VERSION "HNPBNNNYNNNNNNNNNNNNNNNNNNNNNNNNYNYYYYYYYY>4>%%%/4>'%**4YYY///"

NS_ :

BS_:

BU_: TPM TCM SCCM RF_HUB PTS ORC IC HaLF ETM ESM ESC EPS ECM Diagnost DTCM DASM CBC AFLS ADCM

BO_ 368 TRNS_STAT: 8 ECM
 SG_ PaddlesModeSts : 0|2@1+ (1,0) [0|0] ""  ESM,DASM,IC,CBC
 SG_ PRND_STAT : 2|3@1+ (1,0) [0|0] ""  HaLF,ORC,ESM,ECM,DASM,ESC,EPS,AFLS,TPM,PTS,IC,CBC,RF_HUB
 SG_ APCM_Rq : 5|2@1+ (1,0) [0|0] ""  IC
 SG_ EngStEnblRqTCM : 7|1@1+ (1,0) [0|0] ""  ECM
 SG_ SHFT_PROG : 8|8@1+ (1,0) [0|0] ""  ECM,DASM,ESC,IC,CBC
 SG_ PRNDL_DISP : 16|8@1+ (1,0) [0|0] ""  DTCM,ESM,ECM,ESC,IC,CBC
 SG_ R_SHFT_LOCK : 24|1@1+ (1,0) [0|0] ""  ESM
 SG_ TX_D_POSSIBLE : 25|1@1+ (1,0) [0|0] ""  IC
 SG_ TX_M_POSSIBLE : 28|1@1+ (1,0) [0|0] ""  IC
 SG_ SHFT_LOCK : 29|1@1+ (1,0) [0|0] ""  ESM
 SG_ SHFT_RESET : 30|1@1+ (1,0) [0|0] "" Vector__XXX
 SG_ SHFT_HS_TCM_VALID : 31|1@1+ (1,0) [0|0] "" Vector__XXX
 SG_ SHFT_HS1_TCM : 32|8@1+ (1,0) [0|0] "" Vector__XXX
 SG_ SHFT_HS2_TCM : 40|8@1+ (1,0) [0|0] "" Vector__XXX
 SG_ TxDisengaged : 48|1@1+ (1,0) [0|0] ""  ECM
 SG_ PRNDL_Blink : 49|3@1+ (1,0) [0|0] ""  ESM,ECM,IC
 SG_ MC_TRNS_STAT : 52|4@1+ (1,0) [0|15] ""  ORC,ESM,ECM,DASM
 SG_ CRC_TRNS_STAT : 56|8@1+ (1,0) [0|0] ""  ORC,ESM,ECM,DASM

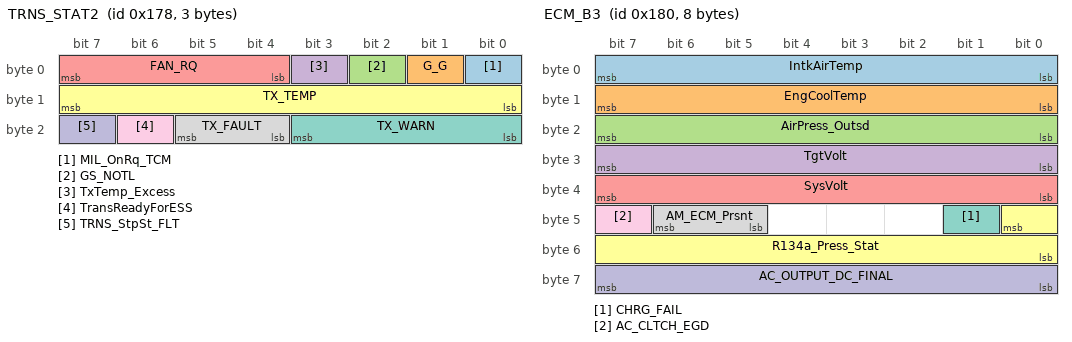
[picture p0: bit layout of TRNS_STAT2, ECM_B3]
BO_ 376 TRNS_STAT2: 3 ECM
 SG_ MIL_OnRq_TCM : 0|1@1+ (1,0) [0|0] ""  ECM,DASM,IC
 SG_ G_G : 1|1@1+ (1,0) [0|0] ""  ECM
 SG_ GS_NOTL : 2|1@1+ (1,0) [0|0] ""  ORC,ECM,DASM
 SG_ TxTemp_Excess : 3|1@1+ (1,0) [0|0] ""  ETM,ECM,IC
 SG_ FAN_RQ : 4|4@1+ (7.2,0) [0|100] "%"  ECM
 SG_ TX_TEMP : 8|8@1+ (1,-50) [-50|204] "°C"  ETM,DTCM,ECM,IC,CBC
 SG_ TX_WARN : 16|4@1+ (1,0) [0|0] ""  IC
 SG_ TX_FAULT : 20|2@1+ (1,0) [0|0] ""  ESM,RF_HUB
 SG_ TransReadyForESS : 22|1@1+ (1,0) [0|0] ""  ECM
 SG_ TRNS_StpSt_FLT : 23|1@1+ (1,0) [0|0] ""  ECM

BO_ 384 ECM_B3: 8 ECM
 SG_ IntkAirTemp : 0|8@1+ (1,-40) [-40|214] "°C"  ETM,ECM,CBC
 SG_ EngCoolTemp : 8|8@1+ (1,-40) [-40|214] "°C"  DTCM,TCM,ECM,ESC,PTS,IC,CBC
 SG_ AirPress_Outsd : 16|8@1+ (1,0) [0|254] "kPaA"  ETM,TCM,ECM,DASM,ESC,TPM,IC,RF_HUB
 SG_ TgtVolt : 24|8@1+ (0.0618,0) [0|15.6972] "Volts" Vector__XXX
 SG_ SysVolt : 32|8@1+ (0.0618,0) [0|15.6972] "Volts"  CBC
 SG_ R134a_Press_Stat : 40|9@0+ (0.1,0) [0|40] "bar"  CBC
 SG_ CHRG_FAIL : 41|1@1+ (1,0) [0|0] ""  ETM,ORC,IC
 SG_ AM_ECM_Prsnt : 45|2@1+ (1,0) [0|0] ""  CBC
 SG_ AC_CLTCH_EGD : 47|1@1+ (1,0) [0|0] ""  TCM,DASM,CBC
 SG_ AC_OUTPUT_DC_FINAL : 56|8@1+ (1,0) [0|100] "%"  CBC

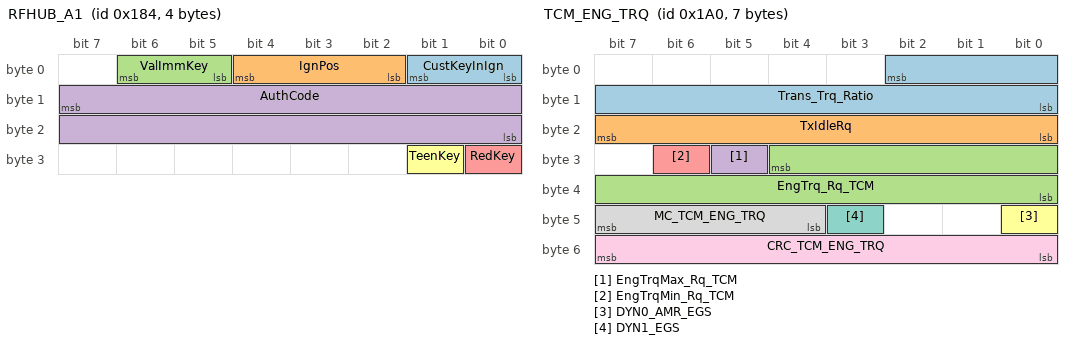
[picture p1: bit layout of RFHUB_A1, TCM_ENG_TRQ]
BO_ 388 RFHUB_A1: 4 RF_HUB
 SG_ CustKeyInIgn : 0|2@1+ (1,0) [0|0] ""  CBC
 SG_ IgnPos : 2|3@1+ (1,0) [0|0] ""  CBC
 SG_ ValImmKey : 5|2@1+ (1,0) [0|0] ""  CBC
 SG_ AuthCode : 15|16@0+ (1,0) [0|0] ""  CBC
 SG_ RedKey : 24|1@1+ (1,0) [0|0] ""  CBC
 SG_ TeenKey : 25|1@1+ (1,0) [0|0] ""  CBC

BO_ 416 TCM_ENG_TRQ: 7 ECM
 SG_ Trans_Trq_Ratio : 2|11@0+ (0.01,0) [0|20.46] ""  ECM,DASM,ESC
 SG_ TxIdleRq : 16|8@1+ (4,500) [500|1516] "rpm"  ECM,DASM,ESC
 SG_ EngTrq_Rq_TCM : 28|13@0+ (0.25,-500) [-500|1547.5] "Nm"  ECM,DASM,ESC
 SG_ EngTrqMax_Rq_TCM : 29|1@1+ (1,0) [0|0] ""  ECM,DASM,ESC
 SG_ EngTrqMin_Rq_TCM : 30|1@1+ (1,0) [0|0] ""  ECM,DASM,ESC
 SG_ DYN0_AMR_EGS : 40|1@1+ (1,0) [0|0] ""  ECM,DASM,ESC
 SG_ DYN1_EGS : 43|1@1+ (1,0) [0|0] ""  ECM,DASM,ESC
 SG_ MC_TCM_ENG_TRQ : 44|4@1+ (1,0) [0|15] ""  ECM,DASM,ESC
 SG_ CRC_TCM_ENG_TRQ : 48|8@1+ (1,0) [0|0] ""  ECM,DASM,ESC

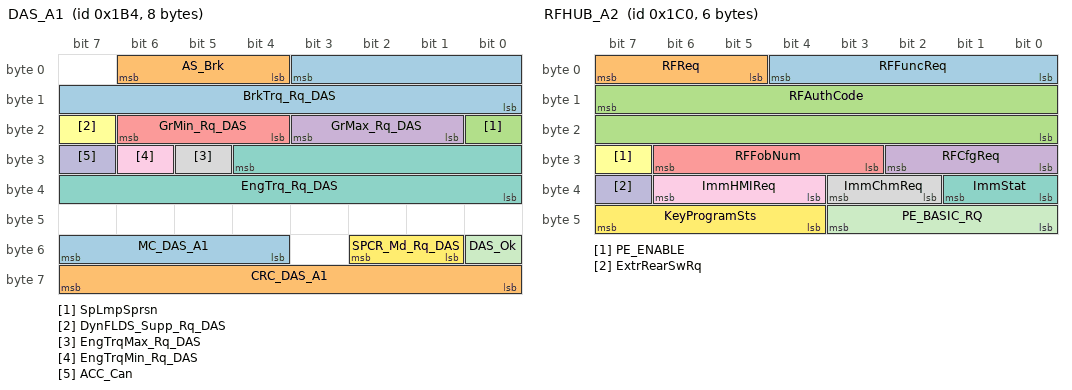
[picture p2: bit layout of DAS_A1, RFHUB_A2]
BO_ 436 DAS_A1: 8 Vector__XXX
 SG_ BrkTrq_Rq_DAS : 3|12@0+ (3,0) [0|12282] "Nm"  ESC
 SG_ AS_Brk : 4|3@1+ (1,0) [0|0] ""  ORC,ESC
 SG_ SpLmpSprsn : 16|1@1+ (1,0) [0|0] ""  ESC
 SG_ GrMax_Rq_DAS : 17|3@1+ (1,0) [0|0] ""  ORC,ESC
 SG_ GrMin_Rq_DAS : 20|3@1+ (1,0) [0|0] ""  ORC,ESC
 SG_ DynFLDS_Supp_Rq_DAS : 23|1@1+ (1,0) [0|0] ""  ORC,ESC
 SG_ EngTrq_Rq_DAS : 28|13@0+ (0.25,-500) [-500|1547.5] "Nm"  ORC,ESC
 SG_ EngTrqMax_Rq_DAS : 29|1@1+ (1,0) [0|0] ""  ORC,ESC
 SG_ EngTrqMin_Rq_DAS : 30|1@1+ (1,0) [0|0] ""  ORC,ESC
 SG_ ACC_Can : 31|1@1+ (1,0) [0|0] ""  ORC,ESC,IC
 SG_ DAS_Ok : 48|1@1+ (1,0) [0|0] ""  ORC,ESC
 SG_ SPCR_Md_Rq_DAS : 49|2@1+ (1,0) [0|0] ""  ORC,ESC
 SG_ MC_DAS_A1 : 52|4@1+ (1,0) [0|15] ""  ORC,ECM,ESC
 SG_ CRC_DAS_A1 : 56|8@1+ (1,0) [0|0] ""  ORC,ESC

BO_ 448 RFHUB_A2: 6 RF_HUB
 SG_ RFFuncReq : 0|5@1+ (1,0) [0|0] ""  CBC
 SG_ RFReq : 5|3@1+ (1,0) [0|0] ""  CBC
 SG_ RFAuthCode : 15|16@0+ (1,0) [0|0] ""  CBC
 SG_ RFCfgReq : 24|3@1+ (1,0) [0|0] ""  CBC
 SG_ RFFobNum : 27|4@1+ (1,0) [0|0] ""  CBC
 SG_ PE_ENABLE : 31|1@1+ (1,0) [0|0] ""  IC,CBC
 SG_ ImmStat : 32|2@1+ (1,0) [0|0] ""  ECM,CBC
 SG_ ImmChmReq : 34|2@1+ (1,0) [0|0] ""  IC,CBC
 SG_ ImmHMIReq : 36|3@1+ (1,0) [0|0] ""  CBC
 SG_ ExtrRearSwRq : 39|1@1+ (1,0) [0|0] ""  CBC
 SG_ PE_BASIC_RQ : 40|4@1+ (1,0) [0|0] ""  CBC
 SG_ KeyProgramSts : 44|4@1+ (1,0) [0|0] ""  IC,CBC

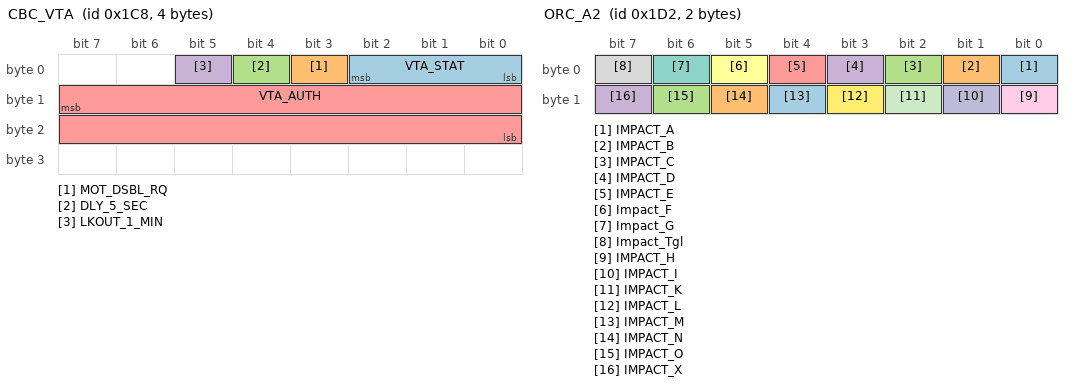
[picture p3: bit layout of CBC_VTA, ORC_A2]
BO_ 456 CBC_VTA: 4 CBC
 SG_ VTA_STAT : 0|3@1+ (1,0) [0|0] ""  ETM,RF_HUB
 SG_ MOT_DSBL_RQ : 3|1@1+ (1,0) [0|0] ""  ETM
 SG_ DLY_5_SEC : 4|1@1+ (1,0) [0|0] ""  ETM
 SG_ LKOUT_1_MIN : 5|1@1+ (1,0) [0|0] ""  ETM
 SG_ VTA_AUTH : 15|16@0+ (1,0) [0|0] ""  ETM,RF_HUB

BO_ 464 ORC_A1: 8 ORC
 SG_ EPP_FAULT : 0|1@1+ (1,0) [0|0] ""  ETM,IC,CBC
 SG_ ORC_A1_Tog : 1|1@1+ (1,0) [0|0] ""  DASM,CBC
 SG_ SRS_IndLmp_Rq : 2|2@1+ (1,0) [0|0] ""  ETM,IC,CBC
 SG_ DSBL_PSG_LMP : 4|1@1+ (1,0) [0|0] ""  ETM,IC,CBC
 SG_ PsngrBagSts : 5|2@1+ (1,0) [0|0] ""  ETM,CBC
 SG_ ORC_A1_Par : 7|1@1+ (1,0) [0|0] ""  DASM,CBC
 SG_ OC_P_ORC : 8|3@1+ (1,0) [0|0] ""  ETM,IC,CBC
 SG_ OC_P_Flt_ORC : 11|1@1+ (1,0) [0|0] ""  ETM,IC,CBC
 SG_ DrvSbltUnFltr : 13|3@1+ (1,0) [0|0] ""  ECM,CBC
 SG_ DRV_SEATBELT : 16|2@1+ (1,0) [0|0] ""  ETM,TCM,ECM,DASM,ESC,PTS,IC,CBC
 SG_ PSG_SEATBELT : 18|2@1+ (1,0) [0|0] ""  ETM,TCM,ECM,DASM,ESC,IC,CBC
 SG_ SBRDriverSeatConfigSts : 20|1@1+ (1,0) [0|0] ""  CBC
 SG_ SBRFtPsngrSeatConfigSts : 21|1@1+ (1,0) [0|0] ""  CBC
 SG_ OC_P_Fast_ORC : 24|2@1+ (1,0) [0|0] ""  ETM,DASM,IC,CBC
 SG_ PSG_ODS_STAT : 26|2@1+ (1,0) [0|0] ""  ETM,IC,CBC
 SG_ COD_Stat : 40|3@1+ (1,0) [0|0] ""  ETM,IC,CBC
 SG_ SRS_DtlMsg01_Disp_Rq : 48|1@1+ (1,0) [0|0] ""  ETM,IC,CBC
 SG_ SRS_DtlMsg02_Disp_Rq : 49|1@1+ (1,0) [0|0] ""  ETM,IC,CBC
 SG_ SRS_DtlMsg03_Disp_Rq : 50|1@1+ (1,0) [0|0] ""  ETM,IC,CBC
 SG_ SRS_DtlMsg04_Disp_Rq : 51|1@1+ (1,0) [0|0] ""  ETM,IC,CBC
 SG_ SRS_DtlMsg05_Disp_Rq : 52|1@1+ (1,0) [0|0] ""  ETM,IC,CBC
 SG_ SRS_DtlMsg06_Disp_Rq : 53|1@1+ (1,0) [0|0] ""  ETM,IC,CBC
 SG_ SRS_DtlMsg07_Disp_Rq : 54|1@1+ (1,0) [0|0] ""  ETM,IC,CBC
 SG_ SRS_DtlMsg08_Disp_Rq : 55|1@1+ (1,0) [0|0] ""  ETM,IC,CBC
 SG_ SRS_DtlMsg09_Disp_Rq : 56|1@1+ (1,0) [0|0] ""  ETM,IC,CBC
 SG_ SRS_DtlMsg10_Disp_Rq : 57|1@1+ (1,0) [0|0] ""  ETM,IC,CBC
 SG_ SRS_DtlMsg11_Disp_Rq : 58|1@1+ (1,0) [0|0] ""  ETM,IC,CBC
 SG_ SRS_DtlMsg12_Disp_Rq : 59|1@1+ (1,0) [0|0] ""  ETM,IC,CBC
 SG_ SRS_DtlMsg13_Disp_Rq : 60|1@1+ (1,0) [0|0] ""  ETM,IC,CBC
 SG_ SRS_DtlMsg14_Disp_Rq : 61|1@1+ (1,0) [0|0] ""  ETM,IC,CBC
 SG_ SRS_DtlMsg15_Disp_Rq : 62|1@1+ (1,0) [0|0] ""  ETM,IC,CBC
 SG_ SRS_DtlMsg16_Disp_Rq : 63|1@1+ (1,0) [0|0] ""  ETM,IC,CBC

BO_ 466 ORC_A2: 2 ORC
 SG_ IMPACT_A : 0|1@1+ (1,0) [0|0] ""  ETM,CBC
 SG_ IMPACT_B : 1|1@1+ (1,0) [0|0] ""  ETM,CBC
 SG_ IMPACT_C : 2|1@1+ (1,0) [0|0] ""  ETM,CBC
 SG_ IMPACT_D : 3|1@1+ (1,0) [0|0] ""  ETM,CBC
 SG_ IMPACT_E : 4|1@1+ (1,0) [0|0] ""  ETM,CBC
 SG_ Impact_F : 5|1@1+ (1,0) [0|0] ""  ETM,CBC
 SG_ Impact_G : 6|1@1+ (1,0) [0|0] ""  ETM,CBC
 SG_ Impact_Tgl : 7|1@1+ (1,0) [0|0] ""  ETM,ECM,CBC
 SG_ IMPACT_H : 8|1@1+ (1,0) [0|0] ""  ETM,CBC
 SG_ IMPACT_I : 9|1@1+ (1,0) [0|0] ""  ETM,CBC
 SG_ IMPACT_K : 10|1@1+ (1,0) [0|0] ""  ETM,CBC
 SG_ IMPACT_L : 11|1@1+ (1,0) [0|0] ""  ETM,CBC
 SG_ IMPACT_M : 12|1@1+ (1,0) [0|0] ""  ETM,CBC
 SG_ IMPACT_N : 13|1@1+ (1,0) [0|0] ""  ETM,CBC
 SG_ IMPACT_O : 14|1@1+ (1,0) [0|0] ""  ETM,CBC
 SG_ IMPACT_X : 15|1@1+ (1,0) [0|0] ""  ETM,ECM,IC,CBC

BO_ 468 DAS_A2: 8 Vector__XXX
 SG_ NormCruiseMode : 0|1@1+ (1,0) [0|0] ""  ORC,ESC,IC
 SG_ FCW_Sensitivity : 1|1@1+ (1,0) [0|0] ""  ORC,ESC,IC,CBC
 SG_ As_Disp_Rq : 2|2@1+ (1,0) [0|0] ""  ORC,IC
 SG_ ObjIntrst_Dtct : 6|1@1+ (1,0) [0|0] ""  ORC,IC
 SG_ DTR_Dspl_TmGap : 8|2@1+ (1,0) [0|0] ""  ORC,IC
 SG_ DTR_Ovr_D : 10|1@1+ (1,0) [0|0] ""  ORC,IC
 SG_ DTR_Disp_On_Rq : 11|1@1+ (1,0) [0|0] ""  ORC,IC
 SG_ DTR_CC_Enbl : 12|1@1+ (1,0) [0|0] ""  ORC,ESC,IC
 SG_ DTR_Engd : 13|1@1+ (1,0) [0|0] ""  ORC,ESC,IC,CBC
 SG_ Dist_D_Dsr : 16|8@1+ (1,0) [0|253] "m"  ORC,IC
 SG_ ObjIntrst_Dist : 24|8@1+ (1,0) [0|253] "m"  ORC,IC
 SG_ Sys_Dsbl : 32|3@1+ (1,0) [0|0] ""  ORC,ESC,IC
 SG_ FCW_Stat : 35|1@1+ (1,0) [0|0] ""  ORC,ESC,IC,CBC
 SG_ DTR_Spd_Dsr : 40|8@1+ (1,0) [0|250] "km/h(mph)"  ORC,ECM,IC
 SG_ DTR_FltDisp_Rq : 48|4@1+ (1,0) [0|0] ""  ORC,ESC,IC
 SG_ MC_DAS_A2 : 52|4@1+ (1,0) [0|15] ""  ORC,IC
 SG_ CRC_DAS_A2 : 56|8@1+ (1,0) [0|0] ""  ORC,IC

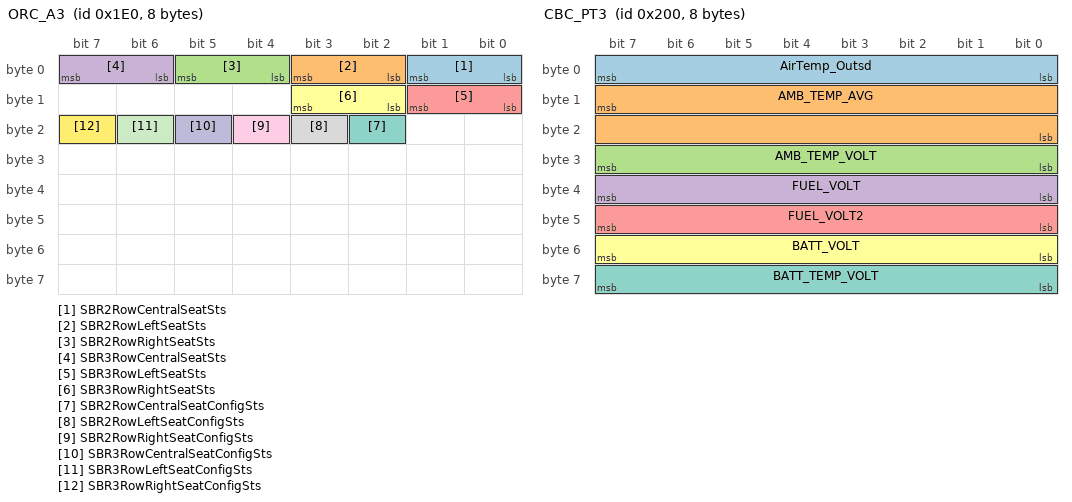
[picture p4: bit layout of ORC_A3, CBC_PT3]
BO_ 480 ORC_A3: 8 ORC
 SG_ SBR2RowCentralSeatSts : 0|2@1+ (1,0) [0|0] "" Vector__XXX
 SG_ SBR2RowLeftSeatSts : 2|2@1+ (1,0) [0|0] "" Vector__XXX
 SG_ SBR2RowRightSeatSts : 4|2@1+ (1,0) [0|0] "" Vector__XXX
 SG_ SBR3RowCentralSeatSts : 6|2@1+ (1,0) [0|0] "" Vector__XXX
 SG_ SBR3RowLeftSeatSts : 8|2@1+ (1,0) [0|0] "" Vector__XXX
 SG_ SBR3RowRightSeatSts : 10|2@1+ (1,0) [0|0] "" Vector__XXX
 SG_ SBR2RowCentralSeatConfigSts : 18|1@1+ (1,0) [0|0] "" Vector__XXX
 SG_ SBR2RowLeftSeatConfigSts : 19|1@1+ (1,0) [0|0] "" Vector__XXX
 SG_ SBR2RowRightSeatConfigSts : 20|1@1+ (1,0) [0|0] "" Vector__XXX
 SG_ SBR3RowCentralSeatConfigSts : 21|1@1+ (1,0) [0|0] "" Vector__XXX
 SG_ SBR3RowLeftSeatConfigSts : 22|1@1+ (1,0) [0|0] "" Vector__XXX
 SG_ SBR3RowRightSeatConfigSts : 23|1@1+ (1,0) [0|0] "" Vector__XXX

BO_ 500 DAS_A3: 8 DASM
 SG_ EngTrqRq_DAS : 4|13@0+ (0.25,-500) [-500|1547.5] "Nm"  ESC
 SG_ ACC_Still_Cmd : 5|1@1+ (1,0) [0|0] ""  ORC,ESC
 SG_ ACC_Drive_Cmd : 6|1@1+ (1,0) [0|0] ""  ORC,ESC
 SG_ EngTrqMaxRq_DAS : 7|1@1+ (1,0) [0|0] ""  ORC,ESC
 SG_ DAS_ACCEL_Rq : 19|12@0+ (0.004885,-16) [-16|4] "m/s²"  ORC,ESC
 SG_ ACC_Enbl : 20|1@1+ (1,0) [0|0] ""  ORC,ESC,IC
 SG_ ACC_Engd : 21|1@1+ (1,0) [0|0] ""  ORC,ESC,IC
 SG_ ACCFineCtrlDsbl : 22|1@1+ (1,0) [0|0] ""  ESC
 SG_ DsblFuelShutOff_ACC : 23|1@1+ (1,0) [0|0] ""  ESC
 SG_ GrMax_RqDAS : 32|4@1+ (1,0) [0|0] ""  ORC,ESC
 SG_ DAS_Rq_ID : 36|3@1+ (1,0) [0|0] ""  ORC,ESC
 SG_ AS_ChimeRq_RF : 40|1@1+ (1,0) [0|0] ""  CBC
 SG_ AS_ChimeRq_LF : 41|1@1+ (1,0) [0|0] ""  CBC
 SG_ AS_ChimeTyp : 42|4@1+ (1,0) [0|0] ""  ORC,IC,CBC
 SG_ DAS_Sts : 46|2@1+ (1,0) [0|0] ""  ESC
 SG_ Brk_Jrk_Rq : 48|1@1+ (1,0) [0|0] ""  ESC
 SG_ Brk_PreFill_Rq : 49|1@1+ (1,0) [0|0] ""  ORC,ESC
 SG_ As_DispRq : 50|2@1+ (1,0) [0|0] ""  ORC,ESC,IC
 SG_ MC_DAS_A3 : 52|4@1+ (1,0) [0|15] ""  ECM,ESC
 SG_ CRC_DAS_A3 : 56|8@1+ (1,0) [0|0] ""  ESC

BO_ 501 DAS_A4: 8 DASM
 SG_ HMI_Screens : 0|8@1+ (1,0) [0|254] "Text"  ORC,IC
 SG_ SetSpeed_KPH : 8|8@1+ (1,0) [0|250] "km/h"  ECM,IC
 SG_ SetSpeed_MPH : 16|8@1+ (1,0) [0|250] "mph"  ORC,IC
 SG_ FCW_Off : 24|2@1+ (1,0) [0|0] ""  CBC
 SG_ FCW_Error : 26|2@1+ (1,0) [0|0] ""  ORC,IC
 SG_ FCW_SetFar : 28|1@1+ (1,0) [0|0] ""  ORC,IC,CBC
 SG_ FCW_BrkOn : 29|1@1+ (1,0) [0|0] ""  ORC,IC,CBC
 SG_ CIPV_Fused : 30|1@1+ (1,0) [0|0] ""  ORC
 SG_ ACC_HMI_SCRN_REQ : 31|1@1+ (1,0) [0|0] ""  IC
 SG_ ISO_Display : 32|4@1+ (1,0) [0|0] ""  IC
 SG_ ACCOnOff : 36|3@1+ (1,0) [0|0] ""  ORC,IC
 SG_ Sm_ICON_Dspl : 40|6@1+ (1,0) [0|0] ""  IC
 SG_ RadarBlocked : 46|1@1+ (1,0) [0|0] ""  ORC,IC
 SG_ FCWBrakingOff : 47|1@1+ (1,0) [0|0] ""  ORC,IC
 SG_ ACConlyNA_DASMSts : 48|1@1+ (1,0) [0|0] ""  IC
 SG_ NCConlyNA_DASMSts : 49|1@1+ (1,0) [0|0] ""  IC
 SG_ ACCFaulted : 50|1@1+ (1,0) [0|0] ""  ORC,IC
 SG_ FCWonlyNA_DASMSts : 51|1@1+ (1,0) [0|0] "" Vector__XXX
 SG_ ACCNA_DASMSts : 52|1@1+ (1,0) [0|0] ""  ORC,IC
 SG_ NCCNA_DASMSts : 53|1@1+ (1,0) [0|0] ""  ORC,IC
 SG_ CameraBlocked : 54|1@1+ (1,0) [0|0] ""  ORC,IC
 SG_ CameraFailure : 55|1@1+ (1,0) [0|0] ""  ORC,IC
 SG_ ObjIntrstDist : 56|8@1+ (1,0) [0|253] "m"  ORC

BO_ 512 CBC_PT3: 8 CBC
 SG_ AirTemp_Outsd : 0|8@1+ (0.5,-40) [-40|85] "°C"  EPS,ORC,DTCM,ECM,DASM,TPM,PTS,IC
 SG_ AMB_TEMP_AVG : 15|16@0+ (0.01,-40) [-40|85] "°C"  EPS,ORC,TCM,ECM,DASM,ESC,TPM,PTS,IC,RF_HUB
 SG_ AMB_TEMP_VOLT : 24|8@1+ (0.019607843,0) [0|4.98] "Volts"  ORC,ECM
 SG_ FUEL_VOLT : 32|8@1+ (0.019607843,0) [0|4.98] "Volts"  ECM,IC
 SG_ FUEL_VOLT2 : 40|8@1+ (0.019607843,0) [0|4.98] "Volts"  ECM,IC
 SG_ BATT_VOLT : 48|8@1+ (0.1,0) [5|18] "Volts"  HaLF,ORC,DTCM,ESM,TCM,DASM,ESC,SCCM,EPS,AFLS,TPM,PTS,IC,RF_HUB
 SG_ BATT_TEMP_VOLT : 56|8@1+ (0.019607843,0) [0|4.98] "Volts"  ECM

BO_ 514 WHEEL_SPEED_2: 8 ESC
 SG_ WheelRPM_FL : 7|16@0+ (0.001953125,0) [0|127.9961] "Rev/s"  EPS
 SG_ WheelRPM_FR : 23|16@0+ (0.001953125,0) [0|127.9961] "Rev/s"  EPS

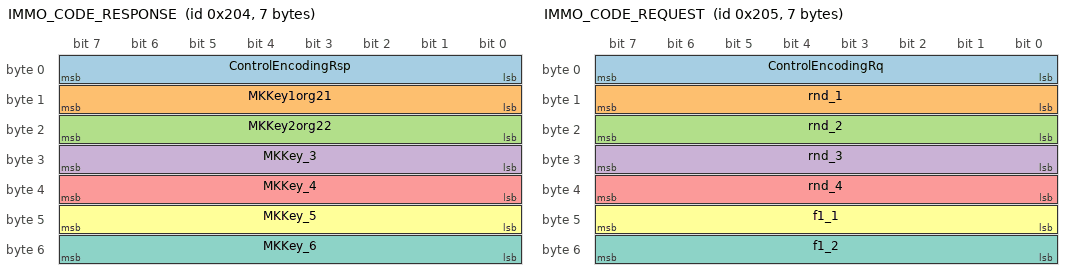
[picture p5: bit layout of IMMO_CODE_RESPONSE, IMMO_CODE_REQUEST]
BO_ 516 IMMO_CODE_RESPONSE: 7 CBC
 SG_ ControlEncodingRsp : 0|8@1+ (1,0) [0|0] ""  ECM
 SG_ MKKey1org21 : 8|8@1+ (1,0) [0|255] ""  ECM
 SG_ MKKey2org22 : 16|8@1+ (1,0) [0|255] ""  ECM
 SG_ MKKey_3 : 24|8@1+ (1,0) [0|255] ""  ECM
 SG_ MKKey_4 : 32|8@1+ (1,0) [0|255] ""  ECM
 SG_ MKKey_5 : 40|8@1+ (1,0) [0|255] ""  ECM
 SG_ MKKey_6 : 48|8@1+ (1,0) [0|255] ""  ECM

BO_ 517 IMMO_CODE_REQUEST: 7 ECM
 SG_ ControlEncodingRq : 0|8@1+ (1,0) [0|0] ""  CBC
 SG_ rnd_1 : 8|8@1+ (1,0) [0|255] ""  CBC
 SG_ rnd_2 : 16|8@1+ (1,0) [0|255] ""  CBC
 SG_ rnd_3 : 24|8@1+ (1,0) [0|255] ""  CBC
 SG_ rnd_4 : 32|8@1+ (1,0) [0|255] ""  CBC
 SG_ f1_1 : 40|8@1+ (1,0) [0|255] ""  CBC
 SG_ f1_2 : 48|8@1+ (1,0) [0|255] ""  CBC

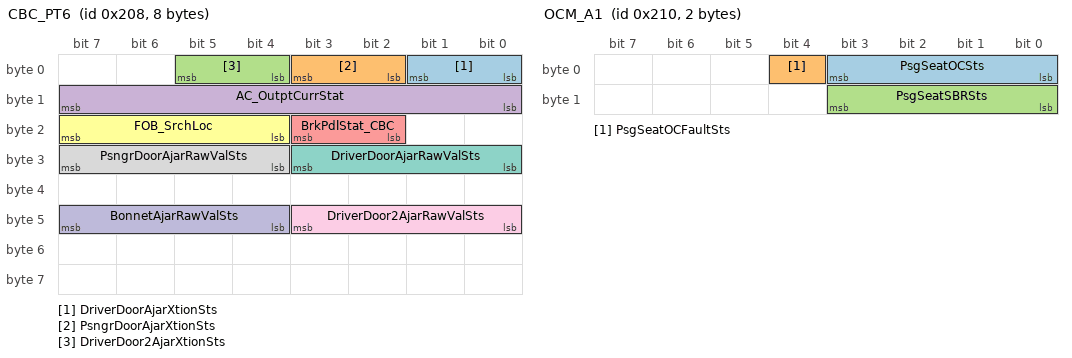
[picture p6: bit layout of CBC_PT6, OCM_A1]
BO_ 520 CBC_PT6: 8 CBC
 SG_ DriverDoorAjarXtionSts : 0|2@1+ (1,0) [0|0] ""  TCM,ECM,ESC,PTS
 SG_ PsngrDoorAjarXtionSts : 2|2@1+ (1,0) [0|0] ""  TCM,ECM,ESC,PTS
 SG_ DriverDoor2AjarXtionSts : 4|2@1+ (1,0) [0|0] ""  TCM,ECM,ESC
 SG_ AC_OutptCurrStat : 8|8@1+ (0.008,0) [0|2] "Amp"  ECM
 SG_ BrkPdlStat_CBC : 18|2@1+ (1,0) [0|0] ""  RF_HUB
 SG_ FOB_SrchLoc : 20|4@1+ (1,0) [0|0] ""  RF_HUB
 SG_ DriverDoorAjarRawValSts : 24|4@1+ (1,0) [0|0] ""  ORC,TCM,ECM,DASM,ESC,PTS
 SG_ PsngrDoorAjarRawValSts : 28|4@1+ (1,0) [0|0] ""  ORC,TCM,ECM,ESC,PTS
 SG_ DriverDoor2AjarRawValSts : 40|4@1+ (1,0) [0|0] ""  TCM,ECM,ESC
 SG_ BonnetAjarRawValSts : 44|4@1+ (1,0) [0|0] ""  ORC,TCM,ECM,DASM,ESC,PTS

BO_ 528 OCM_A1: 2 Vector__XXX
 SG_ PsgSeatOCSts : 0|4@1+ (1,0) [0|0] ""  ORC
 SG_ PsgSeatOCFaultSts : 4|1@1+ (1,0) [0|0] ""  ORC
 SG_ PsgSeatSBRSts : 8|4@1+ (1,0) [0|0] ""  ORC

CM_ SG_ 368 PaddlesModeSts "Status of paddle functionality";
CM_ SG_ 368 PRND_STAT "PRND Status";
CM_ SG_ 368 APCM_Rq "Auto position correction mode request";
CM_ SG_ 368 EngStEnblRqTCM "Engine start enable request from the transmission";
CM_ SG_ 368 SHFT_PROG "Driving program display code";
CM_ SG_ 368 PRNDL_DISP "PRNDL display request";
CM_ SG_ 368 R_SHFT_LOCK "Shiftlock for reverse; locked = [1]";
CM_ SG_ 368 TX_D_POSSIBLE "Engage gear D possible";
CM_ SG_ 368 TX_M_POSSIBLE "Move to A/S possible";
CM_ SG_ 368 SHFT_LOCK "Shiftlock state locked; false = [1]";
CM_ SG_ 368 SHFT_RESET "Reset Shifter; true = [1]";
CM_ SG_ 368 SHFT_HS_TCM_VALID "Handshake testparameter valid (TCU to SBWM); true = [1]";
CM_ SG_ 368 SHFT_HS1_TCM "Handshake testparameter 1(TCM to SBWM)";
CM_ SG_ 368 SHFT_HS2_TCM "Handshake testparameter 2(TCM to SBWM)";
CM_ SG_ 368 TxDisengaged "Transmission disengaged";
CM_ SG_ 368 PRNDL_Blink "Request gear shift display indicator blink";
CM_ SG_ 368 MC_TRNS_STAT "Message counter";
CM_ SG_ 368 CRC_TRNS_STAT "CRC-checksum byte 1 to 7 according to SAE J1850";
CM_ SG_ 376 MIL_OnRq_TCM "MIL on request from the transmission";
CM_ SG_ 376 G_G "Transfer case range; hi range = [0], low range = [1].";
CM_ SG_ 376 GS_NOTL "TRANS in limp home mode";
CM_ SG_ 376 TxTemp_Excess "Excessive transmission temperature";
CM_ SG_ 376 FAN_RQ "Cooling fan request";
CM_ SG_ 376 TX_TEMP "Transmission fluid temperature";
CM_ SG_ 376 TX_WARN "Transmission warning";
CM_ SG_ 376 TX_FAULT "Transmission fault";
CM_ SG_ 376 TransReadyForESS "Trans ready for auto stop (0= not ready)";
CM_ SG_ 376 TRNS_StpSt_FLT "Trans stop start fault (1=fault)";
CM_ SG_ 384 IntkAirTemp "Engine Intake Air Temperature";
CM_ SG_ 384 EngCoolTemp "Engine coolant temperature";
CM_ SG_ 384 AirPress_Outsd "Ambient air pressure (barometric pressure)";
CM_ SG_ 384 TgtVolt "Engine target voltage";
CM_ SG_ 384 SysVolt "Engine system voltage";
CM_ SG_ 384 R134a_Press_Stat "Refrigerant pressure (R134a or R1234YF)";
CM_ SG_ 384 CHRG_FAIL "Charging system Failure (battery indicator request)";
CM_ SG_ 384 AM_ECM_Prsnt "Aftermarket ECM present";
CM_ SG_ 384 AC_CLTCH_EGD "AC clutch engauged";
CM_ SG_ 384 AC_OUTPUT_DC_FINAL "Variable A/C Compressor Duty Cycle";
CM_ SG_ 388 CustKeyInIgn "Driver's request, key-in-ignition";
CM_ SG_ 388 IgnPos "Drivers request, ignition position";
CM_ SG_ 388 ValImmKey "Drivers request, immobilizer results";
CM_ SG_ 388 AuthCode "Authorization code used for immobilizer";
CM_ SG_ 388 RedKey "Red key present; Present = [1]";
CM_ SG_ 388 TeenKey "Teen key present; Present = [1]";
CM_ SG_ 416 Trans_Trq_Ratio "Transmission torque ratio";
CM_ SG_ 416 TxIdleRq "Transmission idle speed request";
CM_ SG_ 416 EngTrq_Rq_TCM "Engine torque request";
CM_ SG_ 416 EngTrqMax_Rq_TCM "Engine torque request maximum";
CM_ SG_ 416 EngTrqMin_Rq_TCM "Engine torque request minimum";
CM_ SG_ 416 DYN0_AMR_EGS "Engine torque control mode/drive torque regulation";
CM_ SG_ 416 DYN1_EGS "Engine torque control mode";
CM_ SG_ 416 MC_TCM_ENG_TRQ "Message counter";
CM_ SG_ 416 CRC_TCM_ENG_TRQ "CRC-checksum byte 1 to 6 according to SAE J1850";
CM_ SG_ 436 BrkTrq_Rq_DAS "Brake torque request";
CM_ SG_ 436 AS_Brk "Braking assistance system";
CM_ SG_ 436 SpLmpSprsn "Stop lamp suppression; True = [1]";
CM_ SG_ 436 GrMax_Rq_DAS "Requested gear, upper limit";
CM_ SG_ 436 GrMin_Rq_DAS "Requested gear, lower limit";
CM_ SG_ 436 DynFLDS_Supp_Rq_DAS "Suppression full load down shift; True = [1]";
CM_ SG_ 436 EngTrq_Rq_DAS "Engine torque request";
CM_ SG_ 436 EngTrqMax_Rq_DAS "Engine torque request maximum; True = [1]";
CM_ SG_ 436 EngTrqMin_Rq_DAS "Engine torque request minimum; True = [1]";
CM_ SG_ 436 ACC_Can "ACC is cancelled by driver (X-by-Wire); True = [1]";
CM_ SG_ 436 DAS_Ok "Status Information DASM is ok; True = [1]";
CM_ SG_ 436 SPCR_Md_Rq_DAS "Stop coordinator mode request";
CM_ SG_ 436 MC_DAS_A1 "Message counter";
CM_ SG_ 436 CRC_DAS_A1 "CRC-checksum byte 1 to 7 according to SAE J1850";
CM_ SG_ 448 RFFuncReq "Basic request (RKE, PE, Remstart)";
CM_ SG_ 448 RFReq "Who's asking for the request";
CM_ SG_ 448 RFAuthCode "Authorization for requests";
CM_ SG_ 448 RFCfgReq "Change customer programmable items by RKE";
CM_ SG_ 448 RFFobNum "FOB number making the request";
CM_ SG_ 448 PE_ENABLE "Passive entry feature enabled; [1] = True";
CM_ SG_ 448 ImmStat "Immobilizer status for engine controller";
CM_ SG_ 448 ImmChmReq "Chime request for security system master";
CM_ SG_ 448 ImmHMIReq "Immobilizer status light request";
CM_ SG_ 448 ExtrRearSwRq "External rear switch request";
CM_ SG_ 448 PE_BASIC_RQ "Passive Entry Lock/Unlock/Unlatch Request";
CM_ SG_ 448 KeyProgramSts "Key programming status";
CM_ SG_ 456 VTA_STAT "VTA status";
CM_ SG_ 456 MOT_DSBL_RQ "Motion detection disable request";
CM_ SG_ 456 DLY_5_SEC "5 seconds alarm delay";
CM_ SG_ 456 LKOUT_1_MIN "Lock out 1 minute";
CM_ SG_ 456 VTA_AUTH "2 byte VTA authorization";
CM_ SG_ 464 EPP_FAULT "Pedestrian protection ORC fault; True = [1]";
CM_ SG_ 464 ORC_A1_Tog "ORC_A1 toggle bit";
CM_ SG_ 464 SRS_IndLmp_Rq "SRS indication lamp request";
CM_ SG_ 464 DSBL_PSG_LMP "Disable passenger airbag lamp; on=[1]";
CM_ SG_ 464 PsngrBagSts "Passenger Airbag Status";
CM_ SG_ 464 ORC_A1_Par "ORC_A1 even parity bit";
CM_ SG_ 464 OC_P_ORC "Occupant classification passenger";
CM_ SG_ 464 OC_P_Flt_ORC "Passenger occupant classification fault; True = [1]";
CM_ SG_ 464 DrvSbltUnFltr "Drivers seat belt fault status - unfiltered";
CM_ SG_ 464 DRV_SEATBELT "Drivers seat belt status";
CM_ SG_ 464 PSG_SEATBELT "Passengers seat belt status";
CM_ SG_ 464 SBRDriverSeatConfigSts "Driver seatbelt switch configuration; seat checked = [1]";
CM_ SG_ 464 SBRFtPsngrSeatConfigSts "Front passenger seatbelt switch configuration; seat checked = [1]";
CM_ SG_ 464 OC_P_Fast_ORC "Occupant detection passenger fast [MGCG only]";
CM_ SG_ 464 PSG_ODS_STAT "Passenger Occupant Detection Sensor Status";
CM_ SG_ 464 COD_Stat "Child seat detection state";
CM_ SG_ 464 SRS_DtlMsg01_Disp_Rq "SRS detail message 'Go to Workshop' display request; True = [1]";
CM_ SG_ 464 SRS_DtlMsg02_Disp_Rq "SRS detail message 'Driver Malfunction' display request; True = [1]";
CM_ SG_ 464 SRS_DtlMsg03_Disp_Rq "SRS detail message 'Passenger Malfunction' display request; True = [1]";
CM_ SG_ 464 SRS_DtlMsg04_Disp_Rq "SRS detail message 'Rear Left Malfunction' display request; True = [1]";
CM_ SG_ 464 SRS_DtlMsg05_Disp_Rq "SRS detail message 'Rear Center Malfunction' display request; True = [1]";
CM_ SG_ 464 SRS_DtlMsg06_Disp_Rq "SRS detail message 'Rear Right Malfunction' display request; True = [1]";
CM_ SG_ 464 SRS_DtlMsg07_Disp_Rq "SRS detail message '3rd Row Left Malfunction' display request; True = [1]";
CM_ SG_ 464 SRS_DtlMsg08_Disp_Rq "SRS detail message '3rd Row Center Malfunction' display request; True = [1]";
CM_ SG_ 464 SRS_DtlMsg09_Disp_Rq "SRS detail message '3rd Row Right Malfunction' display request; True = [1]";
CM_ SG_ 464 SRS_DtlMsg10_Disp_Rq "SRS detail message 'Curtain Airbag Left Malfunction' display request; True = [1]";
CM_ SG_ 464 SRS_DtlMsg11_Disp_Rq "SRS detail message 'Curtain Airbag Right Malfunction' display request; True = [1]";
CM_ SG_ 464 SRS_DtlMsg12_Disp_Rq "SRS detail message 'Childseat Position Wrong' display request; True = [1]";
CM_ SG_ 464 SRS_DtlMsg13_Disp_Rq "SRS detail message #13 display request; True = [1]";
CM_ SG_ 464 SRS_DtlMsg14_Disp_Rq "SRS detail message #14 display request; True = [1]";
CM_ SG_ 464 SRS_DtlMsg15_Disp_Rq "SRS detail message #15 display request; True = [1]";
CM_ SG_ 464 SRS_DtlMsg16_Disp_Rq "SRS detail message #16 display request; True = [1]";
CM_ SG_ 466 IMPACT_A "Front pretensioner event; actuate = [1]; do_not_actuate = [0]";
CM_ SG_ 466 IMPACT_B "EARS Rear Event; actuate = [1]; do_not_actuate = [0]";
CM_ SG_ 466 IMPACT_C "Front Event; actuate = [1]; do_not_actuate = [0]";
CM_ SG_ 466 IMPACT_D "Side Event; actuate = [1]; do_not_actuate = [0]";
CM_ SG_ 466 IMPACT_E "Rear Event; actuate = [1]; do_not_actuate = [0]";
CM_ SG_ 466 Impact_F "EARS Front Event; actuate = [1]; do_not_actuate = [0]";
CM_ SG_ 466 Impact_G "Not used; actuate = [1]; do_not_actuate = [0]";
CM_ SG_ 466 Impact_Tgl "Toggle bit for all impact events; actuate = [1]; do_not_actuate = [0]";
CM_ SG_ 466 IMPACT_H "Non-EARS Rollover Event; actuate = [1]; do_not_actuate = [0]";
CM_ SG_ 466 IMPACT_I "EARS Rollover Event; actuate = [1]; do_not_actuate = [0]";
CM_ SG_ 466 IMPACT_K "Driver side event; actuate = [1]; do_not_actuate = [0]";
CM_ SG_ 466 IMPACT_L "EARS Side Event; actuate = [1]; do_not_actuate = [0]";
CM_ SG_ 466 IMPACT_M "Passenger side event; actuate = [1]; do_not_actuate = [0]";
CM_ SG_ 466 IMPACT_N "Not used; actuate = [1]; do_not_actuate = [0]";
CM_ SG_ 466 IMPACT_O "Pedestrian crash event; actuate = [1]; do_not_actuate = [0]";
CM_ SG_ 466 IMPACT_X "Any impact event; actuate = [1]; do_not_actuate = [0]";
CM_ SG_ 468 NormCruiseMode "Normal Cruise Mode; True = [1]";
CM_ SG_ 468 FCW_Sensitivity "Forward collision warning sensitivity setting; 0=Low, 1=High";
CM_ SG_ 468 As_Disp_Rq "AS display request";
CM_ SG_ 468 ObjIntrst_Dtct "Object of interest detected; True = [1]";
CM_ SG_ 468 DTR_Dspl_TmGap "Displayed time gap";
CM_ SG_ 468 DTR_Ovr_D "DTR overridden by driver; True = [1]";
CM_ SG_ 468 DTR_Disp_On_Rq "DTR display on request; True = [1]";
CM_ SG_ 468 DTR_CC_Enbl "DTR cruise control enabled; True = [1]";
CM_ SG_ 468 DTR_Engd "DTR engaged; True = [1]";
CM_ SG_ 468 Dist_D_Dsr "Desired distance";
CM_ SG_ 468 ObjIntrst_Dist "Object of interest distance";
CM_ SG_ 468 Sys_Dsbl "System disable";
CM_ SG_ 468 FCW_Stat "FCW Status (0 = ON / 1 = OFF)";
CM_ SG_ 468 DTR_Spd_Dsr "Desired DTR speed";
CM_ SG_ 468 DTR_FltDisp_Rq "DTR fault display request";
CM_ SG_ 468 MC_DAS_A2 "Message counter";
CM_ SG_ 468 CRC_DAS_A2 "CRC-checksum byte 1 to 7 according to SAE J1850";
CM_ SG_ 480 SBR2RowCentralSeatSts "Second row central seatbelt switch status";
CM_ SG_ 480 SBR2RowLeftSeatSts "Second row left seatbelt switch status";
CM_ SG_ 480 SBR2RowRightSeatSts "Second row right seatbelt switch status";
CM_ SG_ 480 SBR3RowCentralSeatSts "Third row central seatbelt switch status";
CM_ SG_ 480 SBR3RowLeftSeatSts "Third row left seatbelt switch status";
CM_ SG_ 480 SBR3RowRightSeatSts "Third row right seatbelt switch status";
CM_ SG_ 480 SBR2RowCentralSeatConfigSts "Second row central seatbelt switch configuration; Seat checked = [1]";
CM_ SG_ 480 SBR2RowLeftSeatConfigSts "Second row left seatbelt switch configuration; Seat checked = [1]";
CM_ SG_ 480 SBR2RowRightSeatConfigSts "Second row right seatbelt switch configuration; Seat checked = [1]";
CM_ SG_ 480 SBR3RowCentralSeatConfigSts "Third row central seatbelt switch configuration; Seat checked = [1]";
CM_ SG_ 480 SBR3RowLeftSeatConfigSts "Third row left seatbelt switch configuration; Seat checked = [1]";
CM_ SG_ 480 SBR3RowRightSeatConfigSts "Third row right seatbelt switch configuration; Seat checked = [1]";
CM_ SG_ 500 EngTrqRq_DAS "Requested engine torque";
CM_ SG_ 500 ACC_Still_Cmd "ACC stop commanded; True = [1]";
CM_ SG_ 500 ACC_Drive_Cmd "ACC drive off commanded; True = [1]";
CM_ SG_ 500 EngTrqMaxRq_DAS "Engine torque request maximum; True = [1]";
CM_ SG_ 500 DAS_ACCEL_Rq "DASM acceleration request";
CM_ SG_ 500 ACC_Enbl "ACC cruise control enabled; True = [1]";
CM_ SG_ 500 ACC_Engd "ACC engaged; True = [1]";
CM_ SG_ 500 ACCFineCtrlDsbl "Disable fine control for ACC system; True = [1]";
CM_ SG_ 500 DsblFuelShutOff_ACC "Disable fuel shutoff; True = [1]";
CM_ SG_ 500 GrMax_RqDAS "Requested gear, upper limit";
CM_ SG_ 500 DAS_Rq_ID "DAS request ID";
CM_ SG_ 500 AS_ChimeRq_RF "AS right front chime on request; True = [1]";
CM_ SG_ 500 AS_ChimeRq_LF "AS left front chime on request; True = [1]";
CM_ SG_ 500 AS_ChimeTyp "AS chime type";
CM_ SG_ 500 DAS_Sts "DASM fault status";
CM_ SG_ 500 Brk_Jrk_Rq "Brake jerk request; True = [1]";
CM_ SG_ 500 Brk_PreFill_Rq "Brakes pre-fill request; True = [1]";
CM_ SG_ 500 As_DispRq "Assistance system display request (priority)";
CM_ SG_ 500 MC_DAS_A3 "Message counter";
CM_ SG_ 500 CRC_DAS_A3 "CRC-checksum byte 1 to 7 according to SAE J1850";
CM_ SG_ 501 HMI_Screens "HMI screens";
CM_ SG_ 501 SetSpeed_KPH "Desired set speed in kilometers per hour";
CM_ SG_ 501 SetSpeed_MPH "Desired set speed in miles per hour";
CM_ SG_ 501 FCW_Off "Forward collision warning off status";
CM_ SG_ 501 FCW_Error "Forward collision warning error";
CM_ SG_ 501 FCW_SetFar "Forward collision warning setting is far; true = [1]";
CM_ SG_ 501 FCW_BrkOn "FCW braking is on; true = [1]";
CM_ SG_ 501 CIPV_Fused "Closest in-path vehicle is fused; True = [1]";
CM_ SG_ 501 ACC_HMI_SCRN_REQ "ACC HMI Screen request. Display HMI screen when [1]";
CM_ SG_ 501 ISO_Display "Displays ISO symbols";
CM_ SG_ 501 ACCOnOff "ACC on off status";
CM_ SG_ 501 Sm_ICON_Dspl "Small graphic display";
CM_ SG_ 501 RadarBlocked "ACC FCW not available: clean radar snsr; True = [1]";
CM_ SG_ 501 FCWBrakingOff "FCW autobraking disabled; True = [1]";
CM_ SG_ 501 ACConlyNA_DASMSts "ACC only not available: vehicle system error; True = [1]";
CM_ SG_ 501 NCConlyNA_DASMSts "NCC only not available: vehicle system error; True = [1]";
CM_ SG_ 501 ACCFaulted "ACC faulted; True = [1]";
CM_ SG_ 501 FCWonlyNA_DASMSts "FCW only not available: vehicle system error; True = [1]";
CM_ SG_ 501 ACCNA_DASMSts "ACC/FCW not avail: vehicle system error; True = [1]";
CM_ SG_ 501 NCCNA_DASMSts "NCC/FCW not avail: vehicle system error; True = [1]";
CM_ SG_ 501 CameraBlocked "ACC FCW limited functionality: camera blocked; True = [1]";
CM_ SG_ 501 CameraFailure "ACC/FCW limited functionality: camera failure; True = [1]";
CM_ SG_ 501 ObjIntrstDist "Object of interest distance";
CM_ SG_ 512 AirTemp_Outsd "Outside air temperature";
CM_ SG_ 512 AMB_TEMP_AVG "Averaged ambient temperature";
CM_ SG_ 512 AMB_TEMP_VOLT "Ambient Temp Sensor A/D Voltage";
CM_ SG_ 512 FUEL_VOLT "Fuel level A/D Voltage (Single tank OR Primary on Saddle/Dual Tank)";
CM_ SG_ 512 FUEL_VOLT2 "Sub Side Fuel level sensor A/D Voltage (saddle/Dual tank)";
CM_ SG_ 512 BATT_VOLT "System voltage";
CM_ SG_ 512 BATT_TEMP_VOLT "Batt. Temp Sensor A/D Voltage";
CM_ SG_ 514 WheelRPM_FL "Wheel RPM front left";
CM_ SG_ 514 WheelRPM_FR "Wheel RPM front right";
CM_ SG_ 516 ControlEncodingRsp "Control encoding - response";
CM_ SG_ 516 MKKey1org21 "Mini kript key 1 or G2_1";
CM_ SG_ 516 MKKey2org22 "Mini kript key 2 or G2_2";
CM_ SG_ 516 MKKey_3 "Mini kript key 3";
CM_ SG_ 516 MKKey_4 "Mini kript key 4";
CM_ SG_ 516 MKKey_5 "Mini kript key 5";
CM_ SG_ 516 MKKey_6 "Mini kript key 6";
CM_ SG_ 517 ControlEncodingRq "Control encoding - request";
CM_ SG_ 517 rnd_1 "Random number 1";
CM_ SG_ 517 rnd_2 "Random number 2";
CM_ SG_ 517 rnd_3 "Random number 3";
CM_ SG_ 517 rnd_4 "Random number 4";
CM_ SG_ 517 f1_1 "F code 1_1";
CM_ SG_ 517 f1_2 "F code 1_2";
CM_ SG_ 520 DriverDoorAjarXtionSts "Drivers door ajar transition status";
CM_ SG_ 520 PsngrDoorAjarXtionSts "Front passenger door ajar transition status";
CM_ SG_ 520 DriverDoor2AjarXtionSts "Drivers door switch - 2 ajar transition status";
CM_ SG_ 520 AC_OutptCurrStat "AC output current status";
CM_ SG_ 520 BrkPdlStat_CBC "Brake pedal state reported by CBC";
CM_ SG_ 520 FOB_SrchLoc "FOB search request by specified location.";
CM_ SG_ 520 DriverDoorAjarRawValSts "Drivers door ajar status";
CM_ SG_ 520 PsngrDoorAjarRawValSts "Passengers door ajar status";
CM_ SG_ 520 DriverDoor2AjarRawValSts "Drivers door switch - 2 ajar status";
CM_ SG_ 520 BonnetAjarRawValSts "Hood ajar status";
CM_ SG_ 528 PsgSeatOCSts "Occupant classification passenger";
CM_ SG_ 528 PsgSeatOCFaultSts "Passenger occupant classification fault; True = [1]";
CM_ SG_ 528 PsgSeatSBRSts "Passenger seatbelt reminder status";
BA_DEF_ SG_  "GenSigTimeout_ADCM" INT 0 65535;
BA_DEF_ SG_  "GenSigTimeout_AFLS" INT 0 65535;
BA_DEF_ SG_  "GenSigTimeout_CBC" INT 0 65535;
BA_DEF_ SG_  "GenSigTimeout_DTCM" INT 0 65535;
BA_DEF_ SG_  "GenSigTimeout_ECM" INT 0 65535;
BA_DEF_ SG_  "GenSigTimeout_EPS" INT 0 65535;
BA_DEF_ SG_  "GenSigTimeout_ESC" INT 0 65535;
BA_DEF_ SG_  "GenSigTimeout_ESM" INT 0 65535;
BA_DEF_ SG_  "GenSigTimeout_ETM" INT 0 65535;
BA_DEF_ SG_  "GenSigTimeout_HaLF" INT 0 65535;
BA_DEF_ SG_  "GenSigTimeout_IC" INT 0 65535;
BA_DEF_ SG_  "GenSigTimeout_ORC" INT 0 65535;
BA_DEF_ SG_  "GenSigTimeout_PTS" INT 0 65535;
BA_DEF_ SG_  "GenSigTimeout_RF_HUB" INT 0 65535;
BA_DEF_ SG_  "GenSigTimeout_SCCM" INT 0 65535;
BA_DEF_ SG_  "GenSigTimeout_TPM" INT 0 65535;
BA_DEF_ BO_  "GenMsgStartValue" STRING ;
BA_DEF_ SG_  "GenSigSNA" STRING ;
BA_DEF_ SG_  "FlexKomIsMotorola" ENUM  "nein","ja";
BA_DEF_ SG_  "FlexKomSigLaenge" INT 0 64;
BA_DEF_ SG_  "FlexKomSigStartPos" INT 0 63;
BA_DEF_ SG_  "FlexKomComment" STRING ;
BA_DEF_ SG_  "FlexKomSigName" STRING ;
BA_DEF_ SG_  "FlexKomSID" INT 0 2147483647;
BA_DEF_ SG_  "GenSigStartValue" HEX 0 4294967295;
BA_DEF_ SG_  "FlexKomSigStartValue" STRING ;
BA_DEF_ SG_  "GenSigCycleTimeActive" INT 0 65535;
BA_DEF_ SG_  "GenSigCycleTime" INT 0 65535;
BA_DEF_ SG_  "GenSigSendType" ENUM  "cyclicX","spontanX","cyclicIfActiveX","spontanWithDelay","cyclicAndSpontanX","cyclicAndSpontanWithDelay","spontanWithRepitition","cyclicIfActiveAndSpontanWD","cyclicIfActiveFast","cyclicWithRepeatOnDemand","none";
BA_DEF_ BO_  "GenMsgNrOfRepetitions" INT 0 65535;
BA_DEF_ BO_  "GenMsgDelayTime" INT 0 65535;
BA_DEF_ BO_  "GenMsgStartDelayTime" INT 0 65535;
BA_DEF_ BO_  "GenMsgCycleTimeActive" INT 0 65535;
BA_DEF_ BO_  "GenMsgCycleTime" INT 0 65535;
BA_DEF_ BO_  "GenMsgSendType" ENUM  "cyclicX","spontanX","cyclicIfActiveX","spontanWithDelay","cyclicAndSpontanX","cyclicAndSpontanWithDelay","spontanWithRepitition","cyclicIfActiveAndSpontanWD","cyclicIfActiveFast","cyclicWithRepeatOnDemand","none";
BA_DEF_ BO_  "DiagResponse" ENUM  "nein","ja";
BA_DEF_ BO_  "DiagRequest" ENUM  "nein","ja";
BA_DEF_ BO_  "DiagState" ENUM  "nein","ja";
BA_DEF_ BO_  "App-Botschaft" ENUM  "nein","ja";
BA_DEF_ BO_  "NWM-Botschaft" ENUM  "nein","ja";
BA_DEF_DEF_  "GenSigTimeout_ADCM" 0;
BA_DEF_DEF_  "GenSigTimeout_AFLS" 0;
BA_DEF_DEF_  "GenSigTimeout_CBC" 0;
BA_DEF_DEF_  "GenSigTimeout_DTCM" 0;
BA_DEF_DEF_  "GenSigTimeout_ECM" 0;
BA_DEF_DEF_  "GenSigTimeout_EPS" 0;
BA_DEF_DEF_  "GenSigTimeout_ESC" 0;
BA_DEF_DEF_  "GenSigTimeout_ESM" 0;
BA_DEF_DEF_  "GenSigTimeout_ETM" 0;
BA_DEF_DEF_  "GenSigTimeout_HaLF" 0;
BA_DEF_DEF_  "GenSigTimeout_IC" 0;
BA_DEF_DEF_  "GenSigTimeout_ORC" 0;
BA_DEF_DEF_  "GenSigTimeout_PTS" 0;
BA_DEF_DEF_  "GenSigTimeout_RF_HUB" 0;
BA_DEF_DEF_  "GenSigTimeout_SCCM" 0;
BA_DEF_DEF_  "GenSigTimeout_TPM" 0;
BA_DEF_DEF_  "GenMsgStartValue" "";
BA_DEF_DEF_  "GenSigSNA" "";
BA_DEF_DEF_  "FlexKomIsMotorola" "nein";
BA_DEF_DEF_  "FlexKomSigLaenge" 0;
BA_DEF_DEF_  "FlexKomSigStartPos" 0;
BA_DEF_DEF_  "FlexKomComment" "";
BA_DEF_DEF_  "FlexKomSigName" "";
BA_DEF_DEF_  "FlexKomSID" 0;
BA_DEF_DEF_  "GenSigStartValue" 0;
BA_DEF_DEF_  "FlexKomSigStartValue" "";
BA_DEF_DEF_  "GenSigCycleTimeActive" 0;
BA_DEF_DEF_  "GenSigCycleTime" 0;
BA_DEF_DEF_  "GenSigSendType" "cyclicX";
BA_DEF_DEF_  "GenMsgNrOfRepetitions" 0;
BA_DEF_DEF_  "GenMsgDelayTime" 0;
BA_DEF_DEF_  "GenMsgStartDelayTime" 0;
BA_DEF_DEF_  "GenMsgCycleTimeActive" 0;
BA_DEF_DEF_  "GenMsgCycleTime" 0;
BA_DEF_DEF_  "GenMsgSendType" "cyclicX";
BA_DEF_DEF_  "DiagResponse" "nein";
BA_DEF_DEF_  "DiagRequest" "nein";
BA_DEF_DEF_  "DiagState" "nein";
BA_DEF_DEF_  "App-Botschaft" "nein";
BA_DEF_DEF_  "NWM-Botschaft" "nein";
BA_ "GenMsgCycleTime" BO_ 368 20;
BA_ "GenMsgDelayTime" BO_ 368 20;
BA_ "GenMsgNrOfRepetitions" BO_ 368 2;
BA_ "GenMsgStartValue" BO_ 368 "1CFFFF00000000FFh";
BA_ "GenMsgCycleTime" BO_ 376 100;
BA_ "GenMsgDelayTime" BO_ 376 20;
BA_ "GenMsgNrOfRepetitions" BO_ 376 2;
BA_ "GenMsgStartValue" BO_ 376 "F0FF80h";
BA_ "GenMsgCycleTime" BO_ 384 100;
BA_ "GenMsgDelayTime" BO_ 384 20;
BA_ "GenMsgNrOfRepetitions" BO_ 384 2;
BA_ "GenMsgStartValue" BO_ 384 "00FFFF000001FFFFh";
BA_ "GenMsgSendType" BO_ 388 5;
BA_ "GenMsgCycleTime" BO_ 388 100;
BA_ "GenMsgDelayTime" BO_ 388 20;
BA_ "GenMsgNrOfRepetitions" BO_ 388 2;
BA_ "GenMsgStartValue" BO_ 388 "1C000000h";
BA_ "GenMsgCycleTime" BO_ 416 20;
BA_ "GenMsgDelayTime" BO_ 416 20;
BA_ "GenMsgNrOfRepetitions" BO_ 416 2;
BA_ "GenMsgStartValue" BO_ 416 "07FF001FFF00FFh";
BA_ "GenMsgCycleTime" BO_ 436 20;
BA_ "GenMsgDelayTime" BO_ 436 20;
BA_ "GenMsgNrOfRepetitions" BO_ 436 2;
BA_ "GenMsgStartValue" BO_ 436 "0FFF0000000000FFh";
BA_ "GenMsgSendType" BO_ 448 5;
BA_ "GenMsgCycleTime" BO_ 448 200;
BA_ "GenMsgDelayTime" BO_ 448 20;
BA_ "GenMsgNrOfRepetitions" BO_ 448 2;
BA_ "GenMsgStartValue" BO_ 448 "000000000000h";
BA_ "GenMsgSendType" BO_ 456 5;
BA_ "GenMsgCycleTime" BO_ 456 500;
BA_ "GenMsgDelayTime" BO_ 456 20;
BA_ "GenMsgNrOfRepetitions" BO_ 456 2;
BA_ "GenMsgStartValue" BO_ 456 "00000000h";
BA_ "GenMsgStartDelayTime" BO_ 456 30;
BA_ "GenMsgSendType" BO_ 464 5;
BA_ "GenMsgCycleTime" BO_ 464 1000;
BA_ "GenMsgDelayTime" BO_ 464 20;
BA_ "GenMsgNrOfRepetitions" BO_ 464 2;
BA_ "GenMsgStartValue" BO_ 464 "48E70F0F00070000h";
BA_ "GenMsgSendType" BO_ 466 2;
BA_ "GenMsgCycleTimeActive" BO_ 466 20;
BA_ "GenMsgDelayTime" BO_ 466 20;
BA_ "GenMsgNrOfRepetitions" BO_ 466 2;
BA_ "GenMsgStartValue" BO_ 466 "0000h";
BA_ "GenMsgCycleTime" BO_ 468 60;
BA_ "GenMsgDelayTime" BO_ 468 20;
BA_ "GenMsgNrOfRepetitions" BO_ 468 2;
BA_ "GenMsgStartValue" BO_ 468 "0002FFFF00FF00FFh";
BA_ "GenMsgSendType" BO_ 480 5;
BA_ "GenMsgCycleTime" BO_ 480 1000;
BA_ "GenMsgDelayTime" BO_ 480 20;
BA_ "GenMsgNrOfRepetitions" BO_ 480 2;
BA_ "GenMsgStartValue" BO_ 480 "FF0F000000000000h";
BA_ "GenMsgCycleTime" BO_ 500 20;
BA_ "GenMsgDelayTime" BO_ 500 20;
BA_ "GenMsgNrOfRepetitions" BO_ 500 2;
BA_ "GenMsgStartValue" BO_ 500 "1FFF0CCB000000FFh";
BA_ "GenMsgCycleTime" BO_ 501 60;
BA_ "GenMsgDelayTime" BO_ 501 20;
BA_ "GenMsgNrOfRepetitions" BO_ 501 2;
BA_ "GenMsgStartValue" BO_ 501 "00FFFF00000000FFh";
BA_ "GenMsgCycleTime" BO_ 512 100;
BA_ "GenMsgDelayTime" BO_ 512 20;
BA_ "GenMsgNrOfRepetitions" BO_ 512 2;
BA_ "GenMsgStartValue" BO_ 512 "FFFFFFFFFFFFFFFFh";
BA_ "GenMsgCycleTime" BO_ 514 10;
BA_ "GenMsgDelayTime" BO_ 514 20;
BA_ "GenMsgNrOfRepetitions" BO_ 514 2;
BA_ "GenMsgStartValue" BO_ 514 "FFFFFFFF00000000h";
BA_ "GenMsgSendType" BO_ 516 1;
BA_ "GenMsgDelayTime" BO_ 516 20;
BA_ "GenMsgNrOfRepetitions" BO_ 516 2;
BA_ "GenMsgStartValue" BO_ 516 "00000000000000h";
BA_ "GenMsgSendType" BO_ 517 1;
BA_ "GenMsgDelayTime" BO_ 517 20;
BA_ "GenMsgNrOfRepetitions" BO_ 517 2;
BA_ "GenMsgStartValue" BO_ 517 "00000000000000h";
BA_ "GenMsgCycleTime" BO_ 520 20;
BA_ "GenMsgDelayTime" BO_ 520 20;
BA_ "GenMsgNrOfRepetitions" BO_ 520 2;
BA_ "GenMsgStartValue" BO_ 520 "3FFF0C0000000000h";
BA_ "GenMsgStartDelayTime" BO_ 520 10;
BA_ "GenMsgSendType" BO_ 528 5;
BA_ "GenMsgCycleTime" BO_ 528 1000;
BA_ "GenMsgDelayTime" BO_ 528 20;
BA_ "GenMsgNrOfRepetitions" BO_ 528 2;
BA_ "GenMsgStartValue" BO_ 528 "0F0Fh";
BA_ "GenSigCycleTime" SG_ 368 PaddlesModeSts 20;
BA_ "FlexKomSigStartValue" SG_ 368 PaddlesModeSts "1CFFFF00000000FFh";
BA_ "GenSigTimeout_CBC" SG_ 368 PaddlesModeSts 210;
BA_ "GenSigTimeout_IC" SG_ 368 PaddlesModeSts 210;
BA_ "GenSigTimeout_ESM" SG_ 368 PaddlesModeSts 210;
BA_ "FlexKomSID" SG_ 368 PaddlesModeSts 1366;
BA_ "FlexKomSigStartPos" SG_ 368 PaddlesModeSts 7;
BA_ "FlexKomSigLaenge" SG_ 368 PaddlesModeSts 64;
BA_ "FlexKomSigName" SG_ 368 PaddlesModeSts "TRNS_STAT_PKT";
BA_ "FlexKomComment" SG_ 368 PaddlesModeSts "TRNS_STAT message packet";
BA_ "FlexKomIsMotorola" SG_ 368 PaddlesModeSts 1;
BA_ "GenSigSNA" SG_ 368 PaddlesModeSts "3h";
BA_ "GenSigCycleTime" SG_ 368 PRND_STAT 20;
BA_ "FlexKomSigStartValue" SG_ 368 PRND_STAT "1CFFFF00000000FFh";
BA_ "GenSigStartValue" SG_ 368 PRND_STAT 7;
BA_ "GenSigTimeout_RF_HUB" SG_ 368 PRND_STAT 210;
BA_ "GenSigTimeout_CBC" SG_ 368 PRND_STAT 510;
BA_ "GenSigTimeout_IC" SG_ 368 PRND_STAT 210;
BA_ "GenSigTimeout_PTS" SG_ 368 PRND_STAT 210;
BA_ "GenSigTimeout_TPM" SG_ 368 PRND_STAT 210;
BA_ "GenSigTimeout_ESM" SG_ 368 PRND_STAT 210;
BA_ "GenSigTimeout_ORC" SG_ 368 PRND_STAT 70;
BA_ "FlexKomSID" SG_ 368 PRND_STAT 1366;
BA_ "FlexKomSigStartPos" SG_ 368 PRND_STAT 7;
BA_ "FlexKomSigLaenge" SG_ 368 PRND_STAT 64;
BA_ "FlexKomSigName" SG_ 368 PRND_STAT "TRNS_STAT_PKT";
BA_ "FlexKomComment" SG_ 368 PRND_STAT "TRNS_STAT message packet";
BA_ "FlexKomIsMotorola" SG_ 368 PRND_STAT 1;
BA_ "GenSigSNA" SG_ 368 PRND_STAT "7h";
BA_ "GenSigCycleTime" SG_ 368 APCM_Rq 20;
BA_ "FlexKomSigStartValue" SG_ 368 APCM_Rq "1CFFFF00000000FFh";
BA_ "GenSigTimeout_IC" SG_ 368 APCM_Rq 210;
BA_ "FlexKomSID" SG_ 368 APCM_Rq 1366;
BA_ "FlexKomSigStartPos" SG_ 368 APCM_Rq 7;
BA_ "FlexKomSigLaenge" SG_ 368 APCM_Rq 64;
BA_ "FlexKomSigName" SG_ 368 APCM_Rq "TRNS_STAT_PKT";
BA_ "FlexKomComment" SG_ 368 APCM_Rq "TRNS_STAT message packet";
BA_ "FlexKomIsMotorola" SG_ 368 APCM_Rq 1;
BA_ "GenSigSNA" SG_ 368 APCM_Rq "3h";
BA_ "GenSigCycleTime" SG_ 368 EngStEnblRqTCM 20;
BA_ "FlexKomSigStartValue" SG_ 368 EngStEnblRqTCM "1CFFFF00000000FFh";
BA_ "FlexKomSID" SG_ 368 EngStEnblRqTCM 1366;
BA_ "FlexKomSigStartPos" SG_ 368 EngStEnblRqTCM 7;
BA_ "FlexKomSigLaenge" SG_ 368 EngStEnblRqTCM 64;
BA_ "FlexKomSigName" SG_ 368 EngStEnblRqTCM "TRNS_STAT_PKT";
BA_ "FlexKomComment" SG_ 368 EngStEnblRqTCM "TRNS_STAT message packet";
BA_ "FlexKomIsMotorola" SG_ 368 EngStEnblRqTCM 1;
BA_ "GenSigSNA" SG_ 368 EngStEnblRqTCM "0h";
BA_ "GenSigCycleTime" SG_ 368 SHFT_PROG 20;
BA_ "FlexKomSigStartValue" SG_ 368 SHFT_PROG "1CFFFF00000000FFh";
BA_ "GenSigStartValue" SG_ 368 SHFT_PROG 255;
BA_ "GenSigTimeout_CBC" SG_ 368 SHFT_PROG 210;
BA_ "GenSigTimeout_IC" SG_ 368 SHFT_PROG 210;
BA_ "FlexKomSID" SG_ 368 SHFT_PROG 1366;
BA_ "FlexKomSigStartPos" SG_ 368 SHFT_PROG 7;
BA_ "FlexKomSigLaenge" SG_ 368 SHFT_PROG 64;
BA_ "FlexKomSigName" SG_ 368 SHFT_PROG "TRNS_STAT_PKT";
BA_ "FlexKomComment" SG_ 368 SHFT_PROG "TRNS_STAT message packet";
BA_ "FlexKomIsMotorola" SG_ 368 SHFT_PROG 1;
BA_ "GenSigSNA" SG_ 368 SHFT_PROG "FFh";
BA_ "GenSigCycleTime" SG_ 368 PRNDL_DISP 20;
BA_ "FlexKomSigStartValue" SG_ 368 PRNDL_DISP "1CFFFF00000000FFh";
BA_ "GenSigStartValue" SG_ 368 PRNDL_DISP 255;
BA_ "GenSigTimeout_CBC" SG_ 368 PRNDL_DISP 210;
BA_ "GenSigTimeout_IC" SG_ 368 PRNDL_DISP 210;
BA_ "GenSigTimeout_ESM" SG_ 368 PRNDL_DISP 210;
BA_ "GenSigTimeout_DTCM" SG_ 368 PRNDL_DISP 210;
BA_ "FlexKomSID" SG_ 368 PRNDL_DISP 1366;
BA_ "FlexKomSigStartPos" SG_ 368 PRNDL_DISP 7;
BA_ "FlexKomSigLaenge" SG_ 368 PRNDL_DISP 64;
BA_ "FlexKomSigName" SG_ 368 PRNDL_DISP "TRNS_STAT_PKT";
BA_ "FlexKomComment" SG_ 368 PRNDL_DISP "TRNS_STAT message packet";
BA_ "FlexKomIsMotorola" SG_ 368 PRNDL_DISP 1;
BA_ "GenSigSNA" SG_ 368 PRNDL_DISP "FFh";
BA_ "GenSigCycleTime" SG_ 368 R_SHFT_LOCK 20;
BA_ "FlexKomSigStartValue" SG_ 368 R_SHFT_LOCK "1CFFFF00000000FFh";
BA_ "FlexKomSID" SG_ 368 R_SHFT_LOCK 1366;
BA_ "FlexKomSigStartPos" SG_ 368 R_SHFT_LOCK 7;
BA_ "FlexKomSigLaenge" SG_ 368 R_SHFT_LOCK 64;
BA_ "FlexKomSigName" SG_ 368 R_SHFT_LOCK "TRNS_STAT_PKT";
BA_ "FlexKomComment" SG_ 368 R_SHFT_LOCK "TRNS_STAT message packet";
BA_ "FlexKomIsMotorola" SG_ 368 R_SHFT_LOCK 1;
BA_ "GenSigSNA" SG_ 368 R_SHFT_LOCK "0h";
BA_ "GenSigCycleTime" SG_ 368 TX_D_POSSIBLE 20;
BA_ "FlexKomSigStartValue" SG_ 368 TX_D_POSSIBLE "1CFFFF00000000FFh";
BA_ "FlexKomSID" SG_ 368 TX_D_POSSIBLE 1366;
BA_ "FlexKomSigStartPos" SG_ 368 TX_D_POSSIBLE 7;
BA_ "FlexKomSigLaenge" SG_ 368 TX_D_POSSIBLE 64;
BA_ "FlexKomSigName" SG_ 368 TX_D_POSSIBLE "TRNS_STAT_PKT";
BA_ "FlexKomComment" SG_ 368 TX_D_POSSIBLE "TRNS_STAT message packet";
BA_ "FlexKomIsMotorola" SG_ 368 TX_D_POSSIBLE 1;
BA_ "GenSigSNA" SG_ 368 TX_D_POSSIBLE "0h";
BA_ "GenSigCycleTime" SG_ 368 TX_M_POSSIBLE 20;
BA_ "FlexKomSigStartValue" SG_ 368 TX_M_POSSIBLE "1CFFFF00000000FFh";
BA_ "FlexKomSID" SG_ 368 TX_M_POSSIBLE 1366;
BA_ "FlexKomSigStartPos" SG_ 368 TX_M_POSSIBLE 7;
BA_ "FlexKomSigLaenge" SG_ 368 TX_M_POSSIBLE 64;
BA_ "FlexKomSigName" SG_ 368 TX_M_POSSIBLE "TRNS_STAT_PKT";
BA_ "FlexKomComment" SG_ 368 TX_M_POSSIBLE "TRNS_STAT message packet";
BA_ "FlexKomIsMotorola" SG_ 368 TX_M_POSSIBLE 1;
BA_ "GenSigSNA" SG_ 368 TX_M_POSSIBLE "0h";
BA_ "GenSigCycleTime" SG_ 368 SHFT_LOCK 20;
BA_ "FlexKomSigStartValue" SG_ 368 SHFT_LOCK "1CFFFF00000000FFh";
BA_ "GenSigTimeout_ESM" SG_ 368 SHFT_LOCK 210;
BA_ "FlexKomSID" SG_ 368 SHFT_LOCK 1366;
BA_ "FlexKomSigStartPos" SG_ 368 SHFT_LOCK 7;
BA_ "FlexKomSigLaenge" SG_ 368 SHFT_LOCK 64;
BA_ "FlexKomSigName" SG_ 368 SHFT_LOCK "TRNS_STAT_PKT";
BA_ "FlexKomComment" SG_ 368 SHFT_LOCK "TRNS_STAT message packet";
BA_ "FlexKomIsMotorola" SG_ 368 SHFT_LOCK 1;
BA_ "GenSigSNA" SG_ 368 SHFT_LOCK "0h";
BA_ "GenSigCycleTime" SG_ 368 SHFT_RESET 20;
BA_ "FlexKomSigStartValue" SG_ 368 SHFT_RESET "1CFFFF00000000FFh";
BA_ "FlexKomSID" SG_ 368 SHFT_RESET 1366;
BA_ "FlexKomSigStartPos" SG_ 368 SHFT_RESET 7;
BA_ "FlexKomSigLaenge" SG_ 368 SHFT_RESET 64;
BA_ "FlexKomSigName" SG_ 368 SHFT_RESET "TRNS_STAT_PKT";
BA_ "FlexKomComment" SG_ 368 SHFT_RESET "TRNS_STAT message packet";
BA_ "FlexKomIsMotorola" SG_ 368 SHFT_RESET 1;
BA_ "GenSigSNA" SG_ 368 SHFT_RESET "0h";
BA_ "GenSigCycleTime" SG_ 368 SHFT_HS_TCM_VALID 20;
BA_ "FlexKomSigStartValue" SG_ 368 SHFT_HS_TCM_VALID "1CFFFF00000000FFh";
BA_ "FlexKomSID" SG_ 368 SHFT_HS_TCM_VALID 1366;
BA_ "FlexKomSigStartPos" SG_ 368 SHFT_HS_TCM_VALID 7;
BA_ "FlexKomSigLaenge" SG_ 368 SHFT_HS_TCM_VALID 64;
BA_ "FlexKomSigName" SG_ 368 SHFT_HS_TCM_VALID "TRNS_STAT_PKT";
BA_ "FlexKomComment" SG_ 368 SHFT_HS_TCM_VALID "TRNS_STAT message packet";
BA_ "FlexKomIsMotorola" SG_ 368 SHFT_HS_TCM_VALID 1;
BA_ "GenSigSNA" SG_ 368 SHFT_HS_TCM_VALID "0h";
BA_ "GenSigCycleTime" SG_ 368 SHFT_HS1_TCM 20;
BA_ "FlexKomSigStartValue" SG_ 368 SHFT_HS1_TCM "1CFFFF00000000FFh";
BA_ "FlexKomSID" SG_ 368 SHFT_HS1_TCM 1366;
BA_ "FlexKomSigStartPos" SG_ 368 SHFT_HS1_TCM 7;
BA_ "FlexKomSigLaenge" SG_ 368 SHFT_HS1_TCM 64;
BA_ "FlexKomSigName" SG_ 368 SHFT_HS1_TCM "TRNS_STAT_PKT";
BA_ "FlexKomComment" SG_ 368 SHFT_HS1_TCM "TRNS_STAT message packet";
BA_ "FlexKomIsMotorola" SG_ 368 SHFT_HS1_TCM 1;
BA_ "GenSigSNA" SG_ 368 SHFT_HS1_TCM "0h";
BA_ "GenSigCycleTime" SG_ 368 SHFT_HS2_TCM 20;
BA_ "FlexKomSigStartValue" SG_ 368 SHFT_HS2_TCM "1CFFFF00000000FFh";
BA_ "FlexKomSID" SG_ 368 SHFT_HS2_TCM 1366;
BA_ "FlexKomSigStartPos" SG_ 368 SHFT_HS2_TCM 7;
BA_ "FlexKomSigLaenge" SG_ 368 SHFT_HS2_TCM 64;
BA_ "FlexKomSigName" SG_ 368 SHFT_HS2_TCM "TRNS_STAT_PKT";
BA_ "FlexKomComment" SG_ 368 SHFT_HS2_TCM "TRNS_STAT message packet";
BA_ "FlexKomIsMotorola" SG_ 368 SHFT_HS2_TCM 1;
BA_ "GenSigSNA" SG_ 368 SHFT_HS2_TCM "0h";
BA_ "GenSigCycleTime" SG_ 368 TxDisengaged 20;
BA_ "FlexKomSigStartValue" SG_ 368 TxDisengaged "1CFFFF00000000FFh";
BA_ "FlexKomSID" SG_ 368 TxDisengaged 1366;
BA_ "FlexKomSigStartPos" SG_ 368 TxDisengaged 7;
BA_ "FlexKomSigLaenge" SG_ 368 TxDisengaged 64;
BA_ "FlexKomSigName" SG_ 368 TxDisengaged "TRNS_STAT_PKT";
BA_ "FlexKomComment" SG_ 368 TxDisengaged "TRNS_STAT message packet";
BA_ "FlexKomIsMotorola" SG_ 368 TxDisengaged 1;
BA_ "GenSigSNA" SG_ 368 TxDisengaged "0h";
BA_ "GenSigCycleTime" SG_ 368 PRNDL_Blink 20;
BA_ "FlexKomSigStartValue" SG_ 368 PRNDL_Blink "1CFFFF00000000FFh";
BA_ "GenSigTimeout_IC" SG_ 368 PRNDL_Blink 210;
BA_ "GenSigTimeout_ESM" SG_ 368 PRNDL_Blink 210;
BA_ "FlexKomSID" SG_ 368 PRNDL_Blink 1366;
BA_ "FlexKomSigStartPos" SG_ 368 PRNDL_Blink 7;
BA_ "FlexKomSigLaenge" SG_ 368 PRNDL_Blink 64;
BA_ "FlexKomSigName" SG_ 368 PRNDL_Blink "TRNS_STAT_PKT";
BA_ "FlexKomComment" SG_ 368 PRNDL_Blink "TRNS_STAT message packet";
BA_ "FlexKomIsMotorola" SG_ 368 PRNDL_Blink 1;
BA_ "GenSigSNA" SG_ 368 PRNDL_Blink "0h";
BA_ "GenSigCycleTime" SG_ 368 MC_TRNS_STAT 20;
BA_ "FlexKomSigStartValue" SG_ 368 MC_TRNS_STAT "1CFFFF00000000FFh";
BA_ "GenSigTimeout_ESM" SG_ 368 MC_TRNS_STAT 210;
BA_ "GenSigTimeout_ORC" SG_ 368 MC_TRNS_STAT 70;
BA_ "FlexKomSID" SG_ 368 MC_TRNS_STAT 1366;
BA_ "FlexKomSigStartPos" SG_ 368 MC_TRNS_STAT 7;
BA_ "FlexKomSigLaenge" SG_ 368 MC_TRNS_STAT 64;
BA_ "FlexKomSigName" SG_ 368 MC_TRNS_STAT "TRNS_STAT_PKT";
BA_ "FlexKomComment" SG_ 368 MC_TRNS_STAT "TRNS_STAT message packet";
BA_ "FlexKomIsMotorola" SG_ 368 MC_TRNS_STAT 1;
BA_ "GenSigSNA" SG_ 368 MC_TRNS_STAT "0h";
BA_ "GenSigCycleTime" SG_ 368 CRC_TRNS_STAT 20;
BA_ "FlexKomSigStartValue" SG_ 368 CRC_TRNS_STAT "1CFFFF00000000FFh";
BA_ "GenSigStartValue" SG_ 368 CRC_TRNS_STAT 255;
BA_ "GenSigTimeout_ESM" SG_ 368 CRC_TRNS_STAT 210;
BA_ "GenSigTimeout_ORC" SG_ 368 CRC_TRNS_STAT 70;
BA_ "FlexKomSID" SG_ 368 CRC_TRNS_STAT 1366;
BA_ "FlexKomSigStartPos" SG_ 368 CRC_TRNS_STAT 7;
BA_ "FlexKomSigLaenge" SG_ 368 CRC_TRNS_STAT 64;
BA_ "FlexKomSigName" SG_ 368 CRC_TRNS_STAT "TRNS_STAT_PKT";
BA_ "FlexKomComment" SG_ 368 CRC_TRNS_STAT "TRNS_STAT message packet";
BA_ "FlexKomIsMotorola" SG_ 368 CRC_TRNS_STAT 1;
BA_ "GenSigSNA" SG_ 368 CRC_TRNS_STAT "FFh";
BA_ "GenSigCycleTime" SG_ 376 MIL_OnRq_TCM 100;
BA_ "FlexKomSigStartValue" SG_ 376 MIL_OnRq_TCM "00h";
BA_ "GenSigTimeout_IC" SG_ 376 MIL_OnRq_TCM 1050;
BA_ "FlexKomSID" SG_ 376 MIL_OnRq_TCM 1141;
BA_ "FlexKomSigLaenge" SG_ 376 MIL_OnRq_TCM 1;
BA_ "FlexKomSigName" SG_ 376 MIL_OnRq_TCM "MIL_OnRq_TCM";
BA_ "FlexKomComment" SG_ 376 MIL_OnRq_TCM "MIL on request from the transmission";
BA_ "FlexKomIsMotorola" SG_ 376 MIL_OnRq_TCM 1;
BA_ "GenSigSNA" SG_ 376 MIL_OnRq_TCM "0h";
BA_ "GenSigCycleTime" SG_ 376 G_G 100;
BA_ "FlexKomSigStartValue" SG_ 376 G_G "00h";
BA_ "FlexKomSID" SG_ 376 G_G 1142;
BA_ "FlexKomSigStartPos" SG_ 376 G_G 1;
BA_ "FlexKomSigLaenge" SG_ 376 G_G 1;
BA_ "FlexKomSigName" SG_ 376 G_G "G_G";
BA_ "FlexKomComment" SG_ 376 G_G "Transfer case range; hi range = [0], low range = [";
BA_ "FlexKomIsMotorola" SG_ 376 G_G 1;
BA_ "GenSigSNA" SG_ 376 G_G "0h";
BA_ "GenSigCycleTime" SG_ 376 GS_NOTL 100;
BA_ "FlexKomSigStartValue" SG_ 376 GS_NOTL "00h";
BA_ "GenSigTimeout_ORC" SG_ 376 GS_NOTL 350;
BA_ "FlexKomSID" SG_ 376 GS_NOTL 1143;
BA_ "FlexKomSigStartPos" SG_ 376 GS_NOTL 2;
BA_ "FlexKomSigLaenge" SG_ 376 GS_NOTL 1;
BA_ "FlexKomSigName" SG_ 376 GS_NOTL "GS_NOTL";
BA_ "FlexKomComment" SG_ 376 GS_NOTL "TRANS in limp home mode";
BA_ "FlexKomIsMotorola" SG_ 376 GS_NOTL 1;
BA_ "GenSigSNA" SG_ 376 GS_NOTL "0h";
BA_ "GenSigCycleTime" SG_ 376 TxTemp_Excess 100;
BA_ "FlexKomSigStartValue" SG_ 376 TxTemp_Excess "00h";
BA_ "GenSigTimeout_IC" SG_ 376 TxTemp_Excess 1050;
BA_ "GenSigTimeout_ETM" SG_ 376 TxTemp_Excess 1050;
BA_ "FlexKomSID" SG_ 376 TxTemp_Excess 1144;
BA_ "FlexKomSigStartPos" SG_ 376 TxTemp_Excess 3;
BA_ "FlexKomSigLaenge" SG_ 376 TxTemp_Excess 1;
BA_ "FlexKomSigName" SG_ 376 TxTemp_Excess "TxTemp_Excess";
BA_ "FlexKomComment" SG_ 376 TxTemp_Excess "Excessive transmission temperature";
BA_ "FlexKomIsMotorola" SG_ 376 TxTemp_Excess 1;
BA_ "GenSigSNA" SG_ 376 TxTemp_Excess "0h";
BA_ "GenSigCycleTime" SG_ 376 FAN_RQ 100;
BA_ "FlexKomSigStartValue" SG_ 376 FAN_RQ "0Fh";
BA_ "GenSigStartValue" SG_ 376 FAN_RQ 15;
BA_ "FlexKomSID" SG_ 376 FAN_RQ 1145;
BA_ "FlexKomSigStartPos" SG_ 376 FAN_RQ 7;
BA_ "FlexKomSigLaenge" SG_ 376 FAN_RQ 4;
BA_ "FlexKomSigName" SG_ 376 FAN_RQ "FAN_RQ";
BA_ "FlexKomComment" SG_ 376 FAN_RQ "Cooling fan request";
BA_ "FlexKomIsMotorola" SG_ 376 FAN_RQ 1;
BA_ "GenSigSNA" SG_ 376 FAN_RQ "Fh";
BA_ "GenSigCycleTime" SG_ 376 TX_TEMP 100;
BA_ "FlexKomSigStartValue" SG_ 376 TX_TEMP "FFh";
BA_ "GenSigStartValue" SG_ 376 TX_TEMP 255;
BA_ "GenSigTimeout_CBC" SG_ 376 TX_TEMP 1050;
BA_ "GenSigTimeout_IC" SG_ 376 TX_TEMP 1050;
BA_ "GenSigTimeout_ETM" SG_ 376 TX_TEMP 1050;
BA_ "FlexKomSID" SG_ 376 TX_TEMP 1146;
BA_ "FlexKomSigStartPos" SG_ 376 TX_TEMP 15;
BA_ "FlexKomSigLaenge" SG_ 376 TX_TEMP 8;
BA_ "FlexKomSigName" SG_ 376 TX_TEMP "TX_TEMP";
BA_ "FlexKomComment" SG_ 376 TX_TEMP "Transmission fluid temperature";
BA_ "FlexKomIsMotorola" SG_ 376 TX_TEMP 1;
BA_ "GenSigSNA" SG_ 376 TX_TEMP "FFh";
BA_ "GenSigCycleTime" SG_ 376 TX_WARN 100;
BA_ "FlexKomSigStartValue" SG_ 376 TX_WARN "00h";
BA_ "GenSigTimeout_IC" SG_ 376 TX_WARN 1050;
BA_ "FlexKomSID" SG_ 376 TX_WARN 1365;
BA_ "FlexKomSigStartPos" SG_ 376 TX_WARN 19;
BA_ "FlexKomSigLaenge" SG_ 376 TX_WARN 4;
BA_ "FlexKomSigName" SG_ 376 TX_WARN "TX_WARN";
BA_ "FlexKomComment" SG_ 376 TX_WARN "Transmission warning";
BA_ "FlexKomIsMotorola" SG_ 376 TX_WARN 1;
BA_ "GenSigSNA" SG_ 376 TX_WARN "Fh";
BA_ "GenSigCycleTime" SG_ 376 TX_FAULT 100;
BA_ "FlexKomSigStartValue" SG_ 376 TX_FAULT "00h";
BA_ "GenSigTimeout_ESM" SG_ 376 TX_FAULT 1050;
BA_ "FlexKomSID" SG_ 376 TX_FAULT 1364;
BA_ "FlexKomSigStartPos" SG_ 376 TX_FAULT 21;
BA_ "FlexKomSigLaenge" SG_ 376 TX_FAULT 2;
BA_ "FlexKomSigName" SG_ 376 TX_FAULT "TX_FAULT";
BA_ "FlexKomComment" SG_ 376 TX_FAULT "Transmission fault";
BA_ "FlexKomIsMotorola" SG_ 376 TX_FAULT 1;
BA_ "GenSigSNA" SG_ 376 TX_FAULT "3h";
BA_ "GenSigCycleTime" SG_ 376 TransReadyForESS 100;
BA_ "FlexKomSigStartValue" SG_ 376 TransReadyForESS "00h";
BA_ "FlexKomSID" SG_ 376 TransReadyForESS 1665;
BA_ "FlexKomSigStartPos" SG_ 376 TransReadyForESS 22;
BA_ "FlexKomSigLaenge" SG_ 376 TransReadyForESS 1;
BA_ "FlexKomSigName" SG_ 376 TransReadyForESS "TransReadyForESS";
BA_ "FlexKomComment" SG_ 376 TransReadyForESS "Trans ready for auto stop (0= not ready)";
BA_ "FlexKomIsMotorola" SG_ 376 TransReadyForESS 1;
BA_ "GenSigSNA" SG_ 376 TransReadyForESS "0h";
BA_ "GenSigCycleTime" SG_ 376 TRNS_StpSt_FLT 100;
BA_ "FlexKomSigStartValue" SG_ 376 TRNS_StpSt_FLT "01h";
BA_ "GenSigStartValue" SG_ 376 TRNS_StpSt_FLT 1;
BA_ "FlexKomSID" SG_ 376 TRNS_StpSt_FLT 1399;
BA_ "FlexKomSigStartPos" SG_ 376 TRNS_StpSt_FLT 23;
BA_ "FlexKomSigLaenge" SG_ 376 TRNS_StpSt_FLT 1;
BA_ "FlexKomSigName" SG_ 376 TRNS_StpSt_FLT "TRNS_StpSt_FLT";
BA_ "FlexKomComment" SG_ 376 TRNS_StpSt_FLT "Trans stop start fault (1=fault)";
BA_ "FlexKomIsMotorola" SG_ 376 TRNS_StpSt_FLT 1;
BA_ "GenSigSNA" SG_ 376 TRNS_StpSt_FLT "1h";
BA_ "GenSigCycleTime" SG_ 384 IntkAirTemp 100;
BA_ "FlexKomSigStartValue" SG_ 384 IntkAirTemp "00h";
BA_ "GenSigTimeout_ETM" SG_ 384 IntkAirTemp 1050;
BA_ "FlexKomSID" SG_ 384 IntkAirTemp 441;
BA_ "FlexKomSigStartPos" SG_ 384 IntkAirTemp 7;
BA_ "FlexKomSigLaenge" SG_ 384 IntkAirTemp 8;
BA_ "FlexKomSigName" SG_ 384 IntkAirTemp "IntkAirTemp";
BA_ "FlexKomComment" SG_ 384 IntkAirTemp "Engine Intake Air Temperature";
BA_ "FlexKomIsMotorola" SG_ 384 IntkAirTemp 1;
BA_ "GenSigSNA" SG_ 384 IntkAirTemp "FFh";
BA_ "GenSigCycleTime" SG_ 384 EngCoolTemp 100;
BA_ "FlexKomSigStartValue" SG_ 384 EngCoolTemp "FFh";
BA_ "GenSigStartValue" SG_ 384 EngCoolTemp 255;
BA_ "GenSigTimeout_CBC" SG_ 384 EngCoolTemp 1050;
BA_ "GenSigTimeout_IC" SG_ 384 EngCoolTemp 1050;
BA_ "FlexKomSID" SG_ 384 EngCoolTemp 711;
BA_ "FlexKomSigStartPos" SG_ 384 EngCoolTemp 15;
BA_ "FlexKomSigLaenge" SG_ 384 EngCoolTemp 8;
BA_ "FlexKomSigName" SG_ 384 EngCoolTemp "EngCoolTemp";
BA_ "FlexKomComment" SG_ 384 EngCoolTemp "Engine coolant temperature";
BA_ "FlexKomIsMotorola" SG_ 384 EngCoolTemp 1;
BA_ "GenSigSNA" SG_ 384 EngCoolTemp "FFh";
BA_ "GenSigCycleTime" SG_ 384 AirPress_Outsd 100;
BA_ "FlexKomSigStartValue" SG_ 384 AirPress_Outsd "FFh";
BA_ "GenSigStartValue" SG_ 384 AirPress_Outsd 255;
BA_ "GenSigTimeout_RF_HUB" SG_ 384 AirPress_Outsd 1050;
BA_ "GenSigTimeout_IC" SG_ 384 AirPress_Outsd 1050;
BA_ "GenSigTimeout_TPM" SG_ 384 AirPress_Outsd 1050;
BA_ "GenSigTimeout_ETM" SG_ 384 AirPress_Outsd 1050;
BA_ "FlexKomSID" SG_ 384 AirPress_Outsd 1084;
BA_ "FlexKomSigStartPos" SG_ 384 AirPress_Outsd 23;
BA_ "FlexKomSigLaenge" SG_ 384 AirPress_Outsd 8;
BA_ "FlexKomSigName" SG_ 384 AirPress_Outsd "AirPress_Outsd";
BA_ "FlexKomComment" SG_ 384 AirPress_Outsd "Ambient air pressure (barometric pressure)";
BA_ "FlexKomIsMotorola" SG_ 384 AirPress_Outsd 1;
BA_ "GenSigSNA" SG_ 384 AirPress_Outsd "FFh";
BA_ "GenSigCycleTime" SG_ 384 TgtVolt 100;
BA_ "FlexKomSigStartValue" SG_ 384 TgtVolt "0000h";
BA_ "FlexKomSID" SG_ 384 TgtVolt 437;
BA_ "FlexKomSigStartPos" SG_ 384 TgtVolt 31;
BA_ "FlexKomSigLaenge" SG_ 384 TgtVolt 16;
BA_ "FlexKomSigName" SG_ 384 TgtVolt "EngVoltPkt";
BA_ "FlexKomComment" SG_ 384 TgtVolt "Engine voltage packet";
BA_ "FlexKomIsMotorola" SG_ 384 TgtVolt 1;
BA_ "GenSigSNA" SG_ 384 TgtVolt "FFh";
BA_ "GenSigCycleTime" SG_ 384 SysVolt 100;
BA_ "FlexKomSigStartValue" SG_ 384 SysVolt "0000h";
BA_ "FlexKomSID" SG_ 384 SysVolt 437;
BA_ "FlexKomSigStartPos" SG_ 384 SysVolt 31;
BA_ "FlexKomSigLaenge" SG_ 384 SysVolt 16;
BA_ "FlexKomSigName" SG_ 384 SysVolt "EngVoltPkt";
BA_ "FlexKomComment" SG_ 384 SysVolt "Engine voltage packet";
BA_ "FlexKomIsMotorola" SG_ 384 SysVolt 1;
BA_ "GenSigSNA" SG_ 384 SysVolt "FFh";
BA_ "GenSigCycleTime" SG_ 384 R134a_Press_Stat 100;
BA_ "FlexKomSigStartValue" SG_ 384 R134a_Press_Stat "01FFh";
BA_ "GenSigStartValue" SG_ 384 R134a_Press_Stat 511;
BA_ "GenSigTimeout_CBC" SG_ 384 R134a_Press_Stat 1050;
BA_ "FlexKomSID" SG_ 384 R134a_Press_Stat 787;
BA_ "FlexKomSigStartPos" SG_ 384 R134a_Press_Stat 47;
BA_ "FlexKomSigLaenge" SG_ 384 R134a_Press_Stat 16;
BA_ "FlexKomSigName" SG_ 384 R134a_Press_Stat "R134a_Press_Stat";
BA_ "FlexKomComment" SG_ 384 R134a_Press_Stat "Refrigerant pressure (R134a or R1234YF)";
BA_ "FlexKomIsMotorola" SG_ 384 R134a_Press_Stat 1;
BA_ "GenSigSNA" SG_ 384 R134a_Press_Stat "1FFh";
BA_ "GenSigCycleTime" SG_ 384 CHRG_FAIL 100;
BA_ "FlexKomSigStartValue" SG_ 384 CHRG_FAIL "00h";
BA_ "GenSigTimeout_IC" SG_ 384 CHRG_FAIL 1050;
BA_ "GenSigTimeout_ORC" SG_ 384 CHRG_FAIL 350;
BA_ "FlexKomSID" SG_ 384 CHRG_FAIL 1085;
BA_ "FlexKomSigStartPos" SG_ 384 CHRG_FAIL 41;
BA_ "FlexKomSigLaenge" SG_ 384 CHRG_FAIL 1;
BA_ "FlexKomSigName" SG_ 384 CHRG_FAIL "CHRG_FAIL";
BA_ "FlexKomComment" SG_ 384 CHRG_FAIL "Charging system Failure (battery indicator request";
BA_ "FlexKomIsMotorola" SG_ 384 CHRG_FAIL 1;
BA_ "GenSigSNA" SG_ 384 CHRG_FAIL "1h";
BA_ "GenSigCycleTime" SG_ 384 AM_ECM_Prsnt 100;
BA_ "FlexKomSigStartValue" SG_ 384 AM_ECM_Prsnt "00h";
BA_ "GenSigTimeout_CBC" SG_ 384 AM_ECM_Prsnt 1050;
BA_ "FlexKomSID" SG_ 384 AM_ECM_Prsnt 1941;
BA_ "FlexKomSigStartPos" SG_ 384 AM_ECM_Prsnt 46;
BA_ "FlexKomSigLaenge" SG_ 384 AM_ECM_Prsnt 2;
BA_ "FlexKomSigName" SG_ 384 AM_ECM_Prsnt "AM_ECM_Prsnt";
BA_ "FlexKomComment" SG_ 384 AM_ECM_Prsnt "Aftermarket ECM present";
BA_ "FlexKomIsMotorola" SG_ 384 AM_ECM_Prsnt 1;
BA_ "GenSigSNA" SG_ 384 AM_ECM_Prsnt "3h";
BA_ "GenSigCycleTime" SG_ 384 AC_CLTCH_EGD 100;
BA_ "FlexKomSigStartValue" SG_ 384 AC_CLTCH_EGD "00h";
BA_ "FlexKomSID" SG_ 384 AC_CLTCH_EGD 1086;
BA_ "FlexKomSigStartPos" SG_ 384 AC_CLTCH_EGD 47;
BA_ "FlexKomSigLaenge" SG_ 384 AC_CLTCH_EGD 1;
BA_ "FlexKomSigName" SG_ 384 AC_CLTCH_EGD "AC_CLTCH_EGD";
BA_ "FlexKomComment" SG_ 384 AC_CLTCH_EGD "AC clutch engauged";
BA_ "FlexKomIsMotorola" SG_ 384 AC_CLTCH_EGD 1;
BA_ "GenSigSNA" SG_ 384 AC_CLTCH_EGD "0h";
BA_ "GenSigCycleTime" SG_ 384 AC_OUTPUT_DC_FINAL 100;
BA_ "FlexKomSigStartValue" SG_ 384 AC_OUTPUT_DC_FINAL "FFh";
BA_ "GenSigStartValue" SG_ 384 AC_OUTPUT_DC_FINAL 255;
BA_ "GenSigTimeout_CBC" SG_ 384 AC_OUTPUT_DC_FINAL 1050;
BA_ "FlexKomSID" SG_ 384 AC_OUTPUT_DC_FINAL 1087;
BA_ "FlexKomSigStartPos" SG_ 384 AC_OUTPUT_DC_FINAL 63;
BA_ "FlexKomSigLaenge" SG_ 384 AC_OUTPUT_DC_FINAL 8;
BA_ "FlexKomSigName" SG_ 384 AC_OUTPUT_DC_FINAL "AC_OUTPUT_DC_FINAL";
BA_ "FlexKomComment" SG_ 384 AC_OUTPUT_DC_FINAL "Variable A/C Compressor Duty Cycle";
BA_ "FlexKomIsMotorola" SG_ 384 AC_OUTPUT_DC_FINAL 1;
BA_ "GenSigSNA" SG_ 384 AC_OUTPUT_DC_FINAL "FFh";
BA_ "GenSigSendType" SG_ 388 CustKeyInIgn 5;
BA_ "GenSigCycleTime" SG_ 388 CustKeyInIgn 100;
BA_ "FlexKomSigStartValue" SG_ 388 CustKeyInIgn "1C000000h";
BA_ "FlexKomSID" SG_ 388 CustKeyInIgn 1034;
BA_ "FlexKomSigStartPos" SG_ 388 CustKeyInIgn 7;
BA_ "FlexKomSigLaenge" SG_ 388 CustKeyInIgn 32;
BA_ "FlexKomSigName" SG_ 388 CustKeyInIgn "CustIgnPkt";
BA_ "FlexKomComment" SG_ 388 CustKeyInIgn "Customer ignition packet";
BA_ "FlexKomIsMotorola" SG_ 388 CustKeyInIgn 1;
BA_ "GenSigSNA" SG_ 388 CustKeyInIgn "3h";
BA_ "GenSigSendType" SG_ 388 IgnPos 5;
BA_ "GenSigCycleTime" SG_ 388 IgnPos 100;
BA_ "FlexKomSigStartValue" SG_ 388 IgnPos "1C000000h";
BA_ "GenSigStartValue" SG_ 388 IgnPos 7;
BA_ "GenSigTimeout_CBC" SG_ 388 IgnPos 1050;
BA_ "FlexKomSID" SG_ 388 IgnPos 1034;
BA_ "FlexKomSigStartPos" SG_ 388 IgnPos 7;
BA_ "FlexKomSigLaenge" SG_ 388 IgnPos 32;
BA_ "FlexKomSigName" SG_ 388 IgnPos "CustIgnPkt";
BA_ "FlexKomComment" SG_ 388 IgnPos "Customer ignition packet";
BA_ "FlexKomIsMotorola" SG_ 388 IgnPos 1;
BA_ "GenSigSNA" SG_ 388 IgnPos "7h";
BA_ "GenSigSendType" SG_ 388 ValImmKey 5;
BA_ "GenSigCycleTime" SG_ 388 ValImmKey 100;
BA_ "FlexKomSigStartValue" SG_ 388 ValImmKey "1C000000h";
BA_ "FlexKomSID" SG_ 388 ValImmKey 1034;
BA_ "FlexKomSigStartPos" SG_ 388 ValImmKey 7;
BA_ "FlexKomSigLaenge" SG_ 388 ValImmKey 32;
BA_ "FlexKomSigName" SG_ 388 ValImmKey "CustIgnPkt";
BA_ "FlexKomComment" SG_ 388 ValImmKey "Customer ignition packet";
BA_ "FlexKomIsMotorola" SG_ 388 ValImmKey 1;
BA_ "GenSigSNA" SG_ 388 ValImmKey "3h";
BA_ "GenSigSendType" SG_ 388 AuthCode 5;
BA_ "GenSigCycleTime" SG_ 388 AuthCode 100;
BA_ "FlexKomSigStartValue" SG_ 388 AuthCode "1C000000h";
BA_ "FlexKomSID" SG_ 388 AuthCode 1034;
BA_ "FlexKomSigStartPos" SG_ 388 AuthCode 7;
BA_ "FlexKomSigLaenge" SG_ 388 AuthCode 32;
BA_ "FlexKomSigName" SG_ 388 AuthCode "CustIgnPkt";
BA_ "FlexKomComment" SG_ 388 AuthCode "Customer ignition packet";
BA_ "FlexKomIsMotorola" SG_ 388 AuthCode 1;
BA_ "GenSigSNA" SG_ 388 AuthCode "FFFFh";
BA_ "GenSigSendType" SG_ 388 RedKey 5;
BA_ "GenSigCycleTime" SG_ 388 RedKey 100;
BA_ "FlexKomSigStartValue" SG_ 388 RedKey "1C000000h";
BA_ "FlexKomSID" SG_ 388 RedKey 1034;
BA_ "FlexKomSigStartPos" SG_ 388 RedKey 7;
BA_ "FlexKomSigLaenge" SG_ 388 RedKey 32;
BA_ "FlexKomSigName" SG_ 388 RedKey "CustIgnPkt";
BA_ "FlexKomComment" SG_ 388 RedKey "Customer ignition packet";
BA_ "FlexKomIsMotorola" SG_ 388 RedKey 1;
BA_ "GenSigSNA" SG_ 388 RedKey "0h";
BA_ "GenSigSendType" SG_ 388 TeenKey 5;
BA_ "GenSigCycleTime" SG_ 388 TeenKey 100;
BA_ "FlexKomSigStartValue" SG_ 388 TeenKey "1C000000h";
BA_ "FlexKomSID" SG_ 388 TeenKey 1034;
BA_ "FlexKomSigStartPos" SG_ 388 TeenKey 7;
BA_ "FlexKomSigLaenge" SG_ 388 TeenKey 32;
BA_ "FlexKomSigName" SG_ 388 TeenKey "CustIgnPkt";
BA_ "FlexKomComment" SG_ 388 TeenKey "Customer ignition packet";
BA_ "FlexKomIsMotorola" SG_ 388 TeenKey 1;
BA_ "GenSigSNA" SG_ 388 TeenKey "0h";
BA_ "GenSigCycleTime" SG_ 416 Trans_Trq_Ratio 20;
BA_ "FlexKomSigStartValue" SG_ 416 Trans_Trq_Ratio "07FF001FFF00FFh";
BA_ "GenSigStartValue" SG_ 416 Trans_Trq_Ratio 2047;
BA_ "FlexKomSID" SG_ 416 Trans_Trq_Ratio 788;
BA_ "FlexKomSigStartPos" SG_ 416 Trans_Trq_Ratio 7;
BA_ "FlexKomSigLaenge" SG_ 416 Trans_Trq_Ratio 56;
BA_ "FlexKomSigName" SG_ 416 Trans_Trq_Ratio "ENG_TRQ_PKT";
BA_ "FlexKomComment" SG_ 416 Trans_Trq_Ratio "Engine torque packet for all transmissions";
BA_ "FlexKomIsMotorola" SG_ 416 Trans_Trq_Ratio 1;
BA_ "GenSigSNA" SG_ 416 Trans_Trq_Ratio "7FFh";
BA_ "GenSigCycleTime" SG_ 416 TxIdleRq 20;
BA_ "FlexKomSigStartValue" SG_ 416 TxIdleRq "07FF001FFF00FFh";
BA_ "FlexKomSID" SG_ 416 TxIdleRq 788;
BA_ "FlexKomSigStartPos" SG_ 416 TxIdleRq 7;
BA_ "FlexKomSigLaenge" SG_ 416 TxIdleRq 56;
BA_ "FlexKomSigName" SG_ 416 TxIdleRq "ENG_TRQ_PKT";
BA_ "FlexKomComment" SG_ 416 TxIdleRq "Engine torque packet for all transmissions";
BA_ "FlexKomIsMotorola" SG_ 416 TxIdleRq 1;
BA_ "GenSigSNA" SG_ 416 TxIdleRq "FFh";
BA_ "GenSigCycleTime" SG_ 416 EngTrq_Rq_TCM 20;
BA_ "FlexKomSigStartValue" SG_ 416 EngTrq_Rq_TCM "07FF001FFF00FFh";
BA_ "GenSigStartValue" SG_ 416 EngTrq_Rq_TCM 8191;
BA_ "FlexKomSID" SG_ 416 EngTrq_Rq_TCM 788;
BA_ "FlexKomSigStartPos" SG_ 416 EngTrq_Rq_TCM 7;
BA_ "FlexKomSigLaenge" SG_ 416 EngTrq_Rq_TCM 56;
BA_ "FlexKomSigName" SG_ 416 EngTrq_Rq_TCM "ENG_TRQ_PKT";
BA_ "FlexKomComment" SG_ 416 EngTrq_Rq_TCM "Engine torque packet for all transmissions";
BA_ "FlexKomIsMotorola" SG_ 416 EngTrq_Rq_TCM 1;
BA_ "GenSigSNA" SG_ 416 EngTrq_Rq_TCM "1FFFh";
BA_ "GenSigCycleTime" SG_ 416 EngTrqMax_Rq_TCM 20;
BA_ "FlexKomSigStartValue" SG_ 416 EngTrqMax_Rq_TCM "07FF001FFF00FFh";
BA_ "FlexKomSID" SG_ 416 EngTrqMax_Rq_TCM 788;
BA_ "FlexKomSigStartPos" SG_ 416 EngTrqMax_Rq_TCM 7;
BA_ "FlexKomSigLaenge" SG_ 416 EngTrqMax_Rq_TCM 56;
BA_ "FlexKomSigName" SG_ 416 EngTrqMax_Rq_TCM "ENG_TRQ_PKT";
BA_ "FlexKomComment" SG_ 416 EngTrqMax_Rq_TCM "Engine torque packet for all transmissions";
BA_ "FlexKomIsMotorola" SG_ 416 EngTrqMax_Rq_TCM 1;
BA_ "GenSigSNA" SG_ 416 EngTrqMax_Rq_TCM "0h";
BA_ "GenSigCycleTime" SG_ 416 EngTrqMin_Rq_TCM 20;
BA_ "FlexKomSigStartValue" SG_ 416 EngTrqMin_Rq_TCM "07FF001FFF00FFh";
BA_ "FlexKomSID" SG_ 416 EngTrqMin_Rq_TCM 788;
BA_ "FlexKomSigStartPos" SG_ 416 EngTrqMin_Rq_TCM 7;
BA_ "FlexKomSigLaenge" SG_ 416 EngTrqMin_Rq_TCM 56;
BA_ "FlexKomSigName" SG_ 416 EngTrqMin_Rq_TCM "ENG_TRQ_PKT";
BA_ "FlexKomComment" SG_ 416 EngTrqMin_Rq_TCM "Engine torque packet for all transmissions";
BA_ "FlexKomIsMotorola" SG_ 416 EngTrqMin_Rq_TCM 1;
BA_ "GenSigSNA" SG_ 416 EngTrqMin_Rq_TCM "0h";
BA_ "GenSigCycleTime" SG_ 416 DYN0_AMR_EGS 20;
BA_ "FlexKomSigStartValue" SG_ 416 DYN0_AMR_EGS "07FF001FFF00FFh";
BA_ "FlexKomSID" SG_ 416 DYN0_AMR_EGS 788;
BA_ "FlexKomSigStartPos" SG_ 416 DYN0_AMR_EGS 7;
BA_ "FlexKomSigLaenge" SG_ 416 DYN0_AMR_EGS 56;
BA_ "FlexKomSigName" SG_ 416 DYN0_AMR_EGS "ENG_TRQ_PKT";
BA_ "FlexKomComment" SG_ 416 DYN0_AMR_EGS "Engine torque packet for all transmissions";
BA_ "FlexKomIsMotorola" SG_ 416 DYN0_AMR_EGS 1;
BA_ "GenSigSNA" SG_ 416 DYN0_AMR_EGS "0h";
BA_ "GenSigCycleTime" SG_ 416 DYN1_EGS 20;
BA_ "FlexKomSigStartValue" SG_ 416 DYN1_EGS "07FF001FFF00FFh";
BA_ "FlexKomSID" SG_ 416 DYN1_EGS 788;
BA_ "FlexKomSigStartPos" SG_ 416 DYN1_EGS 7;
BA_ "FlexKomSigLaenge" SG_ 416 DYN1_EGS 56;
BA_ "FlexKomSigName" SG_ 416 DYN1_EGS "ENG_TRQ_PKT";
BA_ "FlexKomComment" SG_ 416 DYN1_EGS "Engine torque packet for all transmissions";
BA_ "FlexKomIsMotorola" SG_ 416 DYN1_EGS 1;
BA_ "GenSigSNA" SG_ 416 DYN1_EGS "0h";
BA_ "GenSigCycleTime" SG_ 416 MC_TCM_ENG_TRQ 20;
BA_ "FlexKomSigStartValue" SG_ 416 MC_TCM_ENG_TRQ "07FF001FFF00FFh";
BA_ "FlexKomSID" SG_ 416 MC_TCM_ENG_TRQ 788;
BA_ "FlexKomSigStartPos" SG_ 416 MC_TCM_ENG_TRQ 7;
BA_ "FlexKomSigLaenge" SG_ 416 MC_TCM_ENG_TRQ 56;
BA_ "FlexKomSigName" SG_ 416 MC_TCM_ENG_TRQ "ENG_TRQ_PKT";
BA_ "FlexKomComment" SG_ 416 MC_TCM_ENG_TRQ "Engine torque packet for all transmissions";
BA_ "FlexKomIsMotorola" SG_ 416 MC_TCM_ENG_TRQ 1;
BA_ "GenSigSNA" SG_ 416 MC_TCM_ENG_TRQ "0h";
BA_ "GenSigCycleTime" SG_ 416 CRC_TCM_ENG_TRQ 20;
BA_ "FlexKomSigStartValue" SG_ 416 CRC_TCM_ENG_TRQ "07FF001FFF00FFh";
BA_ "GenSigStartValue" SG_ 416 CRC_TCM_ENG_TRQ 255;
BA_ "FlexKomSID" SG_ 416 CRC_TCM_ENG_TRQ 788;
BA_ "FlexKomSigStartPos" SG_ 416 CRC_TCM_ENG_TRQ 7;
BA_ "FlexKomSigLaenge" SG_ 416 CRC_TCM_ENG_TRQ 56;
BA_ "FlexKomSigName" SG_ 416 CRC_TCM_ENG_TRQ "ENG_TRQ_PKT";
BA_ "FlexKomComment" SG_ 416 CRC_TCM_ENG_TRQ "Engine torque packet for all transmissions";
BA_ "FlexKomIsMotorola" SG_ 416 CRC_TCM_ENG_TRQ 1;
BA_ "GenSigSNA" SG_ 416 CRC_TCM_ENG_TRQ "FFh";
BA_ "GenSigCycleTime" SG_ 436 BrkTrq_Rq_DAS 20;
BA_ "FlexKomSigStartValue" SG_ 436 BrkTrq_Rq_DAS "0FFF0000000000FFh";
BA_ "GenSigStartValue" SG_ 436 BrkTrq_Rq_DAS 4095;
BA_ "FlexKomSID" SG_ 436 BrkTrq_Rq_DAS 402;
BA_ "FlexKomSigStartPos" SG_ 436 BrkTrq_Rq_DAS 7;
BA_ "FlexKomSigLaenge" SG_ 436 BrkTrq_Rq_DAS 64;
BA_ "FlexKomSigName" SG_ 436 BrkTrq_Rq_DAS "DAS_A1_PKT";
BA_ "FlexKomComment" SG_ 436 BrkTrq_Rq_DAS "DAS_A1 Packet";
BA_ "FlexKomIsMotorola" SG_ 436 BrkTrq_Rq_DAS 1;
BA_ "GenSigSNA" SG_ 436 BrkTrq_Rq_DAS "FFFh";
BA_ "GenSigCycleTime" SG_ 436 AS_Brk 20;
BA_ "FlexKomSigStartValue" SG_ 436 AS_Brk "0FFF0000000000FFh";
BA_ "GenSigTimeout_ORC" SG_ 436 AS_Brk 70;
BA_ "FlexKomSID" SG_ 436 AS_Brk 402;
BA_ "FlexKomSigStartPos" SG_ 436 AS_Brk 7;
BA_ "FlexKomSigLaenge" SG_ 436 AS_Brk 64;
BA_ "FlexKomSigName" SG_ 436 AS_Brk "DAS_A1_PKT";
BA_ "FlexKomComment" SG_ 436 AS_Brk "DAS_A1 Packet";
BA_ "FlexKomIsMotorola" SG_ 436 AS_Brk 1;
BA_ "GenSigSNA" SG_ 436 AS_Brk "7h";
BA_ "GenSigCycleTime" SG_ 436 SpLmpSprsn 20;
BA_ "FlexKomSigStartValue" SG_ 436 SpLmpSprsn "0FFF0000000000FFh";
BA_ "FlexKomSID" SG_ 436 SpLmpSprsn 402;
BA_ "FlexKomSigStartPos" SG_ 436 SpLmpSprsn 7;
BA_ "FlexKomSigLaenge" SG_ 436 SpLmpSprsn 64;
BA_ "FlexKomSigName" SG_ 436 SpLmpSprsn "DAS_A1_PKT";
BA_ "FlexKomComment" SG_ 436 SpLmpSprsn "DAS_A1 Packet";
BA_ "FlexKomIsMotorola" SG_ 436 SpLmpSprsn 1;
BA_ "GenSigSNA" SG_ 436 SpLmpSprsn "0h";
BA_ "GenSigCycleTime" SG_ 436 GrMax_Rq_DAS 20;
BA_ "FlexKomSigStartValue" SG_ 436 GrMax_Rq_DAS "0FFF0000000000FFh";
BA_ "GenSigTimeout_ORC" SG_ 436 GrMax_Rq_DAS 70;
BA_ "FlexKomSID" SG_ 436 GrMax_Rq_DAS 402;
BA_ "FlexKomSigStartPos" SG_ 436 GrMax_Rq_DAS 7;
BA_ "FlexKomSigLaenge" SG_ 436 GrMax_Rq_DAS 64;
BA_ "FlexKomSigName" SG_ 436 GrMax_Rq_DAS "DAS_A1_PKT";
BA_ "FlexKomComment" SG_ 436 GrMax_Rq_DAS "DAS_A1 Packet";
BA_ "FlexKomIsMotorola" SG_ 436 GrMax_Rq_DAS 1;
BA_ "GenSigSNA" SG_ 436 GrMax_Rq_DAS "0h";
BA_ "GenSigCycleTime" SG_ 436 GrMin_Rq_DAS 20;
BA_ "FlexKomSigStartValue" SG_ 436 GrMin_Rq_DAS "0FFF0000000000FFh";
BA_ "GenSigTimeout_ORC" SG_ 436 GrMin_Rq_DAS 70;
BA_ "FlexKomSID" SG_ 436 GrMin_Rq_DAS 402;
BA_ "FlexKomSigStartPos" SG_ 436 GrMin_Rq_DAS 7;
BA_ "FlexKomSigLaenge" SG_ 436 GrMin_Rq_DAS 64;
BA_ "FlexKomSigName" SG_ 436 GrMin_Rq_DAS "DAS_A1_PKT";
BA_ "FlexKomComment" SG_ 436 GrMin_Rq_DAS "DAS_A1 Packet";
BA_ "FlexKomIsMotorola" SG_ 436 GrMin_Rq_DAS 1;
BA_ "GenSigSNA" SG_ 436 GrMin_Rq_DAS "0h";
BA_ "GenSigCycleTime" SG_ 436 DynFLDS_Supp_Rq_DAS 20;
BA_ "FlexKomSigStartValue" SG_ 436 DynFLDS_Supp_Rq_DAS "0FFF0000000000FFh";
BA_ "GenSigTimeout_ORC" SG_ 436 DynFLDS_Supp_Rq_DAS 70;
BA_ "FlexKomSID" SG_ 436 DynFLDS_Supp_Rq_DAS 402;
BA_ "FlexKomSigStartPos" SG_ 436 DynFLDS_Supp_Rq_DAS 7;
BA_ "FlexKomSigLaenge" SG_ 436 DynFLDS_Supp_Rq_DAS 64;
BA_ "FlexKomSigName" SG_ 436 DynFLDS_Supp_Rq_DAS "DAS_A1_PKT";
BA_ "FlexKomComment" SG_ 436 DynFLDS_Supp_Rq_DAS "DAS_A1 Packet";
BA_ "FlexKomIsMotorola" SG_ 436 DynFLDS_Supp_Rq_DAS 1;
BA_ "GenSigSNA" SG_ 436 DynFLDS_Supp_Rq_DAS "0h";
BA_ "GenSigCycleTime" SG_ 436 EngTrq_Rq_DAS 20;
BA_ "FlexKomSigStartValue" SG_ 436 EngTrq_Rq_DAS "0FFF0000000000FFh";
BA_ "GenSigTimeout_ORC" SG_ 436 EngTrq_Rq_DAS 70;
BA_ "FlexKomSID" SG_ 436 EngTrq_Rq_DAS 402;
BA_ "FlexKomSigStartPos" SG_ 436 EngTrq_Rq_DAS 7;
BA_ "FlexKomSigLaenge" SG_ 436 EngTrq_Rq_DAS 64;
BA_ "FlexKomSigName" SG_ 436 EngTrq_Rq_DAS "DAS_A1_PKT";
BA_ "FlexKomComment" SG_ 436 EngTrq_Rq_DAS "DAS_A1 Packet";
BA_ "FlexKomIsMotorola" SG_ 436 EngTrq_Rq_DAS 1;
BA_ "GenSigSNA" SG_ 436 EngTrq_Rq_DAS "1FFFh";
BA_ "GenSigCycleTime" SG_ 436 EngTrqMax_Rq_DAS 20;
BA_ "FlexKomSigStartValue" SG_ 436 EngTrqMax_Rq_DAS "0FFF0000000000FFh";
BA_ "GenSigTimeout_ORC" SG_ 436 EngTrqMax_Rq_DAS 70;
BA_ "FlexKomSID" SG_ 436 EngTrqMax_Rq_DAS 402;
BA_ "FlexKomSigStartPos" SG_ 436 EngTrqMax_Rq_DAS 7;
BA_ "FlexKomSigLaenge" SG_ 436 EngTrqMax_Rq_DAS 64;
BA_ "FlexKomSigName" SG_ 436 EngTrqMax_Rq_DAS "DAS_A1_PKT";
BA_ "FlexKomComment" SG_ 436 EngTrqMax_Rq_DAS "DAS_A1 Packet";
BA_ "FlexKomIsMotorola" SG_ 436 EngTrqMax_Rq_DAS 1;
BA_ "GenSigSNA" SG_ 436 EngTrqMax_Rq_DAS "0h";
BA_ "GenSigCycleTime" SG_ 436 EngTrqMin_Rq_DAS 20;
BA_ "FlexKomSigStartValue" SG_ 436 EngTrqMin_Rq_DAS "0FFF0000000000FFh";
BA_ "GenSigTimeout_ORC" SG_ 436 EngTrqMin_Rq_DAS 70;
BA_ "FlexKomSID" SG_ 436 EngTrqMin_Rq_DAS 402;
BA_ "FlexKomSigStartPos" SG_ 436 EngTrqMin_Rq_DAS 7;
BA_ "FlexKomSigLaenge" SG_ 436 EngTrqMin_Rq_DAS 64;
BA_ "FlexKomSigName" SG_ 436 EngTrqMin_Rq_DAS "DAS_A1_PKT";
BA_ "FlexKomComment" SG_ 436 EngTrqMin_Rq_DAS "DAS_A1 Packet";
BA_ "FlexKomIsMotorola" SG_ 436 EngTrqMin_Rq_DAS 1;
BA_ "GenSigSNA" SG_ 436 EngTrqMin_Rq_DAS "0h";
BA_ "GenSigCycleTime" SG_ 436 ACC_Can 20;
BA_ "FlexKomSigStartValue" SG_ 436 ACC_Can "0FFF0000000000FFh";
BA_ "GenSigTimeout_IC" SG_ 436 ACC_Can 210;
BA_ "GenSigTimeout_ORC" SG_ 436 ACC_Can 70;
BA_ "FlexKomSID" SG_ 436 ACC_Can 402;
BA_ "FlexKomSigStartPos" SG_ 436 ACC_Can 7;
BA_ "FlexKomSigLaenge" SG_ 436 ACC_Can 64;
BA_ "FlexKomSigName" SG_ 436 ACC_Can "DAS_A1_PKT";
BA_ "FlexKomComment" SG_ 436 ACC_Can "DAS_A1 Packet";
BA_ "FlexKomIsMotorola" SG_ 436 ACC_Can 1;
BA_ "GenSigSNA" SG_ 436 ACC_Can "0h";
BA_ "GenSigCycleTime" SG_ 436 DAS_Ok 20;
BA_ "FlexKomSigStartValue" SG_ 436 DAS_Ok "0FFF0000000000FFh";
BA_ "GenSigTimeout_ORC" SG_ 436 DAS_Ok 70;
BA_ "FlexKomSID" SG_ 436 DAS_Ok 402;
BA_ "FlexKomSigStartPos" SG_ 436 DAS_Ok 7;
BA_ "FlexKomSigLaenge" SG_ 436 DAS_Ok 64;
BA_ "FlexKomSigName" SG_ 436 DAS_Ok "DAS_A1_PKT";
BA_ "FlexKomComment" SG_ 436 DAS_Ok "DAS_A1 Packet";
BA_ "FlexKomIsMotorola" SG_ 436 DAS_Ok 1;
BA_ "GenSigSNA" SG_ 436 DAS_Ok "0h";
BA_ "GenSigCycleTime" SG_ 436 SPCR_Md_Rq_DAS 20;
BA_ "FlexKomSigStartValue" SG_ 436 SPCR_Md_Rq_DAS "0FFF0000000000FFh";
BA_ "GenSigTimeout_ORC" SG_ 436 SPCR_Md_Rq_DAS 70;
BA_ "FlexKomSID" SG_ 436 SPCR_Md_Rq_DAS 402;
BA_ "FlexKomSigStartPos" SG_ 436 SPCR_Md_Rq_DAS 7;
BA_ "FlexKomSigLaenge" SG_ 436 SPCR_Md_Rq_DAS 64;
BA_ "FlexKomSigName" SG_ 436 SPCR_Md_Rq_DAS "DAS_A1_PKT";
BA_ "FlexKomComment" SG_ 436 SPCR_Md_Rq_DAS "DAS_A1 Packet";
BA_ "FlexKomIsMotorola" SG_ 436 SPCR_Md_Rq_DAS 1;
BA_ "GenSigSNA" SG_ 436 SPCR_Md_Rq_DAS "3h";
BA_ "GenSigCycleTime" SG_ 436 MC_DAS_A1 20;
BA_ "FlexKomSigStartValue" SG_ 436 MC_DAS_A1 "0FFF0000000000FFh";
BA_ "GenSigTimeout_ORC" SG_ 436 MC_DAS_A1 70;
BA_ "FlexKomSID" SG_ 436 MC_DAS_A1 402;
BA_ "FlexKomSigStartPos" SG_ 436 MC_DAS_A1 7;
BA_ "FlexKomSigLaenge" SG_ 436 MC_DAS_A1 64;
BA_ "FlexKomSigName" SG_ 436 MC_DAS_A1 "DAS_A1_PKT";
BA_ "FlexKomComment" SG_ 436 MC_DAS_A1 "DAS_A1 Packet";
BA_ "FlexKomIsMotorola" SG_ 436 MC_DAS_A1 1;
BA_ "GenSigSNA" SG_ 436 MC_DAS_A1 "0h";
BA_ "GenSigCycleTime" SG_ 436 CRC_DAS_A1 20;
BA_ "FlexKomSigStartValue" SG_ 436 CRC_DAS_A1 "0FFF0000000000FFh";
BA_ "GenSigStartValue" SG_ 436 CRC_DAS_A1 255;
BA_ "GenSigTimeout_ORC" SG_ 436 CRC_DAS_A1 70;
BA_ "FlexKomSID" SG_ 436 CRC_DAS_A1 402;
BA_ "FlexKomSigStartPos" SG_ 436 CRC_DAS_A1 7;
BA_ "FlexKomSigLaenge" SG_ 436 CRC_DAS_A1 64;
BA_ "FlexKomSigName" SG_ 436 CRC_DAS_A1 "DAS_A1_PKT";
BA_ "FlexKomComment" SG_ 436 CRC_DAS_A1 "DAS_A1 Packet";
BA_ "FlexKomIsMotorola" SG_ 436 CRC_DAS_A1 1;
BA_ "GenSigSNA" SG_ 436 CRC_DAS_A1 "FFh";
BA_ "GenSigSendType" SG_ 448 RFFuncReq 5;
BA_ "GenSigCycleTime" SG_ 448 RFFuncReq 200;
BA_ "FlexKomSigStartValue" SG_ 448 RFFuncReq "000000000000h";
BA_ "FlexKomSID" SG_ 448 RFFuncReq 1037;
BA_ "FlexKomSigStartPos" SG_ 448 RFFuncReq 7;
BA_ "FlexKomSigLaenge" SG_ 448 RFFuncReq 48;
BA_ "FlexKomSigName" SG_ 448 RFFuncReq "RFHUB_A2_Pkt";
BA_ "FlexKomComment" SG_ 448 RFFuncReq "RFHUB_A2_Pkt";
BA_ "FlexKomIsMotorola" SG_ 448 RFFuncReq 1;
BA_ "GenSigSNA" SG_ 448 RFFuncReq "1Fh";
BA_ "GenSigSendType" SG_ 448 RFReq 5;
BA_ "GenSigCycleTime" SG_ 448 RFReq 200;
BA_ "FlexKomSigStartValue" SG_ 448 RFReq "000000000000h";
BA_ "FlexKomSID" SG_ 448 RFReq 1037;
BA_ "FlexKomSigStartPos" SG_ 448 RFReq 7;
BA_ "FlexKomSigLaenge" SG_ 448 RFReq 48;
BA_ "FlexKomSigName" SG_ 448 RFReq "RFHUB_A2_Pkt";
BA_ "FlexKomComment" SG_ 448 RFReq "RFHUB_A2_Pkt";
BA_ "FlexKomIsMotorola" SG_ 448 RFReq 1;
BA_ "GenSigSNA" SG_ 448 RFReq "7h";
BA_ "GenSigSendType" SG_ 448 RFAuthCode 5;
BA_ "GenSigCycleTime" SG_ 448 RFAuthCode 200;
BA_ "FlexKomSigStartValue" SG_ 448 RFAuthCode "000000000000h";
BA_ "FlexKomSID" SG_ 448 RFAuthCode 1037;
BA_ "FlexKomSigStartPos" SG_ 448 RFAuthCode 7;
BA_ "FlexKomSigLaenge" SG_ 448 RFAuthCode 48;
BA_ "FlexKomSigName" SG_ 448 RFAuthCode "RFHUB_A2_Pkt";
BA_ "FlexKomComment" SG_ 448 RFAuthCode "RFHUB_A2_Pkt";
BA_ "FlexKomIsMotorola" SG_ 448 RFAuthCode 1;
BA_ "GenSigSNA" SG_ 448 RFAuthCode "FFFFh";
BA_ "GenSigSendType" SG_ 448 RFCfgReq 5;
BA_ "GenSigCycleTime" SG_ 448 RFCfgReq 200;
BA_ "FlexKomSigStartValue" SG_ 448 RFCfgReq "000000000000h";
BA_ "FlexKomSID" SG_ 448 RFCfgReq 1037;
BA_ "FlexKomSigStartPos" SG_ 448 RFCfgReq 7;
BA_ "FlexKomSigLaenge" SG_ 448 RFCfgReq 48;
BA_ "FlexKomSigName" SG_ 448 RFCfgReq "RFHUB_A2_Pkt";
BA_ "FlexKomComment" SG_ 448 RFCfgReq "RFHUB_A2_Pkt";
BA_ "FlexKomIsMotorola" SG_ 448 RFCfgReq 1;
BA_ "GenSigSNA" SG_ 448 RFCfgReq "7h";
BA_ "GenSigSendType" SG_ 448 RFFobNum 5;
BA_ "GenSigCycleTime" SG_ 448 RFFobNum 200;
BA_ "FlexKomSigStartValue" SG_ 448 RFFobNum "000000000000h";
BA_ "FlexKomSID" SG_ 448 RFFobNum 1037;
BA_ "FlexKomSigStartPos" SG_ 448 RFFobNum 7;
BA_ "FlexKomSigLaenge" SG_ 448 RFFobNum 48;
BA_ "FlexKomSigName" SG_ 448 RFFobNum "RFHUB_A2_Pkt";
BA_ "FlexKomComment" SG_ 448 RFFobNum "RFHUB_A2_Pkt";
BA_ "FlexKomIsMotorola" SG_ 448 RFFobNum 1;
BA_ "GenSigSNA" SG_ 448 RFFobNum "Fh";
BA_ "GenSigSendType" SG_ 448 PE_ENABLE 5;
BA_ "GenSigCycleTime" SG_ 448 PE_ENABLE 200;
BA_ "FlexKomSigStartValue" SG_ 448 PE_ENABLE "000000000000h";
BA_ "GenSigTimeout_IC" SG_ 448 PE_ENABLE 2100;
BA_ "FlexKomSID" SG_ 448 PE_ENABLE 1037;
BA_ "FlexKomSigStartPos" SG_ 448 PE_ENABLE 7;
BA_ "FlexKomSigLaenge" SG_ 448 PE_ENABLE 48;
BA_ "FlexKomSigName" SG_ 448 PE_ENABLE "RFHUB_A2_Pkt";
BA_ "FlexKomComment" SG_ 448 PE_ENABLE "RFHUB_A2_Pkt";
BA_ "FlexKomIsMotorola" SG_ 448 PE_ENABLE 1;
BA_ "GenSigSNA" SG_ 448 PE_ENABLE "0h";
BA_ "GenSigSendType" SG_ 448 ImmStat 5;
BA_ "GenSigCycleTime" SG_ 448 ImmStat 200;
BA_ "FlexKomSigStartValue" SG_ 448 ImmStat "000000000000h";
BA_ "FlexKomSID" SG_ 448 ImmStat 1037;
BA_ "FlexKomSigStartPos" SG_ 448 ImmStat 7;
BA_ "FlexKomSigLaenge" SG_ 448 ImmStat 48;
BA_ "FlexKomSigName" SG_ 448 ImmStat "RFHUB_A2_Pkt";
BA_ "FlexKomComment" SG_ 448 ImmStat "RFHUB_A2_Pkt";
BA_ "FlexKomIsMotorola" SG_ 448 ImmStat 1;
BA_ "GenSigSNA" SG_ 448 ImmStat "3h";
BA_ "GenSigSendType" SG_ 448 ImmChmReq 5;
BA_ "GenSigCycleTime" SG_ 448 ImmChmReq 200;
BA_ "FlexKomSigStartValue" SG_ 448 ImmChmReq "000000000000h";
BA_ "GenSigTimeout_IC" SG_ 448 ImmChmReq 2100;
BA_ "FlexKomSID" SG_ 448 ImmChmReq 1037;
BA_ "FlexKomSigStartPos" SG_ 448 ImmChmReq 7;
BA_ "FlexKomSigLaenge" SG_ 448 ImmChmReq 48;
BA_ "FlexKomSigName" SG_ 448 ImmChmReq "RFHUB_A2_Pkt";
BA_ "FlexKomComment" SG_ 448 ImmChmReq "RFHUB_A2_Pkt";
BA_ "FlexKomIsMotorola" SG_ 448 ImmChmReq 1;
BA_ "GenSigSNA" SG_ 448 ImmChmReq "3h";
BA_ "GenSigSendType" SG_ 448 ImmHMIReq 5;
BA_ "GenSigCycleTime" SG_ 448 ImmHMIReq 200;
BA_ "FlexKomSigStartValue" SG_ 448 ImmHMIReq "000000000000h";
BA_ "FlexKomSID" SG_ 448 ImmHMIReq 1037;
BA_ "FlexKomSigStartPos" SG_ 448 ImmHMIReq 7;
BA_ "FlexKomSigLaenge" SG_ 448 ImmHMIReq 48;
BA_ "FlexKomSigName" SG_ 448 ImmHMIReq "RFHUB_A2_Pkt";
BA_ "FlexKomComment" SG_ 448 ImmHMIReq "RFHUB_A2_Pkt";
BA_ "FlexKomIsMotorola" SG_ 448 ImmHMIReq 1;
BA_ "GenSigSNA" SG_ 448 ImmHMIReq "7h";
BA_ "GenSigSendType" SG_ 448 ExtrRearSwRq 5;
BA_ "GenSigCycleTime" SG_ 448 ExtrRearSwRq 200;
BA_ "FlexKomSigStartValue" SG_ 448 ExtrRearSwRq "000000000000h";
BA_ "FlexKomSID" SG_ 448 ExtrRearSwRq 1037;
BA_ "FlexKomSigStartPos" SG_ 448 ExtrRearSwRq 7;
BA_ "FlexKomSigLaenge" SG_ 448 ExtrRearSwRq 48;
BA_ "FlexKomSigName" SG_ 448 ExtrRearSwRq "RFHUB_A2_Pkt";
BA_ "FlexKomComment" SG_ 448 ExtrRearSwRq "RFHUB_A2_Pkt";
BA_ "FlexKomIsMotorola" SG_ 448 ExtrRearSwRq 1;
BA_ "GenSigSNA" SG_ 448 ExtrRearSwRq "0h";
BA_ "GenSigSendType" SG_ 448 PE_BASIC_RQ 5;
BA_ "GenSigCycleTime" SG_ 448 PE_BASIC_RQ 200;
BA_ "FlexKomSigStartValue" SG_ 448 PE_BASIC_RQ "000000000000h";
BA_ "FlexKomSID" SG_ 448 PE_BASIC_RQ 1037;
BA_ "FlexKomSigStartPos" SG_ 448 PE_BASIC_RQ 7;
BA_ "FlexKomSigLaenge" SG_ 448 PE_BASIC_RQ 48;
BA_ "FlexKomSigName" SG_ 448 PE_BASIC_RQ "RFHUB_A2_Pkt";
BA_ "FlexKomComment" SG_ 448 PE_BASIC_RQ "RFHUB_A2_Pkt";
BA_ "FlexKomIsMotorola" SG_ 448 PE_BASIC_RQ 1;
BA_ "GenSigSNA" SG_ 448 PE_BASIC_RQ "Fh";
BA_ "GenSigSendType" SG_ 448 KeyProgramSts 5;
BA_ "GenSigCycleTime" SG_ 448 KeyProgramSts 200;
BA_ "FlexKomSigStartValue" SG_ 448 KeyProgramSts "000000000000h";
BA_ "GenSigTimeout_IC" SG_ 448 KeyProgramSts 2100;
BA_ "FlexKomSID" SG_ 448 KeyProgramSts 1037;
BA_ "FlexKomSigStartPos" SG_ 448 KeyProgramSts 7;
BA_ "FlexKomSigLaenge" SG_ 448 KeyProgramSts 48;
BA_ "FlexKomSigName" SG_ 448 KeyProgramSts "RFHUB_A2_Pkt";
BA_ "FlexKomComment" SG_ 448 KeyProgramSts "RFHUB_A2_Pkt";
BA_ "FlexKomIsMotorola" SG_ 448 KeyProgramSts 1;
BA_ "GenSigSNA" SG_ 448 KeyProgramSts "Fh";
BA_ "GenSigSendType" SG_ 456 VTA_STAT 5;
BA_ "GenSigCycleTime" SG_ 456 VTA_STAT 500;
BA_ "FlexKomSigStartValue" SG_ 456 VTA_STAT "00000000h";
BA_ "FlexKomSID" SG_ 456 VTA_STAT 1207;
BA_ "FlexKomSigStartPos" SG_ 456 VTA_STAT 7;
BA_ "FlexKomSigLaenge" SG_ 456 VTA_STAT 32;
BA_ "FlexKomSigName" SG_ 456 VTA_STAT "VTA_PKT";
BA_ "FlexKomComment" SG_ 456 VTA_STAT "Vehicle theft alarm packet";
BA_ "FlexKomIsMotorola" SG_ 456 VTA_STAT 1;
BA_ "GenSigSNA" SG_ 456 VTA_STAT "7h";
BA_ "GenSigSendType" SG_ 456 MOT_DSBL_RQ 5;
BA_ "GenSigCycleTime" SG_ 456 MOT_DSBL_RQ 500;
BA_ "FlexKomSigStartValue" SG_ 456 MOT_DSBL_RQ "00000000h";
BA_ "FlexKomSID" SG_ 456 MOT_DSBL_RQ 1207;
BA_ "FlexKomSigStartPos" SG_ 456 MOT_DSBL_RQ 7;
BA_ "FlexKomSigLaenge" SG_ 456 MOT_DSBL_RQ 32;
BA_ "FlexKomSigName" SG_ 456 MOT_DSBL_RQ "VTA_PKT";
BA_ "FlexKomComment" SG_ 456 MOT_DSBL_RQ "Vehicle theft alarm packet";
BA_ "FlexKomIsMotorola" SG_ 456 MOT_DSBL_RQ 1;
BA_ "GenSigSNA" SG_ 456 MOT_DSBL_RQ "0h";
BA_ "GenSigSendType" SG_ 456 DLY_5_SEC 5;
BA_ "GenSigCycleTime" SG_ 456 DLY_5_SEC 500;
BA_ "FlexKomSigStartValue" SG_ 456 DLY_5_SEC "00000000h";
BA_ "FlexKomSID" SG_ 456 DLY_5_SEC 1207;
BA_ "FlexKomSigStartPos" SG_ 456 DLY_5_SEC 7;
BA_ "FlexKomSigLaenge" SG_ 456 DLY_5_SEC 32;
BA_ "FlexKomSigName" SG_ 456 DLY_5_SEC "VTA_PKT";
BA_ "FlexKomComment" SG_ 456 DLY_5_SEC "Vehicle theft alarm packet";
BA_ "FlexKomIsMotorola" SG_ 456 DLY_5_SEC 1;
BA_ "GenSigSNA" SG_ 456 DLY_5_SEC "0h";
BA_ "GenSigSendType" SG_ 456 LKOUT_1_MIN 5;
BA_ "GenSigCycleTime" SG_ 456 LKOUT_1_MIN 500;
BA_ "FlexKomSigStartValue" SG_ 456 LKOUT_1_MIN "00000000h";
BA_ "FlexKomSID" SG_ 456 LKOUT_1_MIN 1207;
BA_ "FlexKomSigStartPos" SG_ 456 LKOUT_1_MIN 7;
BA_ "FlexKomSigLaenge" SG_ 456 LKOUT_1_MIN 32;
BA_ "FlexKomSigName" SG_ 456 LKOUT_1_MIN "VTA_PKT";
BA_ "FlexKomComment" SG_ 456 LKOUT_1_MIN "Vehicle theft alarm packet";
BA_ "FlexKomIsMotorola" SG_ 456 LKOUT_1_MIN 1;
BA_ "GenSigSNA" SG_ 456 LKOUT_1_MIN "0h";
BA_ "GenSigSendType" SG_ 456 VTA_AUTH 5;
BA_ "GenSigCycleTime" SG_ 456 VTA_AUTH 500;
BA_ "FlexKomSigStartValue" SG_ 456 VTA_AUTH "00000000h";
BA_ "FlexKomSID" SG_ 456 VTA_AUTH 1207;
BA_ "FlexKomSigStartPos" SG_ 456 VTA_AUTH 7;
BA_ "FlexKomSigLaenge" SG_ 456 VTA_AUTH 32;
BA_ "FlexKomSigName" SG_ 456 VTA_AUTH "VTA_PKT";
BA_ "FlexKomComment" SG_ 456 VTA_AUTH "Vehicle theft alarm packet";
BA_ "FlexKomIsMotorola" SG_ 456 VTA_AUTH 1;
BA_ "GenSigSNA" SG_ 456 VTA_AUTH "0h";
BA_ "GenSigSendType" SG_ 464 EPP_FAULT 5;
BA_ "GenSigCycleTime" SG_ 464 EPP_FAULT 1000;
BA_ "FlexKomSigStartValue" SG_ 464 EPP_FAULT "00h";
BA_ "GenSigTimeout_IC" SG_ 464 EPP_FAULT 10500;
BA_ "GenSigTimeout_ETM" SG_ 464 EPP_FAULT 10500;
BA_ "FlexKomSID" SG_ 464 EPP_FAULT 1359;
BA_ "FlexKomSigLaenge" SG_ 464 EPP_FAULT 1;
BA_ "FlexKomSigName" SG_ 464 EPP_FAULT "EPP_FAULT";
BA_ "FlexKomComment" SG_ 464 EPP_FAULT "Pedestrian protection ORC fault; True = [1]";
BA_ "FlexKomIsMotorola" SG_ 464 EPP_FAULT 1;
BA_ "GenSigSNA" SG_ 464 EPP_FAULT "0h";
BA_ "GenSigSendType" SG_ 464 ORC_A1_Tog 5;
BA_ "GenSigCycleTime" SG_ 464 ORC_A1_Tog 1000;
BA_ "FlexKomSigStartValue" SG_ 464 ORC_A1_Tog "00h";
BA_ "FlexKomSID" SG_ 464 ORC_A1_Tog 1902;
BA_ "FlexKomSigStartPos" SG_ 464 ORC_A1_Tog 1;
BA_ "FlexKomSigLaenge" SG_ 464 ORC_A1_Tog 1;
BA_ "FlexKomSigName" SG_ 464 ORC_A1_Tog "ORC_A1_Tog";
BA_ "FlexKomComment" SG_ 464 ORC_A1_Tog "ORC_A1 toggle bit; True = [1]";
BA_ "FlexKomIsMotorola" SG_ 464 ORC_A1_Tog 1;
BA_ "GenSigSNA" SG_ 464 ORC_A1_Tog "0h";
BA_ "GenSigSendType" SG_ 464 SRS_IndLmp_Rq 5;
BA_ "GenSigCycleTime" SG_ 464 SRS_IndLmp_Rq 1000;
BA_ "FlexKomSigStartValue" SG_ 464 SRS_IndLmp_Rq "02h";
BA_ "GenSigStartValue" SG_ 464 SRS_IndLmp_Rq 2;
BA_ "GenSigTimeout_CBC" SG_ 464 SRS_IndLmp_Rq 5500;
BA_ "GenSigTimeout_IC" SG_ 464 SRS_IndLmp_Rq 10500;
BA_ "GenSigTimeout_ETM" SG_ 464 SRS_IndLmp_Rq 10500;
BA_ "FlexKomSID" SG_ 464 SRS_IndLmp_Rq 329;
BA_ "FlexKomSigStartPos" SG_ 464 SRS_IndLmp_Rq 3;
BA_ "FlexKomSigLaenge" SG_ 464 SRS_IndLmp_Rq 2;
BA_ "FlexKomSigName" SG_ 464 SRS_IndLmp_Rq "SRS_IndLmp_Rq";
BA_ "FlexKomComment" SG_ 464 SRS_IndLmp_Rq "SRS indication lamp request";
BA_ "FlexKomIsMotorola" SG_ 464 SRS_IndLmp_Rq 1;
BA_ "GenSigSNA" SG_ 464 SRS_IndLmp_Rq "3h";
BA_ "GenSigSendType" SG_ 464 DSBL_PSG_LMP 5;
BA_ "GenSigCycleTime" SG_ 464 DSBL_PSG_LMP 1000;
BA_ "FlexKomSigStartValue" SG_ 464 DSBL_PSG_LMP "00h";
BA_ "GenSigTimeout_IC" SG_ 464 DSBL_PSG_LMP 10500;
BA_ "GenSigTimeout_ETM" SG_ 464 DSBL_PSG_LMP 10500;
BA_ "FlexKomSID" SG_ 464 DSBL_PSG_LMP 328;
BA_ "FlexKomSigStartPos" SG_ 464 DSBL_PSG_LMP 4;
BA_ "FlexKomSigLaenge" SG_ 464 DSBL_PSG_LMP 1;
BA_ "FlexKomSigName" SG_ 464 DSBL_PSG_LMP "DSBL_PSG_LMP";
BA_ "FlexKomComment" SG_ 464 DSBL_PSG_LMP "Disable passenger airbag lamp; on=[1]";
BA_ "FlexKomIsMotorola" SG_ 464 DSBL_PSG_LMP 1;
BA_ "GenSigSNA" SG_ 464 DSBL_PSG_LMP "0h";
BA_ "GenSigSendType" SG_ 464 PsngrBagSts 5;
BA_ "GenSigCycleTime" SG_ 464 PsngrBagSts 1000;
BA_ "FlexKomSigStartValue" SG_ 464 PsngrBagSts "02h";
BA_ "GenSigStartValue" SG_ 464 PsngrBagSts 2;
BA_ "GenSigTimeout_ETM" SG_ 464 PsngrBagSts 10500;
BA_ "FlexKomSID" SG_ 464 PsngrBagSts 1525;
BA_ "FlexKomSigStartPos" SG_ 464 PsngrBagSts 6;
BA_ "FlexKomSigLaenge" SG_ 464 PsngrBagSts 2;
BA_ "FlexKomSigName" SG_ 464 PsngrBagSts "PsngrBagSts";
BA_ "FlexKomComment" SG_ 464 PsngrBagSts "Passenger Airbag Status";
BA_ "FlexKomIsMotorola" SG_ 464 PsngrBagSts 1;
BA_ "GenSigSNA" SG_ 464 PsngrBagSts "3h";
BA_ "GenSigSendType" SG_ 464 ORC_A1_Par 5;
BA_ "GenSigCycleTime" SG_ 464 ORC_A1_Par 1000;
BA_ "FlexKomSigStartValue" SG_ 464 ORC_A1_Par "00h";
BA_ "FlexKomSID" SG_ 464 ORC_A1_Par 1903;
BA_ "FlexKomSigStartPos" SG_ 464 ORC_A1_Par 7;
BA_ "FlexKomSigLaenge" SG_ 464 ORC_A1_Par 1;
BA_ "FlexKomSigName" SG_ 464 ORC_A1_Par "ORC_A1_Par";
BA_ "FlexKomComment" SG_ 464 ORC_A1_Par "ORC_A1 even parity bit; True = [1]";
BA_ "FlexKomIsMotorola" SG_ 464 ORC_A1_Par 1;
BA_ "GenSigSNA" SG_ 464 ORC_A1_Par "0h";
BA_ "GenSigSendType" SG_ 464 OC_P_ORC 5;
BA_ "GenSigCycleTime" SG_ 464 OC_P_ORC 1000;
BA_ "FlexKomSigStartValue" SG_ 464 OC_P_ORC "07h";
BA_ "GenSigStartValue" SG_ 464 OC_P_ORC 7;
BA_ "GenSigTimeout_IC" SG_ 464 OC_P_ORC 10500;
BA_ "GenSigTimeout_ETM" SG_ 464 OC_P_ORC 10500;
BA_ "FlexKomSID" SG_ 464 OC_P_ORC 326;
BA_ "FlexKomSigStartPos" SG_ 464 OC_P_ORC 11;
BA_ "FlexKomSigLaenge" SG_ 464 OC_P_ORC 4;
BA_ "FlexKomSigName" SG_ 464 OC_P_ORC "OC_P_Stat_ORC";
BA_ "FlexKomComment" SG_ 464 OC_P_ORC "Passenger occupant classification system state";
BA_ "FlexKomIsMotorola" SG_ 464 OC_P_ORC 1;
BA_ "GenSigSNA" SG_ 464 OC_P_ORC "7h";
BA_ "GenSigSendType" SG_ 464 OC_P_Flt_ORC 5;
BA_ "GenSigCycleTime" SG_ 464 OC_P_Flt_ORC 1000;
BA_ "FlexKomSigStartValue" SG_ 464 OC_P_Flt_ORC "07h";
BA_ "GenSigTimeout_IC" SG_ 464 OC_P_Flt_ORC 10500;
BA_ "GenSigTimeout_ETM" SG_ 464 OC_P_Flt_ORC 10500;
BA_ "FlexKomSID" SG_ 464 OC_P_Flt_ORC 326;
BA_ "FlexKomSigStartPos" SG_ 464 OC_P_Flt_ORC 11;
BA_ "FlexKomSigLaenge" SG_ 464 OC_P_Flt_ORC 4;
BA_ "FlexKomSigName" SG_ 464 OC_P_Flt_ORC "OC_P_Stat_ORC";
BA_ "FlexKomComment" SG_ 464 OC_P_Flt_ORC "Passenger occupant classification system state";
BA_ "FlexKomIsMotorola" SG_ 464 OC_P_Flt_ORC 1;
BA_ "GenSigSNA" SG_ 464 OC_P_Flt_ORC "0h";
BA_ "GenSigSendType" SG_ 464 DrvSbltUnFltr 5;
BA_ "GenSigCycleTime" SG_ 464 DrvSbltUnFltr 1000;
BA_ "FlexKomSigStartValue" SG_ 464 DrvSbltUnFltr "07h";
BA_ "GenSigStartValue" SG_ 464 DrvSbltUnFltr 7;
BA_ "FlexKomSID" SG_ 464 DrvSbltUnFltr 1814;
BA_ "FlexKomSigStartPos" SG_ 464 DrvSbltUnFltr 15;
BA_ "FlexKomSigLaenge" SG_ 464 DrvSbltUnFltr 3;
BA_ "FlexKomSigName" SG_ 464 DrvSbltUnFltr "DrvSbltUnFltr";
BA_ "FlexKomComment" SG_ 464 DrvSbltUnFltr "Drivers seat belt fault status - unfiltered";
BA_ "FlexKomIsMotorola" SG_ 464 DrvSbltUnFltr 1;
BA_ "GenSigSNA" SG_ 464 DrvSbltUnFltr "7h";
BA_ "GenSigSendType" SG_ 464 DRV_SEATBELT 5;
BA_ "GenSigCycleTime" SG_ 464 DRV_SEATBELT 1000;
BA_ "FlexKomSigStartValue" SG_ 464 DRV_SEATBELT "03h";
BA_ "GenSigStartValue" SG_ 464 DRV_SEATBELT 3;
BA_ "GenSigTimeout_CBC" SG_ 464 DRV_SEATBELT 10500;
BA_ "GenSigTimeout_IC" SG_ 464 DRV_SEATBELT 10500;
BA_ "GenSigTimeout_PTS" SG_ 464 DRV_SEATBELT 10500;
BA_ "GenSigTimeout_ETM" SG_ 464 DRV_SEATBELT 10500;
BA_ "FlexKomSID" SG_ 464 DRV_SEATBELT 330;
BA_ "FlexKomSigStartPos" SG_ 464 DRV_SEATBELT 17;
BA_ "FlexKomSigLaenge" SG_ 464 DRV_SEATBELT 2;
BA_ "FlexKomSigName" SG_ 464 DRV_SEATBELT "DRV_SEATBELT";
BA_ "FlexKomComment" SG_ 464 DRV_SEATBELT "Drivers seat belt status";
BA_ "FlexKomIsMotorola" SG_ 464 DRV_SEATBELT 1;
BA_ "GenSigSNA" SG_ 464 DRV_SEATBELT "3h";
BA_ "GenSigSendType" SG_ 464 PSG_SEATBELT 5;
BA_ "GenSigCycleTime" SG_ 464 PSG_SEATBELT 1000;
BA_ "FlexKomSigStartValue" SG_ 464 PSG_SEATBELT "03h";
BA_ "GenSigStartValue" SG_ 464 PSG_SEATBELT 3;
BA_ "GenSigTimeout_CBC" SG_ 464 PSG_SEATBELT 10500;
BA_ "GenSigTimeout_IC" SG_ 464 PSG_SEATBELT 10500;
BA_ "GenSigTimeout_ETM" SG_ 464 PSG_SEATBELT 10500;
BA_ "FlexKomSID" SG_ 464 PSG_SEATBELT 331;
BA_ "FlexKomSigStartPos" SG_ 464 PSG_SEATBELT 19;
BA_ "FlexKomSigLaenge" SG_ 464 PSG_SEATBELT 2;
BA_ "FlexKomSigName" SG_ 464 PSG_SEATBELT "PSG_SEATBELT";
BA_ "FlexKomComment" SG_ 464 PSG_SEATBELT "Passengers seat belt status";
BA_ "FlexKomIsMotorola" SG_ 464 PSG_SEATBELT 1;
BA_ "GenSigSNA" SG_ 464 PSG_SEATBELT "3h";
BA_ "GenSigSendType" SG_ 464 SBRDriverSeatConfigSts 5;
BA_ "GenSigCycleTime" SG_ 464 SBRDriverSeatConfigSts 1000;
BA_ "FlexKomSigStartValue" SG_ 464 SBRDriverSeatConfigSts "00h";
BA_ "FlexKomSID" SG_ 464 SBRDriverSeatConfigSts 1967;
BA_ "FlexKomSigStartPos" SG_ 464 SBRDriverSeatConfigSts 20;
BA_ "FlexKomSigLaenge" SG_ 464 SBRDriverSeatConfigSts 1;
BA_ "FlexKomSigName" SG_ 464 SBRDriverSeatConfigSts "SBRDriverSeatConfigSts";
BA_ "FlexKomComment" SG_ 464 SBRDriverSeatConfigSts "Driver seatbelt switch configuration; seat checked";
BA_ "FlexKomIsMotorola" SG_ 464 SBRDriverSeatConfigSts 1;
BA_ "GenSigSNA" SG_ 464 SBRDriverSeatConfigSts "0h";
BA_ "GenSigSendType" SG_ 464 SBRFtPsngrSeatConfigSts 5;
BA_ "GenSigCycleTime" SG_ 464 SBRFtPsngrSeatConfigSts 1000;
BA_ "FlexKomSigStartValue" SG_ 464 SBRFtPsngrSeatConfigSts "00h";
BA_ "FlexKomSID" SG_ 464 SBRFtPsngrSeatConfigSts 1966;
BA_ "FlexKomSigStartPos" SG_ 464 SBRFtPsngrSeatConfigSts 21;
BA_ "FlexKomSigLaenge" SG_ 464 SBRFtPsngrSeatConfigSts 1;
BA_ "FlexKomSigName" SG_ 464 SBRFtPsngrSeatConfigSts "SBRFtPsngrSeatConfigSts";
BA_ "FlexKomComment" SG_ 464 SBRFtPsngrSeatConfigSts "Front passenger seatbelt switch configuration; sea";
BA_ "FlexKomIsMotorola" SG_ 464 SBRFtPsngrSeatConfigSts 1;
BA_ "GenSigSNA" SG_ 464 SBRFtPsngrSeatConfigSts "0h";
BA_ "GenSigSendType" SG_ 464 OC_P_Fast_ORC 5;
BA_ "GenSigCycleTime" SG_ 464 OC_P_Fast_ORC 1000;
BA_ "FlexKomSigStartValue" SG_ 464 OC_P_Fast_ORC "03h";
BA_ "GenSigStartValue" SG_ 464 OC_P_Fast_ORC 3;
BA_ "GenSigTimeout_IC" SG_ 464 OC_P_Fast_ORC 10500;
BA_ "GenSigTimeout_ETM" SG_ 464 OC_P_Fast_ORC 10500;
BA_ "FlexKomSID" SG_ 464 OC_P_Fast_ORC 327;
BA_ "FlexKomSigStartPos" SG_ 464 OC_P_Fast_ORC 25;
BA_ "FlexKomSigLaenge" SG_ 464 OC_P_Fast_ORC 2;
BA_ "FlexKomSigName" SG_ 464 OC_P_Fast_ORC "OC_P_Fast_ORC";
BA_ "FlexKomComment" SG_ 464 OC_P_Fast_ORC "Occupant detection passenger fast [MGCG only]";
BA_ "FlexKomIsMotorola" SG_ 464 OC_P_Fast_ORC 1;
BA_ "GenSigSNA" SG_ 464 OC_P_Fast_ORC "3h";
BA_ "GenSigSendType" SG_ 464 PSG_ODS_STAT 5;
BA_ "GenSigCycleTime" SG_ 464 PSG_ODS_STAT 1000;
BA_ "FlexKomSigStartValue" SG_ 464 PSG_ODS_STAT "03h";
BA_ "GenSigStartValue" SG_ 464 PSG_ODS_STAT 3;
BA_ "GenSigTimeout_CBC" SG_ 464 PSG_ODS_STAT 10500;
BA_ "GenSigTimeout_IC" SG_ 464 PSG_ODS_STAT 10500;
BA_ "GenSigTimeout_ETM" SG_ 464 PSG_ODS_STAT 10500;
BA_ "FlexKomSID" SG_ 464 PSG_ODS_STAT 426;
BA_ "FlexKomSigStartPos" SG_ 464 PSG_ODS_STAT 27;
BA_ "FlexKomSigLaenge" SG_ 464 PSG_ODS_STAT 2;
BA_ "FlexKomSigName" SG_ 464 PSG_ODS_STAT "PSG_ODS_STAT";
BA_ "FlexKomComment" SG_ 464 PSG_ODS_STAT "Passenger Occupant Detection Sensor Status";
BA_ "FlexKomIsMotorola" SG_ 464 PSG_ODS_STAT 1;
BA_ "GenSigSNA" SG_ 464 PSG_ODS_STAT "3h";
BA_ "GenSigSendType" SG_ 464 COD_Stat 5;
BA_ "GenSigCycleTime" SG_ 464 COD_Stat 1000;
BA_ "FlexKomSigStartValue" SG_ 464 COD_Stat "07h";
BA_ "GenSigStartValue" SG_ 464 COD_Stat 7;
BA_ "GenSigTimeout_IC" SG_ 464 COD_Stat 10500;
BA_ "GenSigTimeout_ETM" SG_ 464 COD_Stat 10500;
BA_ "FlexKomSID" SG_ 464 COD_Stat 333;
BA_ "FlexKomSigStartPos" SG_ 464 COD_Stat 42;
BA_ "FlexKomSigLaenge" SG_ 464 COD_Stat 3;
BA_ "FlexKomSigName" SG_ 464 COD_Stat "COD_Stat";
BA_ "FlexKomComment" SG_ 464 COD_Stat "Child seat detection state";
BA_ "FlexKomIsMotorola" SG_ 464 COD_Stat 1;
BA_ "GenSigSNA" SG_ 464 COD_Stat "7h";
BA_ "GenSigSendType" SG_ 464 SRS_DtlMsg01_Disp_Rq 5;
BA_ "GenSigCycleTime" SG_ 464 SRS_DtlMsg01_Disp_Rq 1000;
BA_ "FlexKomSigStartValue" SG_ 464 SRS_DtlMsg01_Disp_Rq "0000h";
BA_ "GenSigTimeout_IC" SG_ 464 SRS_DtlMsg01_Disp_Rq 10500;
BA_ "GenSigTimeout_ETM" SG_ 464 SRS_DtlMsg01_Disp_Rq 10500;
BA_ "FlexKomSID" SG_ 464 SRS_DtlMsg01_Disp_Rq 334;
BA_ "FlexKomSigStartPos" SG_ 464 SRS_DtlMsg01_Disp_Rq 55;
BA_ "FlexKomSigLaenge" SG_ 464 SRS_DtlMsg01_Disp_Rq 16;
BA_ "FlexKomSigName" SG_ 464 SRS_DtlMsg01_Disp_Rq "SRS_DtlMsg_Disp_Rq";
BA_ "FlexKomComment" SG_ 464 SRS_DtlMsg01_Disp_Rq "Reserved MCG (SRS detail message display request)";
BA_ "FlexKomIsMotorola" SG_ 464 SRS_DtlMsg01_Disp_Rq 1;
BA_ "GenSigSNA" SG_ 464 SRS_DtlMsg01_Disp_Rq "0h";
BA_ "GenSigSendType" SG_ 464 SRS_DtlMsg02_Disp_Rq 5;
BA_ "GenSigCycleTime" SG_ 464 SRS_DtlMsg02_Disp_Rq 1000;
BA_ "FlexKomSigStartValue" SG_ 464 SRS_DtlMsg02_Disp_Rq "0000h";
BA_ "GenSigTimeout_IC" SG_ 464 SRS_DtlMsg02_Disp_Rq 10500;
BA_ "GenSigTimeout_ETM" SG_ 464 SRS_DtlMsg02_Disp_Rq 10500;
BA_ "FlexKomSID" SG_ 464 SRS_DtlMsg02_Disp_Rq 334;
BA_ "FlexKomSigStartPos" SG_ 464 SRS_DtlMsg02_Disp_Rq 55;
BA_ "FlexKomSigLaenge" SG_ 464 SRS_DtlMsg02_Disp_Rq 16;
BA_ "FlexKomSigName" SG_ 464 SRS_DtlMsg02_Disp_Rq "SRS_DtlMsg_Disp_Rq";
BA_ "FlexKomComment" SG_ 464 SRS_DtlMsg02_Disp_Rq "Reserved MCG (SRS detail message display request)";
BA_ "FlexKomIsMotorola" SG_ 464 SRS_DtlMsg02_Disp_Rq 1;
BA_ "GenSigSNA" SG_ 464 SRS_DtlMsg02_Disp_Rq "0h";
BA_ "GenSigSendType" SG_ 464 SRS_DtlMsg03_Disp_Rq 5;
BA_ "GenSigCycleTime" SG_ 464 SRS_DtlMsg03_Disp_Rq 1000;
BA_ "FlexKomSigStartValue" SG_ 464 SRS_DtlMsg03_Disp_Rq "0000h";
BA_ "GenSigTimeout_IC" SG_ 464 SRS_DtlMsg03_Disp_Rq 10500;
BA_ "GenSigTimeout_ETM" SG_ 464 SRS_DtlMsg03_Disp_Rq 10500;
BA_ "FlexKomSID" SG_ 464 SRS_DtlMsg03_Disp_Rq 334;
BA_ "FlexKomSigStartPos" SG_ 464 SRS_DtlMsg03_Disp_Rq 55;
BA_ "FlexKomSigLaenge" SG_ 464 SRS_DtlMsg03_Disp_Rq 16;
BA_ "FlexKomSigName" SG_ 464 SRS_DtlMsg03_Disp_Rq "SRS_DtlMsg_Disp_Rq";
BA_ "FlexKomComment" SG_ 464 SRS_DtlMsg03_Disp_Rq "Reserved MCG (SRS detail message display request)";
BA_ "FlexKomIsMotorola" SG_ 464 SRS_DtlMsg03_Disp_Rq 1;
BA_ "GenSigSNA" SG_ 464 SRS_DtlMsg03_Disp_Rq "0h";
BA_ "GenSigSendType" SG_ 464 SRS_DtlMsg04_Disp_Rq 5;
BA_ "GenSigCycleTime" SG_ 464 SRS_DtlMsg04_Disp_Rq 1000;
BA_ "FlexKomSigStartValue" SG_ 464 SRS_DtlMsg04_Disp_Rq "0000h";
BA_ "GenSigTimeout_IC" SG_ 464 SRS_DtlMsg04_Disp_Rq 10500;
BA_ "GenSigTimeout_ETM" SG_ 464 SRS_DtlMsg04_Disp_Rq 10500;
BA_ "FlexKomSID" SG_ 464 SRS_DtlMsg04_Disp_Rq 334;
BA_ "FlexKomSigStartPos" SG_ 464 SRS_DtlMsg04_Disp_Rq 55;
BA_ "FlexKomSigLaenge" SG_ 464 SRS_DtlMsg04_Disp_Rq 16;
BA_ "FlexKomSigName" SG_ 464 SRS_DtlMsg04_Disp_Rq "SRS_DtlMsg_Disp_Rq";
BA_ "FlexKomComment" SG_ 464 SRS_DtlMsg04_Disp_Rq "Reserved MCG (SRS detail message display request)";
BA_ "FlexKomIsMotorola" SG_ 464 SRS_DtlMsg04_Disp_Rq 1;
BA_ "GenSigSNA" SG_ 464 SRS_DtlMsg04_Disp_Rq "0h";
BA_ "GenSigSendType" SG_ 464 SRS_DtlMsg05_Disp_Rq 5;
BA_ "GenSigCycleTime" SG_ 464 SRS_DtlMsg05_Disp_Rq 1000;
BA_ "FlexKomSigStartValue" SG_ 464 SRS_DtlMsg05_Disp_Rq "0000h";
BA_ "GenSigTimeout_IC" SG_ 464 SRS_DtlMsg05_Disp_Rq 10500;
BA_ "GenSigTimeout_ETM" SG_ 464 SRS_DtlMsg05_Disp_Rq 10500;
BA_ "FlexKomSID" SG_ 464 SRS_DtlMsg05_Disp_Rq 334;
BA_ "FlexKomSigStartPos" SG_ 464 SRS_DtlMsg05_Disp_Rq 55;
BA_ "FlexKomSigLaenge" SG_ 464 SRS_DtlMsg05_Disp_Rq 16;
BA_ "FlexKomSigName" SG_ 464 SRS_DtlMsg05_Disp_Rq "SRS_DtlMsg_Disp_Rq";
BA_ "FlexKomComment" SG_ 464 SRS_DtlMsg05_Disp_Rq "Reserved MCG (SRS detail message display request)";
BA_ "FlexKomIsMotorola" SG_ 464 SRS_DtlMsg05_Disp_Rq 1;
BA_ "GenSigSNA" SG_ 464 SRS_DtlMsg05_Disp_Rq "0h";
BA_ "GenSigSendType" SG_ 464 SRS_DtlMsg06_Disp_Rq 5;
BA_ "GenSigCycleTime" SG_ 464 SRS_DtlMsg06_Disp_Rq 1000;
BA_ "FlexKomSigStartValue" SG_ 464 SRS_DtlMsg06_Disp_Rq "0000h";
BA_ "GenSigTimeout_IC" SG_ 464 SRS_DtlMsg06_Disp_Rq 10500;
BA_ "GenSigTimeout_ETM" SG_ 464 SRS_DtlMsg06_Disp_Rq 10500;
BA_ "FlexKomSID" SG_ 464 SRS_DtlMsg06_Disp_Rq 334;
BA_ "FlexKomSigStartPos" SG_ 464 SRS_DtlMsg06_Disp_Rq 55;
BA_ "FlexKomSigLaenge" SG_ 464 SRS_DtlMsg06_Disp_Rq 16;
BA_ "FlexKomSigName" SG_ 464 SRS_DtlMsg06_Disp_Rq "SRS_DtlMsg_Disp_Rq";
BA_ "FlexKomComment" SG_ 464 SRS_DtlMsg06_Disp_Rq "Reserved MCG (SRS detail message display request)";
BA_ "FlexKomIsMotorola" SG_ 464 SRS_DtlMsg06_Disp_Rq 1;
BA_ "GenSigSNA" SG_ 464 SRS_DtlMsg06_Disp_Rq "0h";
BA_ "GenSigSendType" SG_ 464 SRS_DtlMsg07_Disp_Rq 5;
BA_ "GenSigCycleTime" SG_ 464 SRS_DtlMsg07_Disp_Rq 1000;
BA_ "FlexKomSigStartValue" SG_ 464 SRS_DtlMsg07_Disp_Rq "0000h";
BA_ "GenSigTimeout_IC" SG_ 464 SRS_DtlMsg07_Disp_Rq 10500;
BA_ "GenSigTimeout_ETM" SG_ 464 SRS_DtlMsg07_Disp_Rq 10500;
BA_ "FlexKomSID" SG_ 464 SRS_DtlMsg07_Disp_Rq 334;
BA_ "FlexKomSigStartPos" SG_ 464 SRS_DtlMsg07_Disp_Rq 55;
BA_ "FlexKomSigLaenge" SG_ 464 SRS_DtlMsg07_Disp_Rq 16;
BA_ "FlexKomSigName" SG_ 464 SRS_DtlMsg07_Disp_Rq "SRS_DtlMsg_Disp_Rq";
BA_ "FlexKomComment" SG_ 464 SRS_DtlMsg07_Disp_Rq "Reserved MCG (SRS detail message display request)";
BA_ "FlexKomIsMotorola" SG_ 464 SRS_DtlMsg07_Disp_Rq 1;
BA_ "GenSigSNA" SG_ 464 SRS_DtlMsg07_Disp_Rq "0h";
BA_ "GenSigSendType" SG_ 464 SRS_DtlMsg08_Disp_Rq 5;
BA_ "GenSigCycleTime" SG_ 464 SRS_DtlMsg08_Disp_Rq 1000;
BA_ "FlexKomSigStartValue" SG_ 464 SRS_DtlMsg08_Disp_Rq "0000h";
BA_ "GenSigTimeout_IC" SG_ 464 SRS_DtlMsg08_Disp_Rq 10500;
BA_ "GenSigTimeout_ETM" SG_ 464 SRS_DtlMsg08_Disp_Rq 10500;
BA_ "FlexKomSID" SG_ 464 SRS_DtlMsg08_Disp_Rq 334;
BA_ "FlexKomSigStartPos" SG_ 464 SRS_DtlMsg08_Disp_Rq 55;
BA_ "FlexKomSigLaenge" SG_ 464 SRS_DtlMsg08_Disp_Rq 16;
BA_ "FlexKomSigName" SG_ 464 SRS_DtlMsg08_Disp_Rq "SRS_DtlMsg_Disp_Rq";
BA_ "FlexKomComment" SG_ 464 SRS_DtlMsg08_Disp_Rq "Reserved MCG (SRS detail message display request)";
BA_ "FlexKomIsMotorola" SG_ 464 SRS_DtlMsg08_Disp_Rq 1;
BA_ "GenSigSNA" SG_ 464 SRS_DtlMsg08_Disp_Rq "0h";
BA_ "GenSigSendType" SG_ 464 SRS_DtlMsg09_Disp_Rq 5;
BA_ "GenSigCycleTime" SG_ 464 SRS_DtlMsg09_Disp_Rq 1000;
BA_ "FlexKomSigStartValue" SG_ 464 SRS_DtlMsg09_Disp_Rq "0000h";
BA_ "GenSigTimeout_IC" SG_ 464 SRS_DtlMsg09_Disp_Rq 10500;
BA_ "GenSigTimeout_ETM" SG_ 464 SRS_DtlMsg09_Disp_Rq 10500;
BA_ "FlexKomSID" SG_ 464 SRS_DtlMsg09_Disp_Rq 334;
BA_ "FlexKomSigStartPos" SG_ 464 SRS_DtlMsg09_Disp_Rq 55;
BA_ "FlexKomSigLaenge" SG_ 464 SRS_DtlMsg09_Disp_Rq 16;
BA_ "FlexKomSigName" SG_ 464 SRS_DtlMsg09_Disp_Rq "SRS_DtlMsg_Disp_Rq";
BA_ "FlexKomComment" SG_ 464 SRS_DtlMsg09_Disp_Rq "Reserved MCG (SRS detail message display request)";
BA_ "FlexKomIsMotorola" SG_ 464 SRS_DtlMsg09_Disp_Rq 1;
BA_ "GenSigSNA" SG_ 464 SRS_DtlMsg09_Disp_Rq "0h";
BA_ "GenSigSendType" SG_ 464 SRS_DtlMsg10_Disp_Rq 5;
BA_ "GenSigCycleTime" SG_ 464 SRS_DtlMsg10_Disp_Rq 1000;
BA_ "FlexKomSigStartValue" SG_ 464 SRS_DtlMsg10_Disp_Rq "0000h";
BA_ "GenSigTimeout_IC" SG_ 464 SRS_DtlMsg10_Disp_Rq 10500;
BA_ "GenSigTimeout_ETM" SG_ 464 SRS_DtlMsg10_Disp_Rq 10500;
BA_ "FlexKomSID" SG_ 464 SRS_DtlMsg10_Disp_Rq 334;
BA_ "FlexKomSigStartPos" SG_ 464 SRS_DtlMsg10_Disp_Rq 55;
BA_ "FlexKomSigLaenge" SG_ 464 SRS_DtlMsg10_Disp_Rq 16;
BA_ "FlexKomSigName" SG_ 464 SRS_DtlMsg10_Disp_Rq "SRS_DtlMsg_Disp_Rq";
BA_ "FlexKomComment" SG_ 464 SRS_DtlMsg10_Disp_Rq "Reserved MCG (SRS detail message display request)";
BA_ "FlexKomIsMotorola" SG_ 464 SRS_DtlMsg10_Disp_Rq 1;
BA_ "GenSigSNA" SG_ 464 SRS_DtlMsg10_Disp_Rq "0h";
BA_ "GenSigSendType" SG_ 464 SRS_DtlMsg11_Disp_Rq 5;
BA_ "GenSigCycleTime" SG_ 464 SRS_DtlMsg11_Disp_Rq 1000;
BA_ "FlexKomSigStartValue" SG_ 464 SRS_DtlMsg11_Disp_Rq "0000h";
BA_ "GenSigTimeout_IC" SG_ 464 SRS_DtlMsg11_Disp_Rq 10500;
BA_ "GenSigTimeout_ETM" SG_ 464 SRS_DtlMsg11_Disp_Rq 10500;
BA_ "FlexKomSID" SG_ 464 SRS_DtlMsg11_Disp_Rq 334;
BA_ "FlexKomSigStartPos" SG_ 464 SRS_DtlMsg11_Disp_Rq 55;
BA_ "FlexKomSigLaenge" SG_ 464 SRS_DtlMsg11_Disp_Rq 16;
BA_ "FlexKomSigName" SG_ 464 SRS_DtlMsg11_Disp_Rq "SRS_DtlMsg_Disp_Rq";
BA_ "FlexKomComment" SG_ 464 SRS_DtlMsg11_Disp_Rq "Reserved MCG (SRS detail message display request)";
BA_ "FlexKomIsMotorola" SG_ 464 SRS_DtlMsg11_Disp_Rq 1;
BA_ "GenSigSNA" SG_ 464 SRS_DtlMsg11_Disp_Rq "0h";
BA_ "GenSigSendType" SG_ 464 SRS_DtlMsg12_Disp_Rq 5;
BA_ "GenSigCycleTime" SG_ 464 SRS_DtlMsg12_Disp_Rq 1000;
BA_ "FlexKomSigStartValue" SG_ 464 SRS_DtlMsg12_Disp_Rq "0000h";
BA_ "GenSigTimeout_IC" SG_ 464 SRS_DtlMsg12_Disp_Rq 10500;
BA_ "GenSigTimeout_ETM" SG_ 464 SRS_DtlMsg12_Disp_Rq 10500;
BA_ "FlexKomSID" SG_ 464 SRS_DtlMsg12_Disp_Rq 334;
BA_ "FlexKomSigStartPos" SG_ 464 SRS_DtlMsg12_Disp_Rq 55;
BA_ "FlexKomSigLaenge" SG_ 464 SRS_DtlMsg12_Disp_Rq 16;
BA_ "FlexKomSigName" SG_ 464 SRS_DtlMsg12_Disp_Rq "SRS_DtlMsg_Disp_Rq";
BA_ "FlexKomComment" SG_ 464 SRS_DtlMsg12_Disp_Rq "Reserved MCG (SRS detail message display request)";
BA_ "FlexKomIsMotorola" SG_ 464 SRS_DtlMsg12_Disp_Rq 1;
BA_ "GenSigSNA" SG_ 464 SRS_DtlMsg12_Disp_Rq "0h";
BA_ "GenSigSendType" SG_ 464 SRS_DtlMsg13_Disp_Rq 5;
BA_ "GenSigCycleTime" SG_ 464 SRS_DtlMsg13_Disp_Rq 1000;
BA_ "FlexKomSigStartValue" SG_ 464 SRS_DtlMsg13_Disp_Rq "0000h";
BA_ "GenSigTimeout_IC" SG_ 464 SRS_DtlMsg13_Disp_Rq 10500;
BA_ "GenSigTimeout_ETM" SG_ 464 SRS_DtlMsg13_Disp_Rq 10500;
BA_ "FlexKomSID" SG_ 464 SRS_DtlMsg13_Disp_Rq 334;
BA_ "FlexKomSigStartPos" SG_ 464 SRS_DtlMsg13_Disp_Rq 55;
BA_ "FlexKomSigLaenge" SG_ 464 SRS_DtlMsg13_Disp_Rq 16;
BA_ "FlexKomSigName" SG_ 464 SRS_DtlMsg13_Disp_Rq "SRS_DtlMsg_Disp_Rq";
BA_ "FlexKomComment" SG_ 464 SRS_DtlMsg13_Disp_Rq "Reserved MCG (SRS detail message display request)";
BA_ "FlexKomIsMotorola" SG_ 464 SRS_DtlMsg13_Disp_Rq 1;
BA_ "GenSigSNA" SG_ 464 SRS_DtlMsg13_Disp_Rq "0h";
BA_ "GenSigSendType" SG_ 464 SRS_DtlMsg14_Disp_Rq 5;
BA_ "GenSigCycleTime" SG_ 464 SRS_DtlMsg14_Disp_Rq 1000;
BA_ "FlexKomSigStartValue" SG_ 464 SRS_DtlMsg14_Disp_Rq "0000h";
BA_ "GenSigTimeout_IC" SG_ 464 SRS_DtlMsg14_Disp_Rq 10500;
BA_ "GenSigTimeout_ETM" SG_ 464 SRS_DtlMsg14_Disp_Rq 10500;
BA_ "FlexKomSID" SG_ 464 SRS_DtlMsg14_Disp_Rq 334;
BA_ "FlexKomSigStartPos" SG_ 464 SRS_DtlMsg14_Disp_Rq 55;
BA_ "FlexKomSigLaenge" SG_ 464 SRS_DtlMsg14_Disp_Rq 16;
BA_ "FlexKomSigName" SG_ 464 SRS_DtlMsg14_Disp_Rq "SRS_DtlMsg_Disp_Rq";
BA_ "FlexKomComment" SG_ 464 SRS_DtlMsg14_Disp_Rq "Reserved MCG (SRS detail message display request)";
BA_ "FlexKomIsMotorola" SG_ 464 SRS_DtlMsg14_Disp_Rq 1;
BA_ "GenSigSNA" SG_ 464 SRS_DtlMsg14_Disp_Rq "0h";
BA_ "GenSigSendType" SG_ 464 SRS_DtlMsg15_Disp_Rq 5;
BA_ "GenSigCycleTime" SG_ 464 SRS_DtlMsg15_Disp_Rq 1000;
BA_ "FlexKomSigStartValue" SG_ 464 SRS_DtlMsg15_Disp_Rq "0000h";
BA_ "GenSigTimeout_IC" SG_ 464 SRS_DtlMsg15_Disp_Rq 10500;
BA_ "GenSigTimeout_ETM" SG_ 464 SRS_DtlMsg15_Disp_Rq 10500;
BA_ "FlexKomSID" SG_ 464 SRS_DtlMsg15_Disp_Rq 334;
BA_ "FlexKomSigStartPos" SG_ 464 SRS_DtlMsg15_Disp_Rq 55;
BA_ "FlexKomSigLaenge" SG_ 464 SRS_DtlMsg15_Disp_Rq 16;
BA_ "FlexKomSigName" SG_ 464 SRS_DtlMsg15_Disp_Rq "SRS_DtlMsg_Disp_Rq";
BA_ "FlexKomComment" SG_ 464 SRS_DtlMsg15_Disp_Rq "Reserved MCG (SRS detail message display request)";
BA_ "FlexKomIsMotorola" SG_ 464 SRS_DtlMsg15_Disp_Rq 1;
BA_ "GenSigSNA" SG_ 464 SRS_DtlMsg15_Disp_Rq "0h";
BA_ "GenSigSendType" SG_ 464 SRS_DtlMsg16_Disp_Rq 5;
BA_ "GenSigCycleTime" SG_ 464 SRS_DtlMsg16_Disp_Rq 1000;
BA_ "FlexKomSigStartValue" SG_ 464 SRS_DtlMsg16_Disp_Rq "0000h";
BA_ "GenSigTimeout_IC" SG_ 464 SRS_DtlMsg16_Disp_Rq 10500;
BA_ "GenSigTimeout_ETM" SG_ 464 SRS_DtlMsg16_Disp_Rq 10500;
BA_ "FlexKomSID" SG_ 464 SRS_DtlMsg16_Disp_Rq 334;
BA_ "FlexKomSigStartPos" SG_ 464 SRS_DtlMsg16_Disp_Rq 55;
BA_ "FlexKomSigLaenge" SG_ 464 SRS_DtlMsg16_Disp_Rq 16;
BA_ "FlexKomSigName" SG_ 464 SRS_DtlMsg16_Disp_Rq "SRS_DtlMsg_Disp_Rq";
BA_ "FlexKomComment" SG_ 464 SRS_DtlMsg16_Disp_Rq "Reserved MCG (SRS detail message display request)";
BA_ "FlexKomIsMotorola" SG_ 464 SRS_DtlMsg16_Disp_Rq 1;
BA_ "GenSigSNA" SG_ 464 SRS_DtlMsg16_Disp_Rq "0h";
BA_ "GenSigSendType" SG_ 466 IMPACT_A 2;
BA_ "GenSigCycleTimeActive" SG_ 466 IMPACT_A 20;
BA_ "FlexKomSigStartValue" SG_ 466 IMPACT_A "0000h";
BA_ "FlexKomSID" SG_ 466 IMPACT_A 325;
BA_ "FlexKomSigStartPos" SG_ 466 IMPACT_A 7;
BA_ "FlexKomSigLaenge" SG_ 466 IMPACT_A 16;
BA_ "FlexKomSigName" SG_ 466 IMPACT_A "IMPACT";
BA_ "FlexKomComment" SG_ 466 IMPACT_A "Impact events";
BA_ "FlexKomIsMotorola" SG_ 466 IMPACT_A 1;
BA_ "GenSigSNA" SG_ 466 IMPACT_A "0h";
BA_ "GenSigSendType" SG_ 466 IMPACT_B 2;
BA_ "GenSigCycleTimeActive" SG_ 466 IMPACT_B 20;
BA_ "FlexKomSigStartValue" SG_ 466 IMPACT_B "0000h";
BA_ "FlexKomSID" SG_ 466 IMPACT_B 325;
BA_ "FlexKomSigStartPos" SG_ 466 IMPACT_B 7;
BA_ "FlexKomSigLaenge" SG_ 466 IMPACT_B 16;
BA_ "FlexKomSigName" SG_ 466 IMPACT_B "IMPACT";
BA_ "FlexKomComment" SG_ 466 IMPACT_B "Impact events";
BA_ "FlexKomIsMotorola" SG_ 466 IMPACT_B 1;
BA_ "GenSigSNA" SG_ 466 IMPACT_B "0h";
BA_ "GenSigSendType" SG_ 466 IMPACT_C 2;
BA_ "GenSigCycleTimeActive" SG_ 466 IMPACT_C 20;
BA_ "FlexKomSigStartValue" SG_ 466 IMPACT_C "0000h";
BA_ "FlexKomSID" SG_ 466 IMPACT_C 325;
BA_ "FlexKomSigStartPos" SG_ 466 IMPACT_C 7;
BA_ "FlexKomSigLaenge" SG_ 466 IMPACT_C 16;
BA_ "FlexKomSigName" SG_ 466 IMPACT_C "IMPACT";
BA_ "FlexKomComment" SG_ 466 IMPACT_C "Impact events";
BA_ "FlexKomIsMotorola" SG_ 466 IMPACT_C 1;
BA_ "GenSigSNA" SG_ 466 IMPACT_C "0h";
BA_ "GenSigSendType" SG_ 466 IMPACT_D 2;
BA_ "GenSigCycleTimeActive" SG_ 466 IMPACT_D 20;
BA_ "FlexKomSigStartValue" SG_ 466 IMPACT_D "0000h";
BA_ "FlexKomSID" SG_ 466 IMPACT_D 325;
BA_ "FlexKomSigStartPos" SG_ 466 IMPACT_D 7;
BA_ "FlexKomSigLaenge" SG_ 466 IMPACT_D 16;
BA_ "FlexKomSigName" SG_ 466 IMPACT_D "IMPACT";
BA_ "FlexKomComment" SG_ 466 IMPACT_D "Impact events";
BA_ "FlexKomIsMotorola" SG_ 466 IMPACT_D 1;
BA_ "GenSigSNA" SG_ 466 IMPACT_D "0h";
BA_ "GenSigSendType" SG_ 466 IMPACT_E 2;
BA_ "GenSigCycleTimeActive" SG_ 466 IMPACT_E 20;
BA_ "FlexKomSigStartValue" SG_ 466 IMPACT_E "0000h";
BA_ "FlexKomSID" SG_ 466 IMPACT_E 325;
BA_ "FlexKomSigStartPos" SG_ 466 IMPACT_E 7;
BA_ "FlexKomSigLaenge" SG_ 466 IMPACT_E 16;
BA_ "FlexKomSigName" SG_ 466 IMPACT_E "IMPACT";
BA_ "FlexKomComment" SG_ 466 IMPACT_E "Impact events";
BA_ "FlexKomIsMotorola" SG_ 466 IMPACT_E 1;
BA_ "GenSigSNA" SG_ 466 IMPACT_E "0h";
BA_ "GenSigSendType" SG_ 466 Impact_F 2;
BA_ "GenSigCycleTimeActive" SG_ 466 Impact_F 20;
BA_ "FlexKomSigStartValue" SG_ 466 Impact_F "0000h";
BA_ "FlexKomSID" SG_ 466 Impact_F 325;
BA_ "FlexKomSigStartPos" SG_ 466 Impact_F 7;
BA_ "FlexKomSigLaenge" SG_ 466 Impact_F 16;
BA_ "FlexKomSigName" SG_ 466 Impact_F "IMPACT";
BA_ "FlexKomComment" SG_ 466 Impact_F "Impact events";
BA_ "FlexKomIsMotorola" SG_ 466 Impact_F 1;
BA_ "GenSigSNA" SG_ 466 Impact_F "0h";
BA_ "GenSigSendType" SG_ 466 Impact_G 2;
BA_ "GenSigCycleTimeActive" SG_ 466 Impact_G 20;
BA_ "FlexKomSigStartValue" SG_ 466 Impact_G "0000h";
BA_ "FlexKomSID" SG_ 466 Impact_G 325;
BA_ "FlexKomSigStartPos" SG_ 466 Impact_G 7;
BA_ "FlexKomSigLaenge" SG_ 466 Impact_G 16;
BA_ "FlexKomSigName" SG_ 466 Impact_G "IMPACT";
BA_ "FlexKomComment" SG_ 466 Impact_G "Impact events";
BA_ "FlexKomIsMotorola" SG_ 466 Impact_G 1;
BA_ "GenSigSNA" SG_ 466 Impact_G "0h";
BA_ "GenSigSendType" SG_ 466 Impact_Tgl 2;
BA_ "GenSigCycleTimeActive" SG_ 466 Impact_Tgl 20;
BA_ "FlexKomSigStartValue" SG_ 466 Impact_Tgl "0000h";
BA_ "FlexKomSID" SG_ 466 Impact_Tgl 325;
BA_ "FlexKomSigStartPos" SG_ 466 Impact_Tgl 7;
BA_ "FlexKomSigLaenge" SG_ 466 Impact_Tgl 16;
BA_ "FlexKomSigName" SG_ 466 Impact_Tgl "IMPACT";
BA_ "FlexKomComment" SG_ 466 Impact_Tgl "Impact events";
BA_ "FlexKomIsMotorola" SG_ 466 Impact_Tgl 1;
BA_ "GenSigSNA" SG_ 466 Impact_Tgl "0h";
BA_ "GenSigSendType" SG_ 466 IMPACT_H 2;
BA_ "GenSigCycleTimeActive" SG_ 466 IMPACT_H 20;
BA_ "FlexKomSigStartValue" SG_ 466 IMPACT_H "0000h";
BA_ "FlexKomSID" SG_ 466 IMPACT_H 325;
BA_ "FlexKomSigStartPos" SG_ 466 IMPACT_H 7;
BA_ "FlexKomSigLaenge" SG_ 466 IMPACT_H 16;
BA_ "FlexKomSigName" SG_ 466 IMPACT_H "IMPACT";
BA_ "FlexKomComment" SG_ 466 IMPACT_H "Impact events";
BA_ "FlexKomIsMotorola" SG_ 466 IMPACT_H 1;
BA_ "GenSigSNA" SG_ 466 IMPACT_H "0h";
BA_ "GenSigSendType" SG_ 466 IMPACT_I 2;
BA_ "GenSigCycleTimeActive" SG_ 466 IMPACT_I 20;
BA_ "FlexKomSigStartValue" SG_ 466 IMPACT_I "0000h";
BA_ "FlexKomSID" SG_ 466 IMPACT_I 325;
BA_ "FlexKomSigStartPos" SG_ 466 IMPACT_I 7;
BA_ "FlexKomSigLaenge" SG_ 466 IMPACT_I 16;
BA_ "FlexKomSigName" SG_ 466 IMPACT_I "IMPACT";
BA_ "FlexKomComment" SG_ 466 IMPACT_I "Impact events";
BA_ "FlexKomIsMotorola" SG_ 466 IMPACT_I 1;
BA_ "GenSigSNA" SG_ 466 IMPACT_I "0h";
BA_ "GenSigSendType" SG_ 466 IMPACT_K 2;
BA_ "GenSigCycleTimeActive" SG_ 466 IMPACT_K 20;
BA_ "FlexKomSigStartValue" SG_ 466 IMPACT_K "0000h";
BA_ "FlexKomSID" SG_ 466 IMPACT_K 325;
BA_ "FlexKomSigStartPos" SG_ 466 IMPACT_K 7;
BA_ "FlexKomSigLaenge" SG_ 466 IMPACT_K 16;
BA_ "FlexKomSigName" SG_ 466 IMPACT_K "IMPACT";
BA_ "FlexKomComment" SG_ 466 IMPACT_K "Impact events";
BA_ "FlexKomIsMotorola" SG_ 466 IMPACT_K 1;
BA_ "GenSigSNA" SG_ 466 IMPACT_K "0h";
BA_ "GenSigSendType" SG_ 466 IMPACT_L 2;
BA_ "GenSigCycleTimeActive" SG_ 466 IMPACT_L 20;
BA_ "FlexKomSigStartValue" SG_ 466 IMPACT_L "0000h";
BA_ "FlexKomSID" SG_ 466 IMPACT_L 325;
BA_ "FlexKomSigStartPos" SG_ 466 IMPACT_L 7;
BA_ "FlexKomSigLaenge" SG_ 466 IMPACT_L 16;
BA_ "FlexKomSigName" SG_ 466 IMPACT_L "IMPACT";
BA_ "FlexKomComment" SG_ 466 IMPACT_L "Impact events";
BA_ "FlexKomIsMotorola" SG_ 466 IMPACT_L 1;
BA_ "GenSigSNA" SG_ 466 IMPACT_L "0h";
BA_ "GenSigSendType" SG_ 466 IMPACT_M 2;
BA_ "GenSigCycleTimeActive" SG_ 466 IMPACT_M 20;
BA_ "FlexKomSigStartValue" SG_ 466 IMPACT_M "0000h";
BA_ "FlexKomSID" SG_ 466 IMPACT_M 325;
BA_ "FlexKomSigStartPos" SG_ 466 IMPACT_M 7;
BA_ "FlexKomSigLaenge" SG_ 466 IMPACT_M 16;
BA_ "FlexKomSigName" SG_ 466 IMPACT_M "IMPACT";
BA_ "FlexKomComment" SG_ 466 IMPACT_M "Impact events";
BA_ "FlexKomIsMotorola" SG_ 466 IMPACT_M 1;
BA_ "GenSigSNA" SG_ 466 IMPACT_M "0h";
BA_ "GenSigSendType" SG_ 466 IMPACT_N 2;
BA_ "GenSigCycleTimeActive" SG_ 466 IMPACT_N 20;
BA_ "FlexKomSigStartValue" SG_ 466 IMPACT_N "0000h";
BA_ "FlexKomSID" SG_ 466 IMPACT_N 325;
BA_ "FlexKomSigStartPos" SG_ 466 IMPACT_N 7;
BA_ "FlexKomSigLaenge" SG_ 466 IMPACT_N 16;
BA_ "FlexKomSigName" SG_ 466 IMPACT_N "IMPACT";
BA_ "FlexKomComment" SG_ 466 IMPACT_N "Impact events";
BA_ "FlexKomIsMotorola" SG_ 466 IMPACT_N 1;
BA_ "GenSigSNA" SG_ 466 IMPACT_N "0h";
BA_ "GenSigSendType" SG_ 466 IMPACT_O 2;
BA_ "GenSigCycleTimeActive" SG_ 466 IMPACT_O 20;
BA_ "FlexKomSigStartValue" SG_ 466 IMPACT_O "0000h";
BA_ "FlexKomSID" SG_ 466 IMPACT_O 325;
BA_ "FlexKomSigStartPos" SG_ 466 IMPACT_O 7;
BA_ "FlexKomSigLaenge" SG_ 466 IMPACT_O 16;
BA_ "FlexKomSigName" SG_ 466 IMPACT_O "IMPACT";
BA_ "FlexKomComment" SG_ 466 IMPACT_O "Impact events";
BA_ "FlexKomIsMotorola" SG_ 466 IMPACT_O 1;
BA_ "GenSigSNA" SG_ 466 IMPACT_O "0h";
BA_ "GenSigSendType" SG_ 466 IMPACT_X 2;
BA_ "GenSigCycleTimeActive" SG_ 466 IMPACT_X 20;
BA_ "FlexKomSigStartValue" SG_ 466 IMPACT_X "0000h";
BA_ "FlexKomSID" SG_ 466 IMPACT_X 325;
BA_ "FlexKomSigStartPos" SG_ 466 IMPACT_X 7;
BA_ "FlexKomSigLaenge" SG_ 466 IMPACT_X 16;
BA_ "FlexKomSigName" SG_ 466 IMPACT_X "IMPACT";
BA_ "FlexKomComment" SG_ 466 IMPACT_X "Impact events";
BA_ "FlexKomIsMotorola" SG_ 466 IMPACT_X 1;
BA_ "GenSigSNA" SG_ 466 IMPACT_X "0h";
BA_ "GenSigCycleTime" SG_ 468 NormCruiseMode 60;
BA_ "FlexKomSigStartValue" SG_ 468 NormCruiseMode "0002FFFF00FF00FFh";
BA_ "GenSigTimeout_IC" SG_ 468 NormCruiseMode 630;
BA_ "GenSigTimeout_ORC" SG_ 468 NormCruiseMode 210;
BA_ "FlexKomSID" SG_ 468 NormCruiseMode 403;
BA_ "FlexKomSigStartPos" SG_ 468 NormCruiseMode 7;
BA_ "FlexKomSigLaenge" SG_ 468 NormCruiseMode 64;
BA_ "FlexKomSigName" SG_ 468 NormCruiseMode "DAS_A2_PKT";
BA_ "FlexKomComment" SG_ 468 NormCruiseMode "DAS_A2 Packet";
BA_ "FlexKomIsMotorola" SG_ 468 NormCruiseMode 1;
BA_ "GenSigSNA" SG_ 468 NormCruiseMode "0h";
BA_ "GenSigCycleTime" SG_ 468 FCW_Sensitivity 60;
BA_ "FlexKomSigStartValue" SG_ 468 FCW_Sensitivity "0002FFFF00FF00FFh";
BA_ "GenSigTimeout_IC" SG_ 468 FCW_Sensitivity 630;
BA_ "GenSigTimeout_ORC" SG_ 468 FCW_Sensitivity 210;
BA_ "FlexKomSID" SG_ 468 FCW_Sensitivity 403;
BA_ "FlexKomSigStartPos" SG_ 468 FCW_Sensitivity 7;
BA_ "FlexKomSigLaenge" SG_ 468 FCW_Sensitivity 64;
BA_ "FlexKomSigName" SG_ 468 FCW_Sensitivity "DAS_A2_PKT";
BA_ "FlexKomComment" SG_ 468 FCW_Sensitivity "DAS_A2 Packet";
BA_ "FlexKomIsMotorola" SG_ 468 FCW_Sensitivity 1;
BA_ "GenSigSNA" SG_ 468 FCW_Sensitivity "0h";
BA_ "GenSigCycleTime" SG_ 468 As_Disp_Rq 60;
BA_ "FlexKomSigStartValue" SG_ 468 As_Disp_Rq "0002FFFF00FF00FFh";
BA_ "GenSigTimeout_IC" SG_ 468 As_Disp_Rq 630;
BA_ "GenSigTimeout_ORC" SG_ 468 As_Disp_Rq 210;
BA_ "FlexKomSID" SG_ 468 As_Disp_Rq 403;
BA_ "FlexKomSigStartPos" SG_ 468 As_Disp_Rq 7;
BA_ "FlexKomSigLaenge" SG_ 468 As_Disp_Rq 64;
BA_ "FlexKomSigName" SG_ 468 As_Disp_Rq "DAS_A2_PKT";
BA_ "FlexKomComment" SG_ 468 As_Disp_Rq "DAS_A2 Packet";
BA_ "FlexKomIsMotorola" SG_ 468 As_Disp_Rq 1;
BA_ "GenSigSNA" SG_ 468 As_Disp_Rq "3h";
BA_ "GenSigCycleTime" SG_ 468 ObjIntrst_Dtct 60;
BA_ "FlexKomSigStartValue" SG_ 468 ObjIntrst_Dtct "0002FFFF00FF00FFh";
BA_ "GenSigTimeout_IC" SG_ 468 ObjIntrst_Dtct 630;
BA_ "GenSigTimeout_ORC" SG_ 468 ObjIntrst_Dtct 210;
BA_ "FlexKomSID" SG_ 468 ObjIntrst_Dtct 403;
BA_ "FlexKomSigStartPos" SG_ 468 ObjIntrst_Dtct 7;
BA_ "FlexKomSigLaenge" SG_ 468 ObjIntrst_Dtct 64;
BA_ "FlexKomSigName" SG_ 468 ObjIntrst_Dtct "DAS_A2_PKT";
BA_ "FlexKomComment" SG_ 468 ObjIntrst_Dtct "DAS_A2 Packet";
BA_ "FlexKomIsMotorola" SG_ 468 ObjIntrst_Dtct 1;
BA_ "GenSigSNA" SG_ 468 ObjIntrst_Dtct "0h";
BA_ "GenSigCycleTime" SG_ 468 DTR_Dspl_TmGap 60;
BA_ "FlexKomSigStartValue" SG_ 468 DTR_Dspl_TmGap "0002FFFF00FF00FFh";
BA_ "GenSigStartValue" SG_ 468 DTR_Dspl_TmGap 2;
BA_ "GenSigTimeout_IC" SG_ 468 DTR_Dspl_TmGap 630;
BA_ "GenSigTimeout_ORC" SG_ 468 DTR_Dspl_TmGap 210;
BA_ "FlexKomSID" SG_ 468 DTR_Dspl_TmGap 403;
BA_ "FlexKomSigStartPos" SG_ 468 DTR_Dspl_TmGap 7;
BA_ "FlexKomSigLaenge" SG_ 468 DTR_Dspl_TmGap 64;
BA_ "FlexKomSigName" SG_ 468 DTR_Dspl_TmGap "DAS_A2_PKT";
BA_ "FlexKomComment" SG_ 468 DTR_Dspl_TmGap "DAS_A2 Packet";
BA_ "FlexKomIsMotorola" SG_ 468 DTR_Dspl_TmGap 1;
BA_ "GenSigSNA" SG_ 468 DTR_Dspl_TmGap "3h";
BA_ "GenSigCycleTime" SG_ 468 DTR_Ovr_D 60;
BA_ "FlexKomSigStartValue" SG_ 468 DTR_Ovr_D "0002FFFF00FF00FFh";
BA_ "GenSigTimeout_IC" SG_ 468 DTR_Ovr_D 630;
BA_ "GenSigTimeout_ORC" SG_ 468 DTR_Ovr_D 210;
BA_ "FlexKomSID" SG_ 468 DTR_Ovr_D 403;
BA_ "FlexKomSigStartPos" SG_ 468 DTR_Ovr_D 7;
BA_ "FlexKomSigLaenge" SG_ 468 DTR_Ovr_D 64;
BA_ "FlexKomSigName" SG_ 468 DTR_Ovr_D "DAS_A2_PKT";
BA_ "FlexKomComment" SG_ 468 DTR_Ovr_D "DAS_A2 Packet";
BA_ "FlexKomIsMotorola" SG_ 468 DTR_Ovr_D 1;
BA_ "GenSigSNA" SG_ 468 DTR_Ovr_D "0h";
BA_ "GenSigCycleTime" SG_ 468 DTR_Disp_On_Rq 60;
BA_ "FlexKomSigStartValue" SG_ 468 DTR_Disp_On_Rq "0002FFFF00FF00FFh";
BA_ "GenSigTimeout_IC" SG_ 468 DTR_Disp_On_Rq 630;
BA_ "GenSigTimeout_ORC" SG_ 468 DTR_Disp_On_Rq 210;
BA_ "FlexKomSID" SG_ 468 DTR_Disp_On_Rq 403;
BA_ "FlexKomSigStartPos" SG_ 468 DTR_Disp_On_Rq 7;
BA_ "FlexKomSigLaenge" SG_ 468 DTR_Disp_On_Rq 64;
BA_ "FlexKomSigName" SG_ 468 DTR_Disp_On_Rq "DAS_A2_PKT";
BA_ "FlexKomComment" SG_ 468 DTR_Disp_On_Rq "DAS_A2 Packet";
BA_ "FlexKomIsMotorola" SG_ 468 DTR_Disp_On_Rq 1;
BA_ "GenSigSNA" SG_ 468 DTR_Disp_On_Rq "0h";
BA_ "GenSigCycleTime" SG_ 468 DTR_CC_Enbl 60;
BA_ "FlexKomSigStartValue" SG_ 468 DTR_CC_Enbl "0002FFFF00FF00FFh";
BA_ "GenSigTimeout_IC" SG_ 468 DTR_CC_Enbl 630;
BA_ "GenSigTimeout_ORC" SG_ 468 DTR_CC_Enbl 210;
BA_ "FlexKomSID" SG_ 468 DTR_CC_Enbl 403;
BA_ "FlexKomSigStartPos" SG_ 468 DTR_CC_Enbl 7;
BA_ "FlexKomSigLaenge" SG_ 468 DTR_CC_Enbl 64;
BA_ "FlexKomSigName" SG_ 468 DTR_CC_Enbl "DAS_A2_PKT";
BA_ "FlexKomComment" SG_ 468 DTR_CC_Enbl "DAS_A2 Packet";
BA_ "FlexKomIsMotorola" SG_ 468 DTR_CC_Enbl 1;
BA_ "GenSigSNA" SG_ 468 DTR_CC_Enbl "0h";
BA_ "GenSigCycleTime" SG_ 468 DTR_Engd 60;
BA_ "FlexKomSigStartValue" SG_ 468 DTR_Engd "0002FFFF00FF00FFh";
BA_ "GenSigTimeout_IC" SG_ 468 DTR_Engd 630;
BA_ "GenSigTimeout_ORC" SG_ 468 DTR_Engd 210;
BA_ "FlexKomSID" SG_ 468 DTR_Engd 403;
BA_ "FlexKomSigStartPos" SG_ 468 DTR_Engd 7;
BA_ "FlexKomSigLaenge" SG_ 468 DTR_Engd 64;
BA_ "FlexKomSigName" SG_ 468 DTR_Engd "DAS_A2_PKT";
BA_ "FlexKomComment" SG_ 468 DTR_Engd "DAS_A2 Packet";
BA_ "FlexKomIsMotorola" SG_ 468 DTR_Engd 1;
BA_ "GenSigSNA" SG_ 468 DTR_Engd "0h";
BA_ "GenSigCycleTime" SG_ 468 Dist_D_Dsr 60;
BA_ "FlexKomSigStartValue" SG_ 468 Dist_D_Dsr "0002FFFF00FF00FFh";
BA_ "GenSigStartValue" SG_ 468 Dist_D_Dsr 255;
BA_ "GenSigTimeout_IC" SG_ 468 Dist_D_Dsr 630;
BA_ "GenSigTimeout_ORC" SG_ 468 Dist_D_Dsr 210;
BA_ "FlexKomSID" SG_ 468 Dist_D_Dsr 403;
BA_ "FlexKomSigStartPos" SG_ 468 Dist_D_Dsr 7;
BA_ "FlexKomSigLaenge" SG_ 468 Dist_D_Dsr 64;
BA_ "FlexKomSigName" SG_ 468 Dist_D_Dsr "DAS_A2_PKT";
BA_ "FlexKomComment" SG_ 468 Dist_D_Dsr "DAS_A2 Packet";
BA_ "FlexKomIsMotorola" SG_ 468 Dist_D_Dsr 1;
BA_ "GenSigSNA" SG_ 468 Dist_D_Dsr "FFh";
BA_ "GenSigCycleTime" SG_ 468 ObjIntrst_Dist 60;
BA_ "FlexKomSigStartValue" SG_ 468 ObjIntrst_Dist "0002FFFF00FF00FFh";
BA_ "GenSigStartValue" SG_ 468 ObjIntrst_Dist 255;
BA_ "GenSigTimeout_IC" SG_ 468 ObjIntrst_Dist 630;
BA_ "GenSigTimeout_ORC" SG_ 468 ObjIntrst_Dist 210;
BA_ "FlexKomSID" SG_ 468 ObjIntrst_Dist 403;
BA_ "FlexKomSigStartPos" SG_ 468 ObjIntrst_Dist 7;
BA_ "FlexKomSigLaenge" SG_ 468 ObjIntrst_Dist 64;
BA_ "FlexKomSigName" SG_ 468 ObjIntrst_Dist "DAS_A2_PKT";
BA_ "FlexKomComment" SG_ 468 ObjIntrst_Dist "DAS_A2 Packet";
BA_ "FlexKomIsMotorola" SG_ 468 ObjIntrst_Dist 1;
BA_ "GenSigSNA" SG_ 468 ObjIntrst_Dist "FFh";
BA_ "GenSigCycleTime" SG_ 468 Sys_Dsbl 60;
BA_ "FlexKomSigStartValue" SG_ 468 Sys_Dsbl "0002FFFF00FF00FFh";
BA_ "GenSigTimeout_IC" SG_ 468 Sys_Dsbl 630;
BA_ "GenSigTimeout_ORC" SG_ 468 Sys_Dsbl 210;
BA_ "FlexKomSID" SG_ 468 Sys_Dsbl 403;
BA_ "FlexKomSigStartPos" SG_ 468 Sys_Dsbl 7;
BA_ "FlexKomSigLaenge" SG_ 468 Sys_Dsbl 64;
BA_ "FlexKomSigName" SG_ 468 Sys_Dsbl "DAS_A2_PKT";
BA_ "FlexKomComment" SG_ 468 Sys_Dsbl "DAS_A2 Packet";
BA_ "FlexKomIsMotorola" SG_ 468 Sys_Dsbl 1;
BA_ "GenSigSNA" SG_ 468 Sys_Dsbl "0h";
BA_ "GenSigCycleTime" SG_ 468 FCW_Stat 60;
BA_ "FlexKomSigStartValue" SG_ 468 FCW_Stat "0002FFFF00FF00FFh";
BA_ "GenSigTimeout_CBC" SG_ 468 FCW_Stat 630;
BA_ "GenSigTimeout_IC" SG_ 468 FCW_Stat 630;
BA_ "GenSigTimeout_ORC" SG_ 468 FCW_Stat 210;
BA_ "FlexKomSID" SG_ 468 FCW_Stat 403;
BA_ "FlexKomSigStartPos" SG_ 468 FCW_Stat 7;
BA_ "FlexKomSigLaenge" SG_ 468 FCW_Stat 64;
BA_ "FlexKomSigName" SG_ 468 FCW_Stat "DAS_A2_PKT";
BA_ "FlexKomComment" SG_ 468 FCW_Stat "DAS_A2 Packet";
BA_ "FlexKomIsMotorola" SG_ 468 FCW_Stat 1;
BA_ "GenSigSNA" SG_ 468 FCW_Stat "1h";
BA_ "GenSigCycleTime" SG_ 468 DTR_Spd_Dsr 60;
BA_ "FlexKomSigStartValue" SG_ 468 DTR_Spd_Dsr "0002FFFF00FF00FFh";
BA_ "GenSigStartValue" SG_ 468 DTR_Spd_Dsr 255;
BA_ "GenSigTimeout_IC" SG_ 468 DTR_Spd_Dsr 630;
BA_ "GenSigTimeout_ORC" SG_ 468 DTR_Spd_Dsr 210;
BA_ "FlexKomSID" SG_ 468 DTR_Spd_Dsr 403;
BA_ "FlexKomSigStartPos" SG_ 468 DTR_Spd_Dsr 7;
BA_ "FlexKomSigLaenge" SG_ 468 DTR_Spd_Dsr 64;
BA_ "FlexKomSigName" SG_ 468 DTR_Spd_Dsr "DAS_A2_PKT";
BA_ "FlexKomComment" SG_ 468 DTR_Spd_Dsr "DAS_A2 Packet";
BA_ "FlexKomIsMotorola" SG_ 468 DTR_Spd_Dsr 1;
BA_ "GenSigSNA" SG_ 468 DTR_Spd_Dsr "FFh";
BA_ "GenSigCycleTime" SG_ 468 DTR_FltDisp_Rq 60;
BA_ "FlexKomSigStartValue" SG_ 468 DTR_FltDisp_Rq "0002FFFF00FF00FFh";
BA_ "GenSigTimeout_IC" SG_ 468 DTR_FltDisp_Rq 630;
BA_ "GenSigTimeout_ORC" SG_ 468 DTR_FltDisp_Rq 210;
BA_ "FlexKomSID" SG_ 468 DTR_FltDisp_Rq 403;
BA_ "FlexKomSigStartPos" SG_ 468 DTR_FltDisp_Rq 7;
BA_ "FlexKomSigLaenge" SG_ 468 DTR_FltDisp_Rq 64;
BA_ "FlexKomSigName" SG_ 468 DTR_FltDisp_Rq "DAS_A2_PKT";
BA_ "FlexKomComment" SG_ 468 DTR_FltDisp_Rq "DAS_A2 Packet";
BA_ "FlexKomIsMotorola" SG_ 468 DTR_FltDisp_Rq 1;
BA_ "GenSigSNA" SG_ 468 DTR_FltDisp_Rq "Fh";
BA_ "GenSigCycleTime" SG_ 468 MC_DAS_A2 60;
BA_ "FlexKomSigStartValue" SG_ 468 MC_DAS_A2 "0002FFFF00FF00FFh";
BA_ "GenSigTimeout_IC" SG_ 468 MC_DAS_A2 630;
BA_ "GenSigTimeout_ORC" SG_ 468 MC_DAS_A2 210;
BA_ "FlexKomSID" SG_ 468 MC_DAS_A2 403;
BA_ "FlexKomSigStartPos" SG_ 468 MC_DAS_A2 7;
BA_ "FlexKomSigLaenge" SG_ 468 MC_DAS_A2 64;
BA_ "FlexKomSigName" SG_ 468 MC_DAS_A2 "DAS_A2_PKT";
BA_ "FlexKomComment" SG_ 468 MC_DAS_A2 "DAS_A2 Packet";
BA_ "FlexKomIsMotorola" SG_ 468 MC_DAS_A2 1;
BA_ "GenSigSNA" SG_ 468 MC_DAS_A2 "0h";
BA_ "GenSigCycleTime" SG_ 468 CRC_DAS_A2 60;
BA_ "FlexKomSigStartValue" SG_ 468 CRC_DAS_A2 "0002FFFF00FF00FFh";
BA_ "GenSigStartValue" SG_ 468 CRC_DAS_A2 255;
BA_ "GenSigTimeout_IC" SG_ 468 CRC_DAS_A2 630;
BA_ "GenSigTimeout_ORC" SG_ 468 CRC_DAS_A2 210;
BA_ "FlexKomSID" SG_ 468 CRC_DAS_A2 403;
BA_ "FlexKomSigStartPos" SG_ 468 CRC_DAS_A2 7;
BA_ "FlexKomSigLaenge" SG_ 468 CRC_DAS_A2 64;
BA_ "FlexKomSigName" SG_ 468 CRC_DAS_A2 "DAS_A2_PKT";
BA_ "FlexKomComment" SG_ 468 CRC_DAS_A2 "DAS_A2 Packet";
BA_ "FlexKomIsMotorola" SG_ 468 CRC_DAS_A2 1;
BA_ "GenSigSNA" SG_ 468 CRC_DAS_A2 "FFh";
BA_ "GenSigSendType" SG_ 480 SBR2RowCentralSeatSts 5;
BA_ "GenSigCycleTime" SG_ 480 SBR2RowCentralSeatSts 1000;
BA_ "FlexKomSigStartValue" SG_ 480 SBR2RowCentralSeatSts "03h";
BA_ "GenSigStartValue" SG_ 480 SBR2RowCentralSeatSts 3;
BA_ "FlexKomSID" SG_ 480 SBR2RowCentralSeatSts 1969;
BA_ "FlexKomSigStartPos" SG_ 480 SBR2RowCentralSeatSts 1;
BA_ "FlexKomSigLaenge" SG_ 480 SBR2RowCentralSeatSts 2;
BA_ "FlexKomSigName" SG_ 480 SBR2RowCentralSeatSts "SBR2RowCentralSeatSts";
BA_ "FlexKomComment" SG_ 480 SBR2RowCentralSeatSts "Second row central seatbelt switch status";
BA_ "FlexKomIsMotorola" SG_ 480 SBR2RowCentralSeatSts 1;
BA_ "GenSigSNA" SG_ 480 SBR2RowCentralSeatSts "3h";
BA_ "GenSigSendType" SG_ 480 SBR2RowLeftSeatSts 5;
BA_ "GenSigCycleTime" SG_ 480 SBR2RowLeftSeatSts 1000;
BA_ "FlexKomSigStartValue" SG_ 480 SBR2RowLeftSeatSts "03h";
BA_ "GenSigStartValue" SG_ 480 SBR2RowLeftSeatSts 3;
BA_ "FlexKomSID" SG_ 480 SBR2RowLeftSeatSts 1970;
BA_ "FlexKomSigStartPos" SG_ 480 SBR2RowLeftSeatSts 3;
BA_ "FlexKomSigLaenge" SG_ 480 SBR2RowLeftSeatSts 2;
BA_ "FlexKomSigName" SG_ 480 SBR2RowLeftSeatSts "SBR2RowLeftSeatSts";
BA_ "FlexKomComment" SG_ 480 SBR2RowLeftSeatSts "Second row left seatbelt switch status";
BA_ "FlexKomIsMotorola" SG_ 480 SBR2RowLeftSeatSts 1;
BA_ "GenSigSNA" SG_ 480 SBR2RowLeftSeatSts "3h";
BA_ "GenSigSendType" SG_ 480 SBR2RowRightSeatSts 5;
BA_ "GenSigCycleTime" SG_ 480 SBR2RowRightSeatSts 1000;
BA_ "FlexKomSigStartValue" SG_ 480 SBR2RowRightSeatSts "03h";
BA_ "GenSigStartValue" SG_ 480 SBR2RowRightSeatSts 3;
BA_ "FlexKomSID" SG_ 480 SBR2RowRightSeatSts 1971;
BA_ "FlexKomSigStartPos" SG_ 480 SBR2RowRightSeatSts 5;
BA_ "FlexKomSigLaenge" SG_ 480 SBR2RowRightSeatSts 2;
BA_ "FlexKomSigName" SG_ 480 SBR2RowRightSeatSts "SBR2RowRightSeatSts";
BA_ "FlexKomComment" SG_ 480 SBR2RowRightSeatSts "Second row right seatbelt switch status";
BA_ "FlexKomIsMotorola" SG_ 480 SBR2RowRightSeatSts 1;
BA_ "GenSigSNA" SG_ 480 SBR2RowRightSeatSts "3h";
BA_ "GenSigSendType" SG_ 480 SBR3RowCentralSeatSts 5;
BA_ "GenSigCycleTime" SG_ 480 SBR3RowCentralSeatSts 1000;
BA_ "FlexKomSigStartValue" SG_ 480 SBR3RowCentralSeatSts "03h";
BA_ "GenSigStartValue" SG_ 480 SBR3RowCentralSeatSts 3;
BA_ "FlexKomSID" SG_ 480 SBR3RowCentralSeatSts 1972;
BA_ "FlexKomSigStartPos" SG_ 480 SBR3RowCentralSeatSts 7;
BA_ "FlexKomSigLaenge" SG_ 480 SBR3RowCentralSeatSts 2;
BA_ "FlexKomSigName" SG_ 480 SBR3RowCentralSeatSts "SBR3RowCentralSeatSts";
BA_ "FlexKomComment" SG_ 480 SBR3RowCentralSeatSts "Third row central seatbelt switch status";
BA_ "FlexKomIsMotorola" SG_ 480 SBR3RowCentralSeatSts 1;
BA_ "GenSigSNA" SG_ 480 SBR3RowCentralSeatSts "3h";
BA_ "GenSigSendType" SG_ 480 SBR3RowLeftSeatSts 5;
BA_ "GenSigCycleTime" SG_ 480 SBR3RowLeftSeatSts 1000;
BA_ "FlexKomSigStartValue" SG_ 480 SBR3RowLeftSeatSts "03h";
BA_ "GenSigStartValue" SG_ 480 SBR3RowLeftSeatSts 3;
BA_ "FlexKomSID" SG_ 480 SBR3RowLeftSeatSts 1973;
BA_ "FlexKomSigStartPos" SG_ 480 SBR3RowLeftSeatSts 9;
BA_ "FlexKomSigLaenge" SG_ 480 SBR3RowLeftSeatSts 2;
BA_ "FlexKomSigName" SG_ 480 SBR3RowLeftSeatSts "SBR3RowLeftSeatSts";
BA_ "FlexKomComment" SG_ 480 SBR3RowLeftSeatSts "Third row left seatbelt switch status";
BA_ "FlexKomIsMotorola" SG_ 480 SBR3RowLeftSeatSts 1;
BA_ "GenSigSNA" SG_ 480 SBR3RowLeftSeatSts "3h";
BA_ "GenSigSendType" SG_ 480 SBR3RowRightSeatSts 5;
BA_ "GenSigCycleTime" SG_ 480 SBR3RowRightSeatSts 1000;
BA_ "FlexKomSigStartValue" SG_ 480 SBR3RowRightSeatSts "03h";
BA_ "GenSigStartValue" SG_ 480 SBR3RowRightSeatSts 3;
BA_ "FlexKomSID" SG_ 480 SBR3RowRightSeatSts 1974;
BA_ "FlexKomSigStartPos" SG_ 480 SBR3RowRightSeatSts 11;
BA_ "FlexKomSigLaenge" SG_ 480 SBR3RowRightSeatSts 2;
BA_ "FlexKomSigName" SG_ 480 SBR3RowRightSeatSts "SBR3RowRightSeatSts";
BA_ "FlexKomComment" SG_ 480 SBR3RowRightSeatSts "Third row right seatbelt switch status";
BA_ "FlexKomIsMotorola" SG_ 480 SBR3RowRightSeatSts 1;
BA_ "GenSigSNA" SG_ 480 SBR3RowRightSeatSts "3h";
BA_ "GenSigSendType" SG_ 480 SBR2RowCentralSeatConfigSts 5;
BA_ "GenSigCycleTime" SG_ 480 SBR2RowCentralSeatConfigSts 1000;
BA_ "FlexKomSigStartValue" SG_ 480 SBR2RowCentralSeatConfigSts "00h";
BA_ "FlexKomSID" SG_ 480 SBR2RowCentralSeatConfigSts 1975;
BA_ "FlexKomSigStartPos" SG_ 480 SBR2RowCentralSeatConfigSts 18;
BA_ "FlexKomSigLaenge" SG_ 480 SBR2RowCentralSeatConfigSts 1;
BA_ "FlexKomSigName" SG_ 480 SBR2RowCentralSeatConfigSts "SBR2RowCentralSeatConfigSts";
BA_ "FlexKomComment" SG_ 480 SBR2RowCentralSeatConfigSts "Second row central seatbelt switch configuration; ";
BA_ "FlexKomIsMotorola" SG_ 480 SBR2RowCentralSeatConfigSts 1;
BA_ "GenSigSNA" SG_ 480 SBR2RowCentralSeatConfigSts "0h";
BA_ "GenSigSendType" SG_ 480 SBR2RowLeftSeatConfigSts 5;
BA_ "GenSigCycleTime" SG_ 480 SBR2RowLeftSeatConfigSts 1000;
BA_ "FlexKomSigStartValue" SG_ 480 SBR2RowLeftSeatConfigSts "00h";
BA_ "FlexKomSID" SG_ 480 SBR2RowLeftSeatConfigSts 1976;
BA_ "FlexKomSigStartPos" SG_ 480 SBR2RowLeftSeatConfigSts 19;
BA_ "FlexKomSigLaenge" SG_ 480 SBR2RowLeftSeatConfigSts 1;
BA_ "FlexKomSigName" SG_ 480 SBR2RowLeftSeatConfigSts "SBR2RowLeftSeatConfigSts";
BA_ "FlexKomComment" SG_ 480 SBR2RowLeftSeatConfigSts "Second row left seatbelt switch configuration; Sea";
BA_ "FlexKomIsMotorola" SG_ 480 SBR2RowLeftSeatConfigSts 1;
BA_ "GenSigSNA" SG_ 480 SBR2RowLeftSeatConfigSts "0h";
BA_ "GenSigSendType" SG_ 480 SBR2RowRightSeatConfigSts 5;
BA_ "GenSigCycleTime" SG_ 480 SBR2RowRightSeatConfigSts 1000;
BA_ "FlexKomSigStartValue" SG_ 480 SBR2RowRightSeatConfigSts "00h";
BA_ "FlexKomSID" SG_ 480 SBR2RowRightSeatConfigSts 1977;
BA_ "FlexKomSigStartPos" SG_ 480 SBR2RowRightSeatConfigSts 20;
BA_ "FlexKomSigLaenge" SG_ 480 SBR2RowRightSeatConfigSts 1;
BA_ "FlexKomSigName" SG_ 480 SBR2RowRightSeatConfigSts "SBR2RowRightSeatConfigSts";
BA_ "FlexKomComment" SG_ 480 SBR2RowRightSeatConfigSts "Second row right seatbelt switch configuration; Se";
BA_ "FlexKomIsMotorola" SG_ 480 SBR2RowRightSeatConfigSts 1;
BA_ "GenSigSNA" SG_ 480 SBR2RowRightSeatConfigSts "0h";
BA_ "GenSigSendType" SG_ 480 SBR3RowCentralSeatConfigSts 5;
BA_ "GenSigCycleTime" SG_ 480 SBR3RowCentralSeatConfigSts 1000;
BA_ "FlexKomSigStartValue" SG_ 480 SBR3RowCentralSeatConfigSts "00h";
BA_ "FlexKomSID" SG_ 480 SBR3RowCentralSeatConfigSts 1978;
BA_ "FlexKomSigStartPos" SG_ 480 SBR3RowCentralSeatConfigSts 21;
BA_ "FlexKomSigLaenge" SG_ 480 SBR3RowCentralSeatConfigSts 1;
BA_ "FlexKomSigName" SG_ 480 SBR3RowCentralSeatConfigSts "SBR3RowCentralSeatConfigSts";
BA_ "FlexKomComment" SG_ 480 SBR3RowCentralSeatConfigSts "Third row central seatbelt switch configuration; S";
BA_ "FlexKomIsMotorola" SG_ 480 SBR3RowCentralSeatConfigSts 1;
BA_ "GenSigSNA" SG_ 480 SBR3RowCentralSeatConfigSts "0h";
BA_ "GenSigSendType" SG_ 480 SBR3RowLeftSeatConfigSts 5;
BA_ "GenSigCycleTime" SG_ 480 SBR3RowLeftSeatConfigSts 1000;
BA_ "FlexKomSigStartValue" SG_ 480 SBR3RowLeftSeatConfigSts "00h";
BA_ "FlexKomSID" SG_ 480 SBR3RowLeftSeatConfigSts 1979;
BA_ "FlexKomSigStartPos" SG_ 480 SBR3RowLeftSeatConfigSts 22;
BA_ "FlexKomSigLaenge" SG_ 480 SBR3RowLeftSeatConfigSts 1;
BA_ "FlexKomSigName" SG_ 480 SBR3RowLeftSeatConfigSts "SBR3RowLeftSeatConfigSts";
BA_ "FlexKomComment" SG_ 480 SBR3RowLeftSeatConfigSts "Third row left seatbelt switch configuration; Seat";
BA_ "FlexKomIsMotorola" SG_ 480 SBR3RowLeftSeatConfigSts 1;
BA_ "GenSigSNA" SG_ 480 SBR3RowLeftSeatConfigSts "0h";
BA_ "GenSigSendType" SG_ 480 SBR3RowRightSeatConfigSts 5;
BA_ "GenSigCycleTime" SG_ 480 SBR3RowRightSeatConfigSts 1000;
BA_ "FlexKomSigStartValue" SG_ 480 SBR3RowRightSeatConfigSts "00h";
BA_ "FlexKomSID" SG_ 480 SBR3RowRightSeatConfigSts 1980;
BA_ "FlexKomSigStartPos" SG_ 480 SBR3RowRightSeatConfigSts 23;
BA_ "FlexKomSigLaenge" SG_ 480 SBR3RowRightSeatConfigSts 1;
BA_ "FlexKomSigName" SG_ 480 SBR3RowRightSeatConfigSts "SBR3RowRightSeatConfigSts";
BA_ "FlexKomComment" SG_ 480 SBR3RowRightSeatConfigSts "Third row right seatbelt switch configuration; Sea";
BA_ "FlexKomIsMotorola" SG_ 480 SBR3RowRightSeatConfigSts 1;
BA_ "GenSigSNA" SG_ 480 SBR3RowRightSeatConfigSts "0h";
BA_ "GenSigCycleTime" SG_ 500 EngTrqRq_DAS 20;
BA_ "FlexKomSigStartValue" SG_ 500 EngTrqRq_DAS "1FFF0CCB000000FFh";
BA_ "GenSigStartValue" SG_ 500 EngTrqRq_DAS 8191;
BA_ "FlexKomSID" SG_ 500 EngTrqRq_DAS 1043;
BA_ "FlexKomSigStartPos" SG_ 500 EngTrqRq_DAS 7;
BA_ "FlexKomSigLaenge" SG_ 500 EngTrqRq_DAS 64;
BA_ "FlexKomSigName" SG_ 500 EngTrqRq_DAS "DAS_A3_PKT";
BA_ "FlexKomComment" SG_ 500 EngTrqRq_DAS "DAS_A3_PKT";
BA_ "FlexKomIsMotorola" SG_ 500 EngTrqRq_DAS 1;
BA_ "GenSigSNA" SG_ 500 EngTrqRq_DAS "1FFFh";
BA_ "GenSigCycleTime" SG_ 500 ACC_Still_Cmd 20;
BA_ "FlexKomSigStartValue" SG_ 500 ACC_Still_Cmd "1FFF0CCB000000FFh";
BA_ "GenSigTimeout_ORC" SG_ 500 ACC_Still_Cmd 70;
BA_ "FlexKomSID" SG_ 500 ACC_Still_Cmd 1043;
BA_ "FlexKomSigStartPos" SG_ 500 ACC_Still_Cmd 7;
BA_ "FlexKomSigLaenge" SG_ 500 ACC_Still_Cmd 64;
BA_ "FlexKomSigName" SG_ 500 ACC_Still_Cmd "DAS_A3_PKT";
BA_ "FlexKomComment" SG_ 500 ACC_Still_Cmd "DAS_A3_PKT";
BA_ "FlexKomIsMotorola" SG_ 500 ACC_Still_Cmd 1;
BA_ "GenSigSNA" SG_ 500 ACC_Still_Cmd "0h";
BA_ "GenSigCycleTime" SG_ 500 ACC_Drive_Cmd 20;
BA_ "FlexKomSigStartValue" SG_ 500 ACC_Drive_Cmd "1FFF0CCB000000FFh";
BA_ "GenSigTimeout_ORC" SG_ 500 ACC_Drive_Cmd 70;
BA_ "FlexKomSID" SG_ 500 ACC_Drive_Cmd 1043;
BA_ "FlexKomSigStartPos" SG_ 500 ACC_Drive_Cmd 7;
BA_ "FlexKomSigLaenge" SG_ 500 ACC_Drive_Cmd 64;
BA_ "FlexKomSigName" SG_ 500 ACC_Drive_Cmd "DAS_A3_PKT";
BA_ "FlexKomComment" SG_ 500 ACC_Drive_Cmd "DAS_A3_PKT";
BA_ "FlexKomIsMotorola" SG_ 500 ACC_Drive_Cmd 1;
BA_ "GenSigSNA" SG_ 500 ACC_Drive_Cmd "0h";
BA_ "GenSigCycleTime" SG_ 500 EngTrqMaxRq_DAS 20;
BA_ "FlexKomSigStartValue" SG_ 500 EngTrqMaxRq_DAS "1FFF0CCB000000FFh";
BA_ "GenSigTimeout_ORC" SG_ 500 EngTrqMaxRq_DAS 70;
BA_ "FlexKomSID" SG_ 500 EngTrqMaxRq_DAS 1043;
BA_ "FlexKomSigStartPos" SG_ 500 EngTrqMaxRq_DAS 7;
BA_ "FlexKomSigLaenge" SG_ 500 EngTrqMaxRq_DAS 64;
BA_ "FlexKomSigName" SG_ 500 EngTrqMaxRq_DAS "DAS_A3_PKT";
BA_ "FlexKomComment" SG_ 500 EngTrqMaxRq_DAS "DAS_A3_PKT";
BA_ "FlexKomIsMotorola" SG_ 500 EngTrqMaxRq_DAS 1;
BA_ "GenSigSNA" SG_ 500 EngTrqMaxRq_DAS "0h";
BA_ "GenSigCycleTime" SG_ 500 DAS_ACCEL_Rq 20;
BA_ "FlexKomSigStartValue" SG_ 500 DAS_ACCEL_Rq "1FFF0CCB000000FFh";
BA_ "GenSigStartValue" SG_ 500 DAS_ACCEL_Rq 3275;
BA_ "GenSigTimeout_ORC" SG_ 500 DAS_ACCEL_Rq 70;
BA_ "FlexKomSID" SG_ 500 DAS_ACCEL_Rq 1043;
BA_ "FlexKomSigStartPos" SG_ 500 DAS_ACCEL_Rq 7;
BA_ "FlexKomSigLaenge" SG_ 500 DAS_ACCEL_Rq 64;
BA_ "FlexKomSigName" SG_ 500 DAS_ACCEL_Rq "DAS_A3_PKT";
BA_ "FlexKomComment" SG_ 500 DAS_ACCEL_Rq "DAS_A3_PKT";
BA_ "FlexKomIsMotorola" SG_ 500 DAS_ACCEL_Rq 1;
BA_ "GenSigSNA" SG_ 500 DAS_ACCEL_Rq "FFFh";
BA_ "GenSigCycleTime" SG_ 500 ACC_Enbl 20;
BA_ "FlexKomSigStartValue" SG_ 500 ACC_Enbl "1FFF0CCB000000FFh";
BA_ "GenSigTimeout_IC" SG_ 500 ACC_Enbl 210;
BA_ "GenSigTimeout_ORC" SG_ 500 ACC_Enbl 70;
BA_ "FlexKomSID" SG_ 500 ACC_Enbl 1043;
BA_ "FlexKomSigStartPos" SG_ 500 ACC_Enbl 7;
BA_ "FlexKomSigLaenge" SG_ 500 ACC_Enbl 64;
BA_ "FlexKomSigName" SG_ 500 ACC_Enbl "DAS_A3_PKT";
BA_ "FlexKomComment" SG_ 500 ACC_Enbl "DAS_A3_PKT";
BA_ "FlexKomIsMotorola" SG_ 500 ACC_Enbl 1;
BA_ "GenSigSNA" SG_ 500 ACC_Enbl "0h";
BA_ "GenSigCycleTime" SG_ 500 ACC_Engd 20;
BA_ "FlexKomSigStartValue" SG_ 500 ACC_Engd "1FFF0CCB000000FFh";
BA_ "GenSigTimeout_IC" SG_ 500 ACC_Engd 210;
BA_ "GenSigTimeout_ORC" SG_ 500 ACC_Engd 70;
BA_ "FlexKomSID" SG_ 500 ACC_Engd 1043;
BA_ "FlexKomSigStartPos" SG_ 500 ACC_Engd 7;
BA_ "FlexKomSigLaenge" SG_ 500 ACC_Engd 64;
BA_ "FlexKomSigName" SG_ 500 ACC_Engd "DAS_A3_PKT";
BA_ "FlexKomComment" SG_ 500 ACC_Engd "DAS_A3_PKT";
BA_ "FlexKomIsMotorola" SG_ 500 ACC_Engd 1;
BA_ "GenSigSNA" SG_ 500 ACC_Engd "0h";
BA_ "GenSigCycleTime" SG_ 500 ACCFineCtrlDsbl 20;
BA_ "FlexKomSigStartValue" SG_ 500 ACCFineCtrlDsbl "1FFF0CCB000000FFh";
BA_ "FlexKomSID" SG_ 500 ACCFineCtrlDsbl 1043;
BA_ "FlexKomSigStartPos" SG_ 500 ACCFineCtrlDsbl 7;
BA_ "FlexKomSigLaenge" SG_ 500 ACCFineCtrlDsbl 64;
BA_ "FlexKomSigName" SG_ 500 ACCFineCtrlDsbl "DAS_A3_PKT";
BA_ "FlexKomComment" SG_ 500 ACCFineCtrlDsbl "DAS_A3_PKT";
BA_ "FlexKomIsMotorola" SG_ 500 ACCFineCtrlDsbl 1;
BA_ "GenSigSNA" SG_ 500 ACCFineCtrlDsbl "0h";
BA_ "GenSigCycleTime" SG_ 500 DsblFuelShutOff_ACC 20;
BA_ "FlexKomSigStartValue" SG_ 500 DsblFuelShutOff_ACC "1FFF0CCB000000FFh";
BA_ "FlexKomSID" SG_ 500 DsblFuelShutOff_ACC 1043;
BA_ "FlexKomSigStartPos" SG_ 500 DsblFuelShutOff_ACC 7;
BA_ "FlexKomSigLaenge" SG_ 500 DsblFuelShutOff_ACC 64;
BA_ "FlexKomSigName" SG_ 500 DsblFuelShutOff_ACC "DAS_A3_PKT";
BA_ "FlexKomComment" SG_ 500 DsblFuelShutOff_ACC "DAS_A3_PKT";
BA_ "FlexKomIsMotorola" SG_ 500 DsblFuelShutOff_ACC 1;
BA_ "GenSigSNA" SG_ 500 DsblFuelShutOff_ACC "0h";
BA_ "GenSigCycleTime" SG_ 500 GrMax_RqDAS 20;
BA_ "FlexKomSigStartValue" SG_ 500 GrMax_RqDAS "1FFF0CCB000000FFh";
BA_ "GenSigTimeout_ORC" SG_ 500 GrMax_RqDAS 70;
BA_ "FlexKomSID" SG_ 500 GrMax_RqDAS 1043;
BA_ "FlexKomSigStartPos" SG_ 500 GrMax_RqDAS 7;
BA_ "FlexKomSigLaenge" SG_ 500 GrMax_RqDAS 64;
BA_ "FlexKomSigName" SG_ 500 GrMax_RqDAS "DAS_A3_PKT";
BA_ "FlexKomComment" SG_ 500 GrMax_RqDAS "DAS_A3_PKT";
BA_ "FlexKomIsMotorola" SG_ 500 GrMax_RqDAS 1;
BA_ "GenSigSNA" SG_ 500 GrMax_RqDAS "0h";
BA_ "GenSigCycleTime" SG_ 500 DAS_Rq_ID 20;
BA_ "FlexKomSigStartValue" SG_ 500 DAS_Rq_ID "1FFF0CCB000000FFh";
BA_ "GenSigTimeout_ORC" SG_ 500 DAS_Rq_ID 70;
BA_ "FlexKomSID" SG_ 500 DAS_Rq_ID 1043;
BA_ "FlexKomSigStartPos" SG_ 500 DAS_Rq_ID 7;
BA_ "FlexKomSigLaenge" SG_ 500 DAS_Rq_ID 64;
BA_ "FlexKomSigName" SG_ 500 DAS_Rq_ID "DAS_A3_PKT";
BA_ "FlexKomComment" SG_ 500 DAS_Rq_ID "DAS_A3_PKT";
BA_ "FlexKomIsMotorola" SG_ 500 DAS_Rq_ID 1;
BA_ "GenSigSNA" SG_ 500 DAS_Rq_ID "7h";
BA_ "GenSigCycleTime" SG_ 500 AS_ChimeRq_RF 20;
BA_ "FlexKomSigStartValue" SG_ 500 AS_ChimeRq_RF "1FFF0CCB000000FFh";
BA_ "FlexKomSID" SG_ 500 AS_ChimeRq_RF 1043;
BA_ "FlexKomSigStartPos" SG_ 500 AS_ChimeRq_RF 7;
BA_ "FlexKomSigLaenge" SG_ 500 AS_ChimeRq_RF 64;
BA_ "FlexKomSigName" SG_ 500 AS_ChimeRq_RF "DAS_A3_PKT";
BA_ "FlexKomComment" SG_ 500 AS_ChimeRq_RF "DAS_A3_PKT";
BA_ "FlexKomIsMotorola" SG_ 500 AS_ChimeRq_RF 1;
BA_ "GenSigSNA" SG_ 500 AS_ChimeRq_RF "0h";
BA_ "GenSigCycleTime" SG_ 500 AS_ChimeRq_LF 20;
BA_ "FlexKomSigStartValue" SG_ 500 AS_ChimeRq_LF "1FFF0CCB000000FFh";
BA_ "FlexKomSID" SG_ 500 AS_ChimeRq_LF 1043;
BA_ "FlexKomSigStartPos" SG_ 500 AS_ChimeRq_LF 7;
BA_ "FlexKomSigLaenge" SG_ 500 AS_ChimeRq_LF 64;
BA_ "FlexKomSigName" SG_ 500 AS_ChimeRq_LF "DAS_A3_PKT";
BA_ "FlexKomComment" SG_ 500 AS_ChimeRq_LF "DAS_A3_PKT";
BA_ "FlexKomIsMotorola" SG_ 500 AS_ChimeRq_LF 1;
BA_ "GenSigSNA" SG_ 500 AS_ChimeRq_LF "0h";
BA_ "GenSigCycleTime" SG_ 500 AS_ChimeTyp 20;
BA_ "FlexKomSigStartValue" SG_ 500 AS_ChimeTyp "1FFF0CCB000000FFh";
BA_ "GenSigTimeout_CBC" SG_ 500 AS_ChimeTyp 210;
BA_ "GenSigTimeout_IC" SG_ 500 AS_ChimeTyp 210;
BA_ "GenSigTimeout_ORC" SG_ 500 AS_ChimeTyp 70;
BA_ "FlexKomSID" SG_ 500 AS_ChimeTyp 1043;
BA_ "FlexKomSigStartPos" SG_ 500 AS_ChimeTyp 7;
BA_ "FlexKomSigLaenge" SG_ 500 AS_ChimeTyp 64;
BA_ "FlexKomSigName" SG_ 500 AS_ChimeTyp "DAS_A3_PKT";
BA_ "FlexKomComment" SG_ 500 AS_ChimeTyp "DAS_A3_PKT";
BA_ "FlexKomIsMotorola" SG_ 500 AS_ChimeTyp 1;
BA_ "GenSigSNA" SG_ 500 AS_ChimeTyp "Fh";
BA_ "GenSigCycleTime" SG_ 500 DAS_Sts 20;
BA_ "FlexKomSigStartValue" SG_ 500 DAS_Sts "1FFF0CCB000000FFh";
BA_ "FlexKomSID" SG_ 500 DAS_Sts 1043;
BA_ "FlexKomSigStartPos" SG_ 500 DAS_Sts 7;
BA_ "FlexKomSigLaenge" SG_ 500 DAS_Sts 64;
BA_ "FlexKomSigName" SG_ 500 DAS_Sts "DAS_A3_PKT";
BA_ "FlexKomComment" SG_ 500 DAS_Sts "DAS_A3_PKT";
BA_ "FlexKomIsMotorola" SG_ 500 DAS_Sts 1;
BA_ "GenSigSNA" SG_ 500 DAS_Sts "3h";
BA_ "GenSigCycleTime" SG_ 500 Brk_Jrk_Rq 20;
BA_ "FlexKomSigStartValue" SG_ 500 Brk_Jrk_Rq "1FFF0CCB000000FFh";
BA_ "FlexKomSID" SG_ 500 Brk_Jrk_Rq 1043;
BA_ "FlexKomSigStartPos" SG_ 500 Brk_Jrk_Rq 7;
BA_ "FlexKomSigLaenge" SG_ 500 Brk_Jrk_Rq 64;
BA_ "FlexKomSigName" SG_ 500 Brk_Jrk_Rq "DAS_A3_PKT";
BA_ "FlexKomComment" SG_ 500 Brk_Jrk_Rq "DAS_A3_PKT";
BA_ "FlexKomIsMotorola" SG_ 500 Brk_Jrk_Rq 1;
BA_ "GenSigSNA" SG_ 500 Brk_Jrk_Rq "0h";
BA_ "GenSigCycleTime" SG_ 500 Brk_PreFill_Rq 20;
BA_ "FlexKomSigStartValue" SG_ 500 Brk_PreFill_Rq "1FFF0CCB000000FFh";
BA_ "GenSigTimeout_ORC" SG_ 500 Brk_PreFill_Rq 70;
BA_ "FlexKomSID" SG_ 500 Brk_PreFill_Rq 1043;
BA_ "FlexKomSigStartPos" SG_ 500 Brk_PreFill_Rq 7;
BA_ "FlexKomSigLaenge" SG_ 500 Brk_PreFill_Rq 64;
BA_ "FlexKomSigName" SG_ 500 Brk_PreFill_Rq "DAS_A3_PKT";
BA_ "FlexKomComment" SG_ 500 Brk_PreFill_Rq "DAS_A3_PKT";
BA_ "FlexKomIsMotorola" SG_ 500 Brk_PreFill_Rq 1;
BA_ "GenSigSNA" SG_ 500 Brk_PreFill_Rq "0h";
BA_ "GenSigCycleTime" SG_ 500 As_DispRq 20;
BA_ "FlexKomSigStartValue" SG_ 500 As_DispRq "1FFF0CCB000000FFh";
BA_ "GenSigTimeout_IC" SG_ 500 As_DispRq 210;
BA_ "GenSigTimeout_ORC" SG_ 500 As_DispRq 70;
BA_ "FlexKomSID" SG_ 500 As_DispRq 1043;
BA_ "FlexKomSigStartPos" SG_ 500 As_DispRq 7;
BA_ "FlexKomSigLaenge" SG_ 500 As_DispRq 64;
BA_ "FlexKomSigName" SG_ 500 As_DispRq "DAS_A3_PKT";
BA_ "FlexKomComment" SG_ 500 As_DispRq "DAS_A3_PKT";
BA_ "FlexKomIsMotorola" SG_ 500 As_DispRq 1;
BA_ "GenSigSNA" SG_ 500 As_DispRq "3h";
BA_ "GenSigCycleTime" SG_ 500 MC_DAS_A3 20;
BA_ "FlexKomSigStartValue" SG_ 500 MC_DAS_A3 "1FFF0CCB000000FFh";
BA_ "FlexKomSID" SG_ 500 MC_DAS_A3 1043;
BA_ "FlexKomSigStartPos" SG_ 500 MC_DAS_A3 7;
BA_ "FlexKomSigLaenge" SG_ 500 MC_DAS_A3 64;
BA_ "FlexKomSigName" SG_ 500 MC_DAS_A3 "DAS_A3_PKT";
BA_ "FlexKomComment" SG_ 500 MC_DAS_A3 "DAS_A3_PKT";
BA_ "FlexKomIsMotorola" SG_ 500 MC_DAS_A3 1;
BA_ "GenSigSNA" SG_ 500 MC_DAS_A3 "0h";
BA_ "GenSigCycleTime" SG_ 500 CRC_DAS_A3 20;
BA_ "FlexKomSigStartValue" SG_ 500 CRC_DAS_A3 "1FFF0CCB000000FFh";
BA_ "GenSigStartValue" SG_ 500 CRC_DAS_A3 255;
BA_ "FlexKomSID" SG_ 500 CRC_DAS_A3 1043;
BA_ "FlexKomSigStartPos" SG_ 500 CRC_DAS_A3 7;
BA_ "FlexKomSigLaenge" SG_ 500 CRC_DAS_A3 64;
BA_ "FlexKomSigName" SG_ 500 CRC_DAS_A3 "DAS_A3_PKT";
BA_ "FlexKomComment" SG_ 500 CRC_DAS_A3 "DAS_A3_PKT";
BA_ "FlexKomIsMotorola" SG_ 500 CRC_DAS_A3 1;
BA_ "GenSigSNA" SG_ 500 CRC_DAS_A3 "FFh";
BA_ "GenSigCycleTime" SG_ 501 HMI_Screens 60;
BA_ "FlexKomSigStartValue" SG_ 501 HMI_Screens "00FFFF00000000FFh";
BA_ "GenSigTimeout_IC" SG_ 501 HMI_Screens 630;
BA_ "GenSigTimeout_ORC" SG_ 501 HMI_Screens 210;
BA_ "FlexKomSID" SG_ 501 HMI_Screens 1717;
BA_ "FlexKomSigStartPos" SG_ 501 HMI_Screens 7;
BA_ "FlexKomSigLaenge" SG_ 501 HMI_Screens 64;
BA_ "FlexKomSigName" SG_ 501 HMI_Screens "DAS_A4_PKT";
BA_ "FlexKomComment" SG_ 501 HMI_Screens "DAS_A4 Packet";
BA_ "FlexKomIsMotorola" SG_ 501 HMI_Screens 1;
BA_ "GenSigSNA" SG_ 501 HMI_Screens "FFh";
BA_ "GenSigCycleTime" SG_ 501 SetSpeed_KPH 60;
BA_ "FlexKomSigStartValue" SG_ 501 SetSpeed_KPH "00FFFF00000000FFh";
BA_ "GenSigStartValue" SG_ 501 SetSpeed_KPH 255;
BA_ "GenSigTimeout_IC" SG_ 501 SetSpeed_KPH 630;
BA_ "FlexKomSID" SG_ 501 SetSpeed_KPH 1717;
BA_ "FlexKomSigStartPos" SG_ 501 SetSpeed_KPH 7;
BA_ "FlexKomSigLaenge" SG_ 501 SetSpeed_KPH 64;
BA_ "FlexKomSigName" SG_ 501 SetSpeed_KPH "DAS_A4_PKT";
BA_ "FlexKomComment" SG_ 501 SetSpeed_KPH "DAS_A4 Packet";
BA_ "FlexKomIsMotorola" SG_ 501 SetSpeed_KPH 1;
BA_ "GenSigSNA" SG_ 501 SetSpeed_KPH "FFh";
BA_ "GenSigCycleTime" SG_ 501 SetSpeed_MPH 60;
BA_ "FlexKomSigStartValue" SG_ 501 SetSpeed_MPH "00FFFF00000000FFh";
BA_ "GenSigStartValue" SG_ 501 SetSpeed_MPH 255;
BA_ "GenSigTimeout_IC" SG_ 501 SetSpeed_MPH 630;
BA_ "GenSigTimeout_ORC" SG_ 501 SetSpeed_MPH 210;
BA_ "FlexKomSID" SG_ 501 SetSpeed_MPH 1717;
BA_ "FlexKomSigStartPos" SG_ 501 SetSpeed_MPH 7;
BA_ "FlexKomSigLaenge" SG_ 501 SetSpeed_MPH 64;
BA_ "FlexKomSigName" SG_ 501 SetSpeed_MPH "DAS_A4_PKT";
BA_ "FlexKomComment" SG_ 501 SetSpeed_MPH "DAS_A4 Packet";
BA_ "FlexKomIsMotorola" SG_ 501 SetSpeed_MPH 1;
BA_ "GenSigSNA" SG_ 501 SetSpeed_MPH "FFh";
BA_ "GenSigCycleTime" SG_ 501 FCW_Off 60;
BA_ "FlexKomSigStartValue" SG_ 501 FCW_Off "00FFFF00000000FFh";
BA_ "GenSigTimeout_CBC" SG_ 501 FCW_Off 630;
BA_ "FlexKomSID" SG_ 501 FCW_Off 1717;
BA_ "FlexKomSigStartPos" SG_ 501 FCW_Off 7;
BA_ "FlexKomSigLaenge" SG_ 501 FCW_Off 64;
BA_ "FlexKomSigName" SG_ 501 FCW_Off "DAS_A4_PKT";
BA_ "FlexKomComment" SG_ 501 FCW_Off "DAS_A4 Packet";
BA_ "FlexKomIsMotorola" SG_ 501 FCW_Off 1;
BA_ "GenSigSNA" SG_ 501 FCW_Off "3h";
BA_ "GenSigCycleTime" SG_ 501 FCW_Error 60;
BA_ "FlexKomSigStartValue" SG_ 501 FCW_Error "00FFFF00000000FFh";
BA_ "GenSigTimeout_IC" SG_ 501 FCW_Error 630;
BA_ "GenSigTimeout_ORC" SG_ 501 FCW_Error 210;
BA_ "FlexKomSID" SG_ 501 FCW_Error 1717;
BA_ "FlexKomSigStartPos" SG_ 501 FCW_Error 7;
BA_ "FlexKomSigLaenge" SG_ 501 FCW_Error 64;
BA_ "FlexKomSigName" SG_ 501 FCW_Error "DAS_A4_PKT";
BA_ "FlexKomComment" SG_ 501 FCW_Error "DAS_A4 Packet";
BA_ "FlexKomIsMotorola" SG_ 501 FCW_Error 1;
BA_ "GenSigSNA" SG_ 501 FCW_Error "3h";
BA_ "GenSigCycleTime" SG_ 501 FCW_SetFar 60;
BA_ "FlexKomSigStartValue" SG_ 501 FCW_SetFar "00FFFF00000000FFh";
BA_ "GenSigTimeout_CBC" SG_ 501 FCW_SetFar 630;
BA_ "GenSigTimeout_IC" SG_ 501 FCW_SetFar 630;
BA_ "GenSigTimeout_ORC" SG_ 501 FCW_SetFar 210;
BA_ "FlexKomSID" SG_ 501 FCW_SetFar 1717;
BA_ "FlexKomSigStartPos" SG_ 501 FCW_SetFar 7;
BA_ "FlexKomSigLaenge" SG_ 501 FCW_SetFar 64;
BA_ "FlexKomSigName" SG_ 501 FCW_SetFar "DAS_A4_PKT";
BA_ "FlexKomComment" SG_ 501 FCW_SetFar "DAS_A4 Packet";
BA_ "FlexKomIsMotorola" SG_ 501 FCW_SetFar 1;
BA_ "GenSigSNA" SG_ 501 FCW_SetFar "0h";
BA_ "GenSigCycleTime" SG_ 501 FCW_BrkOn 60;
BA_ "FlexKomSigStartValue" SG_ 501 FCW_BrkOn "00FFFF00000000FFh";
BA_ "GenSigTimeout_CBC" SG_ 501 FCW_BrkOn 630;
BA_ "GenSigTimeout_IC" SG_ 501 FCW_BrkOn 630;
BA_ "GenSigTimeout_ORC" SG_ 501 FCW_BrkOn 210;
BA_ "FlexKomSID" SG_ 501 FCW_BrkOn 1717;
BA_ "FlexKomSigStartPos" SG_ 501 FCW_BrkOn 7;
BA_ "FlexKomSigLaenge" SG_ 501 FCW_BrkOn 64;
BA_ "FlexKomSigName" SG_ 501 FCW_BrkOn "DAS_A4_PKT";
BA_ "FlexKomComment" SG_ 501 FCW_BrkOn "DAS_A4 Packet";
BA_ "FlexKomIsMotorola" SG_ 501 FCW_BrkOn 1;
BA_ "GenSigSNA" SG_ 501 FCW_BrkOn "0h";
BA_ "GenSigCycleTime" SG_ 501 CIPV_Fused 60;
BA_ "FlexKomSigStartValue" SG_ 501 CIPV_Fused "00FFFF00000000FFh";
BA_ "GenSigTimeout_ORC" SG_ 501 CIPV_Fused 210;
BA_ "FlexKomSID" SG_ 501 CIPV_Fused 1717;
BA_ "FlexKomSigStartPos" SG_ 501 CIPV_Fused 7;
BA_ "FlexKomSigLaenge" SG_ 501 CIPV_Fused 64;
BA_ "FlexKomSigName" SG_ 501 CIPV_Fused "DAS_A4_PKT";
BA_ "FlexKomComment" SG_ 501 CIPV_Fused "DAS_A4 Packet";
BA_ "FlexKomIsMotorola" SG_ 501 CIPV_Fused 1;
BA_ "GenSigSNA" SG_ 501 CIPV_Fused "0h";
BA_ "GenSigCycleTime" SG_ 501 ACC_HMI_SCRN_REQ 60;
BA_ "FlexKomSigStartValue" SG_ 501 ACC_HMI_SCRN_REQ "00FFFF00000000FFh";
BA_ "GenSigTimeout_IC" SG_ 501 ACC_HMI_SCRN_REQ 630;
BA_ "FlexKomSID" SG_ 501 ACC_HMI_SCRN_REQ 1717;
BA_ "FlexKomSigStartPos" SG_ 501 ACC_HMI_SCRN_REQ 7;
BA_ "FlexKomSigLaenge" SG_ 501 ACC_HMI_SCRN_REQ 64;
BA_ "FlexKomSigName" SG_ 501 ACC_HMI_SCRN_REQ "DAS_A4_PKT";
BA_ "FlexKomComment" SG_ 501 ACC_HMI_SCRN_REQ "DAS_A4 Packet";
BA_ "FlexKomIsMotorola" SG_ 501 ACC_HMI_SCRN_REQ 1;
BA_ "GenSigSNA" SG_ 501 ACC_HMI_SCRN_REQ "0h";
BA_ "GenSigCycleTime" SG_ 501 ISO_Display 60;
BA_ "FlexKomSigStartValue" SG_ 501 ISO_Display "00FFFF00000000FFh";
BA_ "GenSigTimeout_IC" SG_ 501 ISO_Display 630;
BA_ "FlexKomSID" SG_ 501 ISO_Display 1717;
BA_ "FlexKomSigStartPos" SG_ 501 ISO_Display 7;
BA_ "FlexKomSigLaenge" SG_ 501 ISO_Display 64;
BA_ "FlexKomSigName" SG_ 501 ISO_Display "DAS_A4_PKT";
BA_ "FlexKomComment" SG_ 501 ISO_Display "DAS_A4 Packet";
BA_ "FlexKomIsMotorola" SG_ 501 ISO_Display 1;
BA_ "GenSigSNA" SG_ 501 ISO_Display "Fh";
BA_ "GenSigCycleTime" SG_ 501 ACCOnOff 60;
BA_ "FlexKomSigStartValue" SG_ 501 ACCOnOff "00FFFF00000000FFh";
BA_ "GenSigTimeout_IC" SG_ 501 ACCOnOff 630;
BA_ "GenSigTimeout_ORC" SG_ 501 ACCOnOff 210;
BA_ "FlexKomSID" SG_ 501 ACCOnOff 1717;
BA_ "FlexKomSigStartPos" SG_ 501 ACCOnOff 7;
BA_ "FlexKomSigLaenge" SG_ 501 ACCOnOff 64;
BA_ "FlexKomSigName" SG_ 501 ACCOnOff "DAS_A4_PKT";
BA_ "FlexKomComment" SG_ 501 ACCOnOff "DAS_A4 Packet";
BA_ "FlexKomIsMotorola" SG_ 501 ACCOnOff 1;
BA_ "GenSigSNA" SG_ 501 ACCOnOff "7h";
BA_ "GenSigCycleTime" SG_ 501 Sm_ICON_Dspl 60;
BA_ "FlexKomSigStartValue" SG_ 501 Sm_ICON_Dspl "00FFFF00000000FFh";
BA_ "GenSigTimeout_IC" SG_ 501 Sm_ICON_Dspl 630;
BA_ "FlexKomSID" SG_ 501 Sm_ICON_Dspl 1717;
BA_ "FlexKomSigStartPos" SG_ 501 Sm_ICON_Dspl 7;
BA_ "FlexKomSigLaenge" SG_ 501 Sm_ICON_Dspl 64;
BA_ "FlexKomSigName" SG_ 501 Sm_ICON_Dspl "DAS_A4_PKT";
BA_ "FlexKomComment" SG_ 501 Sm_ICON_Dspl "DAS_A4 Packet";
BA_ "FlexKomIsMotorola" SG_ 501 Sm_ICON_Dspl 1;
BA_ "GenSigSNA" SG_ 501 Sm_ICON_Dspl "3Fh";
BA_ "GenSigCycleTime" SG_ 501 RadarBlocked 60;
BA_ "FlexKomSigStartValue" SG_ 501 RadarBlocked "00FFFF00000000FFh";
BA_ "GenSigTimeout_IC" SG_ 501 RadarBlocked 630;
BA_ "GenSigTimeout_ORC" SG_ 501 RadarBlocked 210;
BA_ "FlexKomSID" SG_ 501 RadarBlocked 1717;
BA_ "FlexKomSigStartPos" SG_ 501 RadarBlocked 7;
BA_ "FlexKomSigLaenge" SG_ 501 RadarBlocked 64;
BA_ "FlexKomSigName" SG_ 501 RadarBlocked "DAS_A4_PKT";
BA_ "FlexKomComment" SG_ 501 RadarBlocked "DAS_A4 Packet";
BA_ "FlexKomIsMotorola" SG_ 501 RadarBlocked 1;
BA_ "GenSigSNA" SG_ 501 RadarBlocked "0h";
BA_ "GenSigCycleTime" SG_ 501 FCWBrakingOff 60;
BA_ "FlexKomSigStartValue" SG_ 501 FCWBrakingOff "00FFFF00000000FFh";
BA_ "GenSigTimeout_IC" SG_ 501 FCWBrakingOff 630;
BA_ "GenSigTimeout_ORC" SG_ 501 FCWBrakingOff 210;
BA_ "FlexKomSID" SG_ 501 FCWBrakingOff 1717;
BA_ "FlexKomSigStartPos" SG_ 501 FCWBrakingOff 7;
BA_ "FlexKomSigLaenge" SG_ 501 FCWBrakingOff 64;
BA_ "FlexKomSigName" SG_ 501 FCWBrakingOff "DAS_A4_PKT";
BA_ "FlexKomComment" SG_ 501 FCWBrakingOff "DAS_A4 Packet";
BA_ "FlexKomIsMotorola" SG_ 501 FCWBrakingOff 1;
BA_ "GenSigSNA" SG_ 501 FCWBrakingOff "0h";
BA_ "GenSigCycleTime" SG_ 501 ACConlyNA_DASMSts 60;
BA_ "FlexKomSigStartValue" SG_ 501 ACConlyNA_DASMSts "00FFFF00000000FFh";
BA_ "GenSigTimeout_IC" SG_ 501 ACConlyNA_DASMSts 630;
BA_ "FlexKomSID" SG_ 501 ACConlyNA_DASMSts 1717;
BA_ "FlexKomSigStartPos" SG_ 501 ACConlyNA_DASMSts 7;
BA_ "FlexKomSigLaenge" SG_ 501 ACConlyNA_DASMSts 64;
BA_ "FlexKomSigName" SG_ 501 ACConlyNA_DASMSts "DAS_A4_PKT";
BA_ "FlexKomComment" SG_ 501 ACConlyNA_DASMSts "DAS_A4 Packet";
BA_ "FlexKomIsMotorola" SG_ 501 ACConlyNA_DASMSts 1;
BA_ "GenSigSNA" SG_ 501 ACConlyNA_DASMSts "0h";
BA_ "GenSigCycleTime" SG_ 501 NCConlyNA_DASMSts 60;
BA_ "FlexKomSigStartValue" SG_ 501 NCConlyNA_DASMSts "00FFFF00000000FFh";
BA_ "GenSigTimeout_IC" SG_ 501 NCConlyNA_DASMSts 630;
BA_ "FlexKomSID" SG_ 501 NCConlyNA_DASMSts 1717;
BA_ "FlexKomSigStartPos" SG_ 501 NCConlyNA_DASMSts 7;
BA_ "FlexKomSigLaenge" SG_ 501 NCConlyNA_DASMSts 64;
BA_ "FlexKomSigName" SG_ 501 NCConlyNA_DASMSts "DAS_A4_PKT";
BA_ "FlexKomComment" SG_ 501 NCConlyNA_DASMSts "DAS_A4 Packet";
BA_ "FlexKomIsMotorola" SG_ 501 NCConlyNA_DASMSts 1;
BA_ "GenSigSNA" SG_ 501 NCConlyNA_DASMSts "0h";
BA_ "GenSigCycleTime" SG_ 501 ACCFaulted 60;
BA_ "FlexKomSigStartValue" SG_ 501 ACCFaulted "00FFFF00000000FFh";
BA_ "GenSigTimeout_IC" SG_ 501 ACCFaulted 630;
BA_ "GenSigTimeout_ORC" SG_ 501 ACCFaulted 210;
BA_ "FlexKomSID" SG_ 501 ACCFaulted 1717;
BA_ "FlexKomSigStartPos" SG_ 501 ACCFaulted 7;
BA_ "FlexKomSigLaenge" SG_ 501 ACCFaulted 64;
BA_ "FlexKomSigName" SG_ 501 ACCFaulted "DAS_A4_PKT";
BA_ "FlexKomComment" SG_ 501 ACCFaulted "DAS_A4 Packet";
BA_ "FlexKomIsMotorola" SG_ 501 ACCFaulted 1;
BA_ "GenSigSNA" SG_ 501 ACCFaulted "0h";
BA_ "GenSigCycleTime" SG_ 501 FCWonlyNA_DASMSts 60;
BA_ "FlexKomSigStartValue" SG_ 501 FCWonlyNA_DASMSts "00FFFF00000000FFh";
BA_ "FlexKomSID" SG_ 501 FCWonlyNA_DASMSts 1717;
BA_ "FlexKomSigStartPos" SG_ 501 FCWonlyNA_DASMSts 7;
BA_ "FlexKomSigLaenge" SG_ 501 FCWonlyNA_DASMSts 64;
BA_ "FlexKomSigName" SG_ 501 FCWonlyNA_DASMSts "DAS_A4_PKT";
BA_ "FlexKomComment" SG_ 501 FCWonlyNA_DASMSts "DAS_A4 Packet";
BA_ "FlexKomIsMotorola" SG_ 501 FCWonlyNA_DASMSts 1;
BA_ "GenSigSNA" SG_ 501 FCWonlyNA_DASMSts "0h";
BA_ "GenSigCycleTime" SG_ 501 ACCNA_DASMSts 60;
BA_ "FlexKomSigStartValue" SG_ 501 ACCNA_DASMSts "00FFFF00000000FFh";
BA_ "GenSigTimeout_IC" SG_ 501 ACCNA_DASMSts 630;
BA_ "GenSigTimeout_ORC" SG_ 501 ACCNA_DASMSts 210;
BA_ "FlexKomSID" SG_ 501 ACCNA_DASMSts 1717;
BA_ "FlexKomSigStartPos" SG_ 501 ACCNA_DASMSts 7;
BA_ "FlexKomSigLaenge" SG_ 501 ACCNA_DASMSts 64;
BA_ "FlexKomSigName" SG_ 501 ACCNA_DASMSts "DAS_A4_PKT";
BA_ "FlexKomComment" SG_ 501 ACCNA_DASMSts "DAS_A4 Packet";
BA_ "FlexKomIsMotorola" SG_ 501 ACCNA_DASMSts 1;
BA_ "GenSigSNA" SG_ 501 ACCNA_DASMSts "0h";
BA_ "GenSigCycleTime" SG_ 501 NCCNA_DASMSts 60;
BA_ "FlexKomSigStartValue" SG_ 501 NCCNA_DASMSts "00FFFF00000000FFh";
BA_ "GenSigTimeout_IC" SG_ 501 NCCNA_DASMSts 630;
BA_ "GenSigTimeout_ORC" SG_ 501 NCCNA_DASMSts 210;
BA_ "FlexKomSID" SG_ 501 NCCNA_DASMSts 1717;
BA_ "FlexKomSigStartPos" SG_ 501 NCCNA_DASMSts 7;
BA_ "FlexKomSigLaenge" SG_ 501 NCCNA_DASMSts 64;
BA_ "FlexKomSigName" SG_ 501 NCCNA_DASMSts "DAS_A4_PKT";
BA_ "FlexKomComment" SG_ 501 NCCNA_DASMSts "DAS_A4 Packet";
BA_ "FlexKomIsMotorola" SG_ 501 NCCNA_DASMSts 1;
BA_ "GenSigSNA" SG_ 501 NCCNA_DASMSts "0h";
BA_ "GenSigCycleTime" SG_ 501 CameraBlocked 60;
BA_ "FlexKomSigStartValue" SG_ 501 CameraBlocked "00FFFF00000000FFh";
BA_ "GenSigTimeout_IC" SG_ 501 CameraBlocked 630;
BA_ "GenSigTimeout_ORC" SG_ 501 CameraBlocked 210;
BA_ "FlexKomSID" SG_ 501 CameraBlocked 1717;
BA_ "FlexKomSigStartPos" SG_ 501 CameraBlocked 7;
BA_ "FlexKomSigLaenge" SG_ 501 CameraBlocked 64;
BA_ "FlexKomSigName" SG_ 501 CameraBlocked "DAS_A4_PKT";
BA_ "FlexKomComment" SG_ 501 CameraBlocked "DAS_A4 Packet";
BA_ "FlexKomIsMotorola" SG_ 501 CameraBlocked 1;
BA_ "GenSigSNA" SG_ 501 CameraBlocked "0h";
BA_ "GenSigCycleTime" SG_ 501 CameraFailure 60;
BA_ "FlexKomSigStartValue" SG_ 501 CameraFailure "00FFFF00000000FFh";
BA_ "GenSigTimeout_IC" SG_ 501 CameraFailure 630;
BA_ "GenSigTimeout_ORC" SG_ 501 CameraFailure 210;
BA_ "FlexKomSID" SG_ 501 CameraFailure 1717;
BA_ "FlexKomSigStartPos" SG_ 501 CameraFailure 7;
BA_ "FlexKomSigLaenge" SG_ 501 CameraFailure 64;
BA_ "FlexKomSigName" SG_ 501 CameraFailure "DAS_A4_PKT";
BA_ "FlexKomComment" SG_ 501 CameraFailure "DAS_A4 Packet";
BA_ "FlexKomIsMotorola" SG_ 501 CameraFailure 1;
BA_ "GenSigSNA" SG_ 501 CameraFailure "0h";
BA_ "GenSigCycleTime" SG_ 501 ObjIntrstDist 60;
BA_ "FlexKomSigStartValue" SG_ 501 ObjIntrstDist "00FFFF00000000FFh";
BA_ "GenSigStartValue" SG_ 501 ObjIntrstDist 255;
BA_ "GenSigTimeout_ORC" SG_ 501 ObjIntrstDist 210;
BA_ "FlexKomSID" SG_ 501 ObjIntrstDist 1717;
BA_ "FlexKomSigStartPos" SG_ 501 ObjIntrstDist 7;
BA_ "FlexKomSigLaenge" SG_ 501 ObjIntrstDist 64;
BA_ "FlexKomSigName" SG_ 501 ObjIntrstDist "DAS_A4_PKT";
BA_ "FlexKomComment" SG_ 501 ObjIntrstDist "DAS_A4 Packet";
BA_ "FlexKomIsMotorola" SG_ 501 ObjIntrstDist 1;
BA_ "GenSigSNA" SG_ 501 ObjIntrstDist "FFh";
BA_ "GenSigCycleTime" SG_ 512 AirTemp_Outsd 100;
BA_ "FlexKomSigStartValue" SG_ 512 AirTemp_Outsd "FFh";
BA_ "GenSigStartValue" SG_ 512 AirTemp_Outsd 255;
BA_ "GenSigTimeout_IC" SG_ 512 AirTemp_Outsd 1050;
BA_ "GenSigTimeout_ORC" SG_ 512 AirTemp_Outsd 350;
BA_ "FlexKomSID" SG_ 512 AirTemp_Outsd 773;
BA_ "FlexKomSigStartPos" SG_ 512 AirTemp_Outsd 7;
BA_ "FlexKomSigLaenge" SG_ 512 AirTemp_Outsd 8;
BA_ "FlexKomSigName" SG_ 512 AirTemp_Outsd "AirTemp_Outsd";
BA_ "FlexKomComment" SG_ 512 AirTemp_Outsd "Outside air temperature";
BA_ "FlexKomIsMotorola" SG_ 512 AirTemp_Outsd 1;
BA_ "GenSigSNA" SG_ 512 AirTemp_Outsd "FFh";
BA_ "GenSigCycleTime" SG_ 512 AMB_TEMP_AVG 100;
BA_ "FlexKomSigStartValue" SG_ 512 AMB_TEMP_AVG "FFFFh";
BA_ "GenSigStartValue" SG_ 512 AMB_TEMP_AVG 65535;
BA_ "GenSigTimeout_RF_HUB" SG_ 512 AMB_TEMP_AVG 1050;
BA_ "GenSigTimeout_IC" SG_ 512 AMB_TEMP_AVG 1050;
BA_ "GenSigTimeout_ORC" SG_ 512 AMB_TEMP_AVG 350;
BA_ "FlexKomSID" SG_ 512 AMB_TEMP_AVG 840;
BA_ "FlexKomSigStartPos" SG_ 512 AMB_TEMP_AVG 15;
BA_ "FlexKomSigLaenge" SG_ 512 AMB_TEMP_AVG 16;
BA_ "FlexKomSigName" SG_ 512 AMB_TEMP_AVG "AMB_TEMP_AVG";
BA_ "FlexKomComment" SG_ 512 AMB_TEMP_AVG "Averaged ambient temperature";
BA_ "FlexKomIsMotorola" SG_ 512 AMB_TEMP_AVG 1;
BA_ "GenSigSNA" SG_ 512 AMB_TEMP_AVG "FFFFh";
BA_ "GenSigCycleTime" SG_ 512 AMB_TEMP_VOLT 100;
BA_ "FlexKomSigStartValue" SG_ 512 AMB_TEMP_VOLT "FFh";
BA_ "GenSigStartValue" SG_ 512 AMB_TEMP_VOLT 255;
BA_ "GenSigTimeout_ORC" SG_ 512 AMB_TEMP_VOLT 350;
BA_ "FlexKomSID" SG_ 512 AMB_TEMP_VOLT 1201;
BA_ "FlexKomSigStartPos" SG_ 512 AMB_TEMP_VOLT 31;
BA_ "FlexKomSigLaenge" SG_ 512 AMB_TEMP_VOLT 8;
BA_ "FlexKomSigName" SG_ 512 AMB_TEMP_VOLT "AMB_TEMP_VOLT";
BA_ "FlexKomComment" SG_ 512 AMB_TEMP_VOLT "Ambient Temp Sensor A/D Voltage";
BA_ "FlexKomIsMotorola" SG_ 512 AMB_TEMP_VOLT 1;
BA_ "GenSigSNA" SG_ 512 AMB_TEMP_VOLT "FFh";
BA_ "GenSigCycleTime" SG_ 512 FUEL_VOLT 100;
BA_ "FlexKomSigStartValue" SG_ 512 FUEL_VOLT "FFh";
BA_ "GenSigStartValue" SG_ 512 FUEL_VOLT 255;
BA_ "GenSigTimeout_IC" SG_ 512 FUEL_VOLT 1050;
BA_ "FlexKomSID" SG_ 512 FUEL_VOLT 881;
BA_ "FlexKomSigStartPos" SG_ 512 FUEL_VOLT 39;
BA_ "FlexKomSigLaenge" SG_ 512 FUEL_VOLT 8;
BA_ "FlexKomSigName" SG_ 512 FUEL_VOLT "FUEL_VOLT";
BA_ "FlexKomComment" SG_ 512 FUEL_VOLT "Fuel level A/D Voltage (Single tank OR Primary on ";
BA_ "FlexKomIsMotorola" SG_ 512 FUEL_VOLT 1;
BA_ "GenSigSNA" SG_ 512 FUEL_VOLT "FFh";
BA_ "GenSigCycleTime" SG_ 512 FUEL_VOLT2 100;
BA_ "FlexKomSigStartValue" SG_ 512 FUEL_VOLT2 "FFh";
BA_ "GenSigStartValue" SG_ 512 FUEL_VOLT2 255;
BA_ "GenSigTimeout_IC" SG_ 512 FUEL_VOLT2 1050;
BA_ "FlexKomSID" SG_ 512 FUEL_VOLT2 882;
BA_ "FlexKomSigStartPos" SG_ 512 FUEL_VOLT2 47;
BA_ "FlexKomSigLaenge" SG_ 512 FUEL_VOLT2 8;
BA_ "FlexKomSigName" SG_ 512 FUEL_VOLT2 "FUEL_VOLT2";
BA_ "FlexKomComment" SG_ 512 FUEL_VOLT2 "Sub Side Fuel level sensor A/D Voltage (saddle/Dua";
BA_ "FlexKomIsMotorola" SG_ 512 FUEL_VOLT2 1;
BA_ "GenSigSNA" SG_ 512 FUEL_VOLT2 "FFh";
BA_ "GenSigCycleTime" SG_ 512 BATT_VOLT 100;
BA_ "FlexKomSigStartValue" SG_ 512 BATT_VOLT "FFh";
BA_ "GenSigStartValue" SG_ 512 BATT_VOLT 255;
BA_ "GenSigTimeout_RF_HUB" SG_ 512 BATT_VOLT 1050;
BA_ "GenSigTimeout_IC" SG_ 512 BATT_VOLT 1050;
BA_ "GenSigTimeout_EPS" SG_ 512 BATT_VOLT 1050;
BA_ "GenSigTimeout_SCCM" SG_ 512 BATT_VOLT 1050;
BA_ "GenSigTimeout_ESM" SG_ 512 BATT_VOLT 1050;
BA_ "GenSigTimeout_ORC" SG_ 512 BATT_VOLT 350;
BA_ "FlexKomSID" SG_ 512 BATT_VOLT 839;
BA_ "FlexKomSigStartPos" SG_ 512 BATT_VOLT 55;
BA_ "FlexKomSigLaenge" SG_ 512 BATT_VOLT 8;
BA_ "FlexKomSigName" SG_ 512 BATT_VOLT "BATT_VOLT";
BA_ "FlexKomComment" SG_ 512 BATT_VOLT "System voltage";
BA_ "FlexKomIsMotorola" SG_ 512 BATT_VOLT 1;
BA_ "GenSigSNA" SG_ 512 BATT_VOLT "FFh";
BA_ "GenSigCycleTime" SG_ 512 BATT_TEMP_VOLT 100;
BA_ "FlexKomSigStartValue" SG_ 512 BATT_TEMP_VOLT "FFh";
BA_ "GenSigStartValue" SG_ 512 BATT_TEMP_VOLT 255;
BA_ "FlexKomSID" SG_ 512 BATT_TEMP_VOLT 1202;
BA_ "FlexKomSigStartPos" SG_ 512 BATT_TEMP_VOLT 63;
BA_ "FlexKomSigLaenge" SG_ 512 BATT_TEMP_VOLT 8;
BA_ "FlexKomSigName" SG_ 512 BATT_TEMP_VOLT "BATT_TEMP_VOLT";
BA_ "FlexKomComment" SG_ 512 BATT_TEMP_VOLT "Batt. Temp Sensor A/D Voltage";
BA_ "FlexKomIsMotorola" SG_ 512 BATT_TEMP_VOLT 1;
BA_ "GenSigSNA" SG_ 512 BATT_TEMP_VOLT "FFh";
BA_ "GenSigCycleTime" SG_ 514 WheelRPM_FL 10;
BA_ "FlexKomSigStartValue" SG_ 514 WheelRPM_FL "FFFFFFFFh";
BA_ "GenSigStartValue" SG_ 514 WheelRPM_FL 65535;
BA_ "GenSigTimeout_EPS" SG_ 514 WheelRPM_FL 105;
BA_ "FlexKomSID" SG_ 514 WheelRPM_FL 2103;
BA_ "FlexKomSigStartPos" SG_ 514 WheelRPM_FL 7;
BA_ "FlexKomSigLaenge" SG_ 514 WheelRPM_FL 32;
BA_ "FlexKomSigName" SG_ 514 WheelRPM_FL "WHEEL_SPEED2";
BA_ "FlexKomComment" SG_ 514 WheelRPM_FL "ESP wheel speed";
BA_ "FlexKomIsMotorola" SG_ 514 WheelRPM_FL 1;
BA_ "GenSigSNA" SG_ 514 WheelRPM_FL "FFFFh";
BA_ "GenSigCycleTime" SG_ 514 WheelRPM_FR 10;
BA_ "FlexKomSigStartValue" SG_ 514 WheelRPM_FR "FFFFFFFFh";
BA_ "GenSigStartValue" SG_ 514 WheelRPM_FR 65535;
BA_ "GenSigTimeout_EPS" SG_ 514 WheelRPM_FR 105;
BA_ "FlexKomSID" SG_ 514 WheelRPM_FR 2103;
BA_ "FlexKomSigStartPos" SG_ 514 WheelRPM_FR 7;
BA_ "FlexKomSigLaenge" SG_ 514 WheelRPM_FR 32;
BA_ "FlexKomSigName" SG_ 514 WheelRPM_FR "WHEEL_SPEED2";
BA_ "FlexKomComment" SG_ 514 WheelRPM_FR "ESP wheel speed";
BA_ "FlexKomIsMotorola" SG_ 514 WheelRPM_FR 1;
BA_ "GenSigSNA" SG_ 514 WheelRPM_FR "FFFFh";
BA_ "GenSigSendType" SG_ 516 ControlEncodingRsp 1;
BA_ "FlexKomSigStartValue" SG_ 516 ControlEncodingRsp "00000000000000h";
BA_ "FlexKomSID" SG_ 516 ControlEncodingRsp 2110;
BA_ "FlexKomSigStartPos" SG_ 516 ControlEncodingRsp 7;
BA_ "FlexKomSigLaenge" SG_ 516 ControlEncodingRsp 56;
BA_ "FlexKomSigName" SG_ 516 ControlEncodingRsp "IMMO_CODE_RESPONSE";
BA_ "FlexKomComment" SG_ 516 ControlEncodingRsp "Immobilizer code response packet";
BA_ "FlexKomIsMotorola" SG_ 516 ControlEncodingRsp 1;
BA_ "GenSigSNA" SG_ 516 ControlEncodingRsp "0h";
BA_ "GenSigSendType" SG_ 516 MKKey1org21 1;
BA_ "FlexKomSigStartValue" SG_ 516 MKKey1org21 "00000000000000h";
BA_ "FlexKomSID" SG_ 516 MKKey1org21 2110;
BA_ "FlexKomSigStartPos" SG_ 516 MKKey1org21 7;
BA_ "FlexKomSigLaenge" SG_ 516 MKKey1org21 56;
BA_ "FlexKomSigName" SG_ 516 MKKey1org21 "IMMO_CODE_RESPONSE";
BA_ "FlexKomComment" SG_ 516 MKKey1org21 "Immobilizer code response packet";
BA_ "FlexKomIsMotorola" SG_ 516 MKKey1org21 1;
BA_ "GenSigSNA" SG_ 516 MKKey1org21 "0h";
BA_ "GenSigSendType" SG_ 516 MKKey2org22 1;
BA_ "FlexKomSigStartValue" SG_ 516 MKKey2org22 "00000000000000h";
BA_ "FlexKomSID" SG_ 516 MKKey2org22 2110;
BA_ "FlexKomSigStartPos" SG_ 516 MKKey2org22 7;
BA_ "FlexKomSigLaenge" SG_ 516 MKKey2org22 56;
BA_ "FlexKomSigName" SG_ 516 MKKey2org22 "IMMO_CODE_RESPONSE";
BA_ "FlexKomComment" SG_ 516 MKKey2org22 "Immobilizer code response packet";
BA_ "FlexKomIsMotorola" SG_ 516 MKKey2org22 1;
BA_ "GenSigSNA" SG_ 516 MKKey2org22 "0h";
BA_ "GenSigSendType" SG_ 516 MKKey_3 1;
BA_ "FlexKomSigStartValue" SG_ 516 MKKey_3 "00000000000000h";
BA_ "FlexKomSID" SG_ 516 MKKey_3 2110;
BA_ "FlexKomSigStartPos" SG_ 516 MKKey_3 7;
BA_ "FlexKomSigLaenge" SG_ 516 MKKey_3 56;
BA_ "FlexKomSigName" SG_ 516 MKKey_3 "IMMO_CODE_RESPONSE";
BA_ "FlexKomComment" SG_ 516 MKKey_3 "Immobilizer code response packet";
BA_ "FlexKomIsMotorola" SG_ 516 MKKey_3 1;
BA_ "GenSigSNA" SG_ 516 MKKey_3 "0h";
BA_ "GenSigSendType" SG_ 516 MKKey_4 1;
BA_ "FlexKomSigStartValue" SG_ 516 MKKey_4 "00000000000000h";
BA_ "FlexKomSID" SG_ 516 MKKey_4 2110;
BA_ "FlexKomSigStartPos" SG_ 516 MKKey_4 7;
BA_ "FlexKomSigLaenge" SG_ 516 MKKey_4 56;
BA_ "FlexKomSigName" SG_ 516 MKKey_4 "IMMO_CODE_RESPONSE";
BA_ "FlexKomComment" SG_ 516 MKKey_4 "Immobilizer code response packet";
BA_ "FlexKomIsMotorola" SG_ 516 MKKey_4 1;
BA_ "GenSigSNA" SG_ 516 MKKey_4 "0h";
BA_ "GenSigSendType" SG_ 516 MKKey_5 1;
BA_ "FlexKomSigStartValue" SG_ 516 MKKey_5 "00000000000000h";
BA_ "FlexKomSID" SG_ 516 MKKey_5 2110;
BA_ "FlexKomSigStartPos" SG_ 516 MKKey_5 7;
BA_ "FlexKomSigLaenge" SG_ 516 MKKey_5 56;
BA_ "FlexKomSigName" SG_ 516 MKKey_5 "IMMO_CODE_RESPONSE";
BA_ "FlexKomComment" SG_ 516 MKKey_5 "Immobilizer code response packet";
BA_ "FlexKomIsMotorola" SG_ 516 MKKey_5 1;
BA_ "GenSigSNA" SG_ 516 MKKey_5 "0h";
BA_ "GenSigSendType" SG_ 516 MKKey_6 1;
BA_ "FlexKomSigStartValue" SG_ 516 MKKey_6 "00000000000000h";
BA_ "FlexKomSID" SG_ 516 MKKey_6 2110;
BA_ "FlexKomSigStartPos" SG_ 516 MKKey_6 7;
BA_ "FlexKomSigLaenge" SG_ 516 MKKey_6 56;
BA_ "FlexKomSigName" SG_ 516 MKKey_6 "IMMO_CODE_RESPONSE";
BA_ "FlexKomComment" SG_ 516 MKKey_6 "Immobilizer code response packet";
BA_ "FlexKomIsMotorola" SG_ 516 MKKey_6 1;
BA_ "GenSigSNA" SG_ 516 MKKey_6 "0h";
BA_ "GenSigSendType" SG_ 517 ControlEncodingRq 1;
BA_ "FlexKomSigStartValue" SG_ 517 ControlEncodingRq "00000000000000h";
BA_ "FlexKomSID" SG_ 517 ControlEncodingRq 2111;
BA_ "FlexKomSigStartPos" SG_ 517 ControlEncodingRq 7;
BA_ "FlexKomSigLaenge" SG_ 517 ControlEncodingRq 56;
BA_ "FlexKomSigName" SG_ 517 ControlEncodingRq "IMMO_CODE_REQUEST";
BA_ "FlexKomComment" SG_ 517 ControlEncodingRq "Immobilizer code request packet";
BA_ "FlexKomIsMotorola" SG_ 517 ControlEncodingRq 1;
BA_ "GenSigSNA" SG_ 517 ControlEncodingRq "0h";
BA_ "GenSigSendType" SG_ 517 rnd_1 1;
BA_ "FlexKomSigStartValue" SG_ 517 rnd_1 "00000000000000h";
BA_ "FlexKomSID" SG_ 517 rnd_1 2111;
BA_ "FlexKomSigStartPos" SG_ 517 rnd_1 7;
BA_ "FlexKomSigLaenge" SG_ 517 rnd_1 56;
BA_ "FlexKomSigName" SG_ 517 rnd_1 "IMMO_CODE_REQUEST";
BA_ "FlexKomComment" SG_ 517 rnd_1 "Immobilizer code request packet";
BA_ "FlexKomIsMotorola" SG_ 517 rnd_1 1;
BA_ "GenSigSNA" SG_ 517 rnd_1 "0h";
BA_ "GenSigSendType" SG_ 517 rnd_2 1;
BA_ "FlexKomSigStartValue" SG_ 517 rnd_2 "00000000000000h";
BA_ "FlexKomSID" SG_ 517 rnd_2 2111;
BA_ "FlexKomSigStartPos" SG_ 517 rnd_2 7;
BA_ "FlexKomSigLaenge" SG_ 517 rnd_2 56;
BA_ "FlexKomSigName" SG_ 517 rnd_2 "IMMO_CODE_REQUEST";
BA_ "FlexKomComment" SG_ 517 rnd_2 "Immobilizer code request packet";
BA_ "FlexKomIsMotorola" SG_ 517 rnd_2 1;
BA_ "GenSigSNA" SG_ 517 rnd_2 "0h";
BA_ "GenSigSendType" SG_ 517 rnd_3 1;
BA_ "FlexKomSigStartValue" SG_ 517 rnd_3 "00000000000000h";
BA_ "FlexKomSID" SG_ 517 rnd_3 2111;
BA_ "FlexKomSigStartPos" SG_ 517 rnd_3 7;
BA_ "FlexKomSigLaenge" SG_ 517 rnd_3 56;
BA_ "FlexKomSigName" SG_ 517 rnd_3 "IMMO_CODE_REQUEST";
BA_ "FlexKomComment" SG_ 517 rnd_3 "Immobilizer code request packet";
BA_ "FlexKomIsMotorola" SG_ 517 rnd_3 1;
BA_ "GenSigSNA" SG_ 517 rnd_3 "0h";
BA_ "GenSigSendType" SG_ 517 rnd_4 1;
BA_ "FlexKomSigStartValue" SG_ 517 rnd_4 "00000000000000h";
BA_ "FlexKomSID" SG_ 517 rnd_4 2111;
BA_ "FlexKomSigStartPos" SG_ 517 rnd_4 7;
BA_ "FlexKomSigLaenge" SG_ 517 rnd_4 56;
BA_ "FlexKomSigName" SG_ 517 rnd_4 "IMMO_CODE_REQUEST";
BA_ "FlexKomComment" SG_ 517 rnd_4 "Immobilizer code request packet";
BA_ "FlexKomIsMotorola" SG_ 517 rnd_4 1;
BA_ "GenSigSNA" SG_ 517 rnd_4 "0h";
BA_ "GenSigSendType" SG_ 517 f1_1 1;
BA_ "FlexKomSigStartValue" SG_ 517 f1_1 "00000000000000h";
BA_ "FlexKomSID" SG_ 517 f1_1 2111;
BA_ "FlexKomSigStartPos" SG_ 517 f1_1 7;
BA_ "FlexKomSigLaenge" SG_ 517 f1_1 56;
BA_ "FlexKomSigName" SG_ 517 f1_1 "IMMO_CODE_REQUEST";
BA_ "FlexKomComment" SG_ 517 f1_1 "Immobilizer code request packet";
BA_ "FlexKomIsMotorola" SG_ 517 f1_1 1;
BA_ "GenSigSNA" SG_ 517 f1_1 "0h";
BA_ "GenSigSendType" SG_ 517 f1_2 1;
BA_ "FlexKomSigStartValue" SG_ 517 f1_2 "00000000000000h";
BA_ "FlexKomSID" SG_ 517 f1_2 2111;
BA_ "FlexKomSigStartPos" SG_ 517 f1_2 7;
BA_ "FlexKomSigLaenge" SG_ 517 f1_2 56;
BA_ "FlexKomSigName" SG_ 517 f1_2 "IMMO_CODE_REQUEST";
BA_ "FlexKomComment" SG_ 517 f1_2 "Immobilizer code request packet";
BA_ "FlexKomIsMotorola" SG_ 517 f1_2 1;
BA_ "GenSigSNA" SG_ 517 f1_2 "0h";
BA_ "GenSigCycleTime" SG_ 520 DriverDoorAjarXtionSts 20;
BA_ "FlexKomSigStartValue" SG_ 520 DriverDoorAjarXtionSts "3FFF0C0000000000h";
BA_ "GenSigStartValue" SG_ 520 DriverDoorAjarXtionSts 3;
BA_ "FlexKomSID" SG_ 520 DriverDoorAjarXtionSts 1943;
BA_ "FlexKomSigStartPos" SG_ 520 DriverDoorAjarXtionSts 7;
BA_ "FlexKomSigLaenge" SG_ 520 DriverDoorAjarXtionSts 64;
BA_ "FlexKomSigName" SG_ 520 DriverDoorAjarXtionSts "CBC_PT6_Pkt";
BA_ "FlexKomComment" SG_ 520 DriverDoorAjarXtionSts "CBC_PT6 message packet";
BA_ "FlexKomIsMotorola" SG_ 520 DriverDoorAjarXtionSts 1;
BA_ "GenSigSNA" SG_ 520 DriverDoorAjarXtionSts "3h";
BA_ "GenSigCycleTime" SG_ 520 PsngrDoorAjarXtionSts 20;
BA_ "FlexKomSigStartValue" SG_ 520 PsngrDoorAjarXtionSts "3FFF0C0000000000h";
BA_ "GenSigStartValue" SG_ 520 PsngrDoorAjarXtionSts 3;
BA_ "FlexKomSID" SG_ 520 PsngrDoorAjarXtionSts 1943;
BA_ "FlexKomSigStartPos" SG_ 520 PsngrDoorAjarXtionSts 7;
BA_ "FlexKomSigLaenge" SG_ 520 PsngrDoorAjarXtionSts 64;
BA_ "FlexKomSigName" SG_ 520 PsngrDoorAjarXtionSts "CBC_PT6_Pkt";
BA_ "FlexKomComment" SG_ 520 PsngrDoorAjarXtionSts "CBC_PT6 message packet";
BA_ "FlexKomIsMotorola" SG_ 520 PsngrDoorAjarXtionSts 1;
BA_ "GenSigSNA" SG_ 520 PsngrDoorAjarXtionSts "3h";
BA_ "GenSigCycleTime" SG_ 520 DriverDoor2AjarXtionSts 20;
BA_ "FlexKomSigStartValue" SG_ 520 DriverDoor2AjarXtionSts "3FFF0C0000000000h";
BA_ "GenSigStartValue" SG_ 520 DriverDoor2AjarXtionSts 3;
BA_ "FlexKomSID" SG_ 520 DriverDoor2AjarXtionSts 1943;
BA_ "FlexKomSigStartPos" SG_ 520 DriverDoor2AjarXtionSts 7;
BA_ "FlexKomSigLaenge" SG_ 520 DriverDoor2AjarXtionSts 64;
BA_ "FlexKomSigName" SG_ 520 DriverDoor2AjarXtionSts "CBC_PT6_Pkt";
BA_ "FlexKomComment" SG_ 520 DriverDoor2AjarXtionSts "CBC_PT6 message packet";
BA_ "FlexKomIsMotorola" SG_ 520 DriverDoor2AjarXtionSts 1;
BA_ "GenSigSNA" SG_ 520 DriverDoor2AjarXtionSts "3h";
BA_ "GenSigCycleTime" SG_ 520 AC_OutptCurrStat 20;
BA_ "FlexKomSigStartValue" SG_ 520 AC_OutptCurrStat "3FFF0C0000000000h";
BA_ "GenSigStartValue" SG_ 520 AC_OutptCurrStat 255;
BA_ "FlexKomSID" SG_ 520 AC_OutptCurrStat 1943;
BA_ "FlexKomSigStartPos" SG_ 520 AC_OutptCurrStat 7;
BA_ "FlexKomSigLaenge" SG_ 520 AC_OutptCurrStat 64;
BA_ "FlexKomSigName" SG_ 520 AC_OutptCurrStat "CBC_PT6_Pkt";
BA_ "FlexKomComment" SG_ 520 AC_OutptCurrStat "CBC_PT6 message packet";
BA_ "FlexKomIsMotorola" SG_ 520 AC_OutptCurrStat 1;
BA_ "GenSigSNA" SG_ 520 AC_OutptCurrStat "FFh";
BA_ "GenSigCycleTime" SG_ 520 BrkPdlStat_CBC 20;
BA_ "FlexKomSigStartValue" SG_ 520 BrkPdlStat_CBC "3FFF0C0000000000h";
BA_ "GenSigStartValue" SG_ 520 BrkPdlStat_CBC 3;
BA_ "GenSigTimeout_RF_HUB" SG_ 520 BrkPdlStat_CBC 210;
BA_ "FlexKomSID" SG_ 520 BrkPdlStat_CBC 1943;
BA_ "FlexKomSigStartPos" SG_ 520 BrkPdlStat_CBC 7;
BA_ "FlexKomSigLaenge" SG_ 520 BrkPdlStat_CBC 64;
BA_ "FlexKomSigName" SG_ 520 BrkPdlStat_CBC "CBC_PT6_Pkt";
BA_ "FlexKomComment" SG_ 520 BrkPdlStat_CBC "CBC_PT6 message packet";
BA_ "FlexKomIsMotorola" SG_ 520 BrkPdlStat_CBC 1;
BA_ "GenSigSNA" SG_ 520 BrkPdlStat_CBC "3h";
BA_ "GenSigCycleTime" SG_ 520 FOB_SrchLoc 20;
BA_ "FlexKomSigStartValue" SG_ 520 FOB_SrchLoc "3FFF0C0000000000h";
BA_ "GenSigTimeout_RF_HUB" SG_ 520 FOB_SrchLoc 110;
BA_ "FlexKomSID" SG_ 520 FOB_SrchLoc 1943;
BA_ "FlexKomSigStartPos" SG_ 520 FOB_SrchLoc 7;
BA_ "FlexKomSigLaenge" SG_ 520 FOB_SrchLoc 64;
BA_ "FlexKomSigName" SG_ 520 FOB_SrchLoc "CBC_PT6_Pkt";
BA_ "FlexKomComment" SG_ 520 FOB_SrchLoc "CBC_PT6 message packet";
BA_ "FlexKomIsMotorola" SG_ 520 FOB_SrchLoc 1;
BA_ "GenSigSNA" SG_ 520 FOB_SrchLoc "Fh";
BA_ "GenSigCycleTime" SG_ 520 DriverDoorAjarRawValSts 20;
BA_ "FlexKomSigStartValue" SG_ 520 DriverDoorAjarRawValSts "3FFF0C0000000000h";
BA_ "GenSigTimeout_ORC" SG_ 520 DriverDoorAjarRawValSts 70;
BA_ "FlexKomSID" SG_ 520 DriverDoorAjarRawValSts 1943;
BA_ "FlexKomSigStartPos" SG_ 520 DriverDoorAjarRawValSts 7;
BA_ "FlexKomSigLaenge" SG_ 520 DriverDoorAjarRawValSts 64;
BA_ "FlexKomSigName" SG_ 520 DriverDoorAjarRawValSts "CBC_PT6_Pkt";
BA_ "FlexKomComment" SG_ 520 DriverDoorAjarRawValSts "CBC_PT6 message packet";
BA_ "FlexKomIsMotorola" SG_ 520 DriverDoorAjarRawValSts 1;
BA_ "GenSigSNA" SG_ 520 DriverDoorAjarRawValSts "Fh";
BA_ "GenSigCycleTime" SG_ 520 PsngrDoorAjarRawValSts 20;
BA_ "FlexKomSigStartValue" SG_ 520 PsngrDoorAjarRawValSts "3FFF0C0000000000h";
BA_ "GenSigTimeout_ORC" SG_ 520 PsngrDoorAjarRawValSts 70;
BA_ "FlexKomSID" SG_ 520 PsngrDoorAjarRawValSts 1943;
BA_ "FlexKomSigStartPos" SG_ 520 PsngrDoorAjarRawValSts 7;
BA_ "FlexKomSigLaenge" SG_ 520 PsngrDoorAjarRawValSts 64;
BA_ "FlexKomSigName" SG_ 520 PsngrDoorAjarRawValSts "CBC_PT6_Pkt";
BA_ "FlexKomComment" SG_ 520 PsngrDoorAjarRawValSts "CBC_PT6 message packet";
BA_ "FlexKomIsMotorola" SG_ 520 PsngrDoorAjarRawValSts 1;
BA_ "GenSigSNA" SG_ 520 PsngrDoorAjarRawValSts "Fh";
BA_ "GenSigCycleTime" SG_ 520 DriverDoor2AjarRawValSts 20;
BA_ "FlexKomSigStartValue" SG_ 520 DriverDoor2AjarRawValSts "3FFF0C0000000000h";
BA_ "FlexKomSID" SG_ 520 DriverDoor2AjarRawValSts 1943;
BA_ "FlexKomSigStartPos" SG_ 520 DriverDoor2AjarRawValSts 7;
BA_ "FlexKomSigLaenge" SG_ 520 DriverDoor2AjarRawValSts 64;
BA_ "FlexKomSigName" SG_ 520 DriverDoor2AjarRawValSts "CBC_PT6_Pkt";
BA_ "FlexKomComment" SG_ 520 DriverDoor2AjarRawValSts "CBC_PT6 message packet";
BA_ "FlexKomIsMotorola" SG_ 520 DriverDoor2AjarRawValSts 1;
BA_ "GenSigSNA" SG_ 520 DriverDoor2AjarRawValSts "Fh";
BA_ "GenSigCycleTime" SG_ 520 BonnetAjarRawValSts 20;
BA_ "FlexKomSigStartValue" SG_ 520 BonnetAjarRawValSts "3FFF0C0000000000h";
BA_ "GenSigTimeout_ORC" SG_ 520 BonnetAjarRawValSts 70;
BA_ "FlexKomSID" SG_ 520 BonnetAjarRawValSts 1943;
BA_ "FlexKomSigStartPos" SG_ 520 BonnetAjarRawValSts 7;
BA_ "FlexKomSigLaenge" SG_ 520 BonnetAjarRawValSts 64;
BA_ "FlexKomSigName" SG_ 520 BonnetAjarRawValSts "CBC_PT6_Pkt";
BA_ "FlexKomComment" SG_ 520 BonnetAjarRawValSts "CBC_PT6 message packet";
BA_ "FlexKomIsMotorola" SG_ 520 BonnetAjarRawValSts 1;
BA_ "GenSigSNA" SG_ 520 BonnetAjarRawValSts "Fh";
BA_ "GenSigSendType" SG_ 528 PsgSeatOCSts 5;
BA_ "GenSigCycleTime" SG_ 528 PsgSeatOCSts 1000;
BA_ "FlexKomSigStartValue" SG_ 528 PsgSeatOCSts "0F0Fh";
BA_ "GenSigStartValue" SG_ 528 PsgSeatOCSts 15;
BA_ "GenSigTimeout_ORC" SG_ 528 PsgSeatOCSts 3500;
BA_ "FlexKomSID" SG_ 528 PsgSeatOCSts 1586;
BA_ "FlexKomSigStartPos" SG_ 528 PsgSeatOCSts 7;
BA_ "FlexKomSigLaenge" SG_ 528 PsgSeatOCSts 16;
BA_ "FlexKomSigName" SG_ 528 PsgSeatOCSts "OC_P_Stat";
BA_ "FlexKomComment" SG_ 528 PsgSeatOCSts "Passenger occupant classification system status";
BA_ "FlexKomIsMotorola" SG_ 528 PsgSeatOCSts 1;
BA_ "GenSigSNA" SG_ 528 PsgSeatOCSts "Fh";
BA_ "GenSigSendType" SG_ 528 PsgSeatOCFaultSts 5;
BA_ "GenSigCycleTime" SG_ 528 PsgSeatOCFaultSts 1000;
BA_ "FlexKomSigStartValue" SG_ 528 PsgSeatOCFaultSts "0F0Fh";
BA_ "GenSigTimeout_ORC" SG_ 528 PsgSeatOCFaultSts 3500;
BA_ "FlexKomSID" SG_ 528 PsgSeatOCFaultSts 1586;
BA_ "FlexKomSigStartPos" SG_ 528 PsgSeatOCFaultSts 7;
BA_ "FlexKomSigLaenge" SG_ 528 PsgSeatOCFaultSts 16;
BA_ "FlexKomSigName" SG_ 528 PsgSeatOCFaultSts "OC_P_Stat";
BA_ "FlexKomComment" SG_ 528 PsgSeatOCFaultSts "Passenger occupant classification system status";
BA_ "FlexKomIsMotorola" SG_ 528 PsgSeatOCFaultSts 1;
BA_ "GenSigSNA" SG_ 528 PsgSeatOCFaultSts "0h";
BA_ "GenSigSendType" SG_ 528 PsgSeatSBRSts 5;
BA_ "GenSigCycleTime" SG_ 528 PsgSeatSBRSts 1000;
BA_ "FlexKomSigStartValue" SG_ 528 PsgSeatSBRSts "0F0Fh";
BA_ "GenSigStartValue" SG_ 528 PsgSeatSBRSts 15;
BA_ "GenSigTimeout_ORC" SG_ 528 PsgSeatSBRSts 3500;
BA_ "FlexKomSID" SG_ 528 PsgSeatSBRSts 1586;
BA_ "FlexKomSigStartPos" SG_ 528 PsgSeatSBRSts 7;
BA_ "FlexKomSigLaenge" SG_ 528 PsgSeatSBRSts 16;
BA_ "FlexKomSigName" SG_ 528 PsgSeatSBRSts "OC_P_Stat";
BA_ "FlexKomComment" SG_ 528 PsgSeatSBRSts "Passenger occupant classification system status";
BA_ "FlexKomIsMotorola" SG_ 528 PsgSeatSBRSts 1;
BA_ "GenSigSNA" SG_ 528 PsgSeatSBRSts "Fh";
VAL_ 368 PaddlesModeSts 3 "SNA" 2 "EN" 1 "DIS" 0 "NONE" ;
VAL_ 368 PRND_STAT 7 "SNA" 5 "NOT_R" 4 "LVR_D" 2 "LVR_N" 1 "LVR_R" 0 "LVR_P" ;
VAL_ 368 APCM_Rq 3 "SNA" 2 "PENDING" 1 "ON" 0 "OFF" ;
VAL_ 368 SHFT_PROG 255 "SNA" 254 "TX_TOW" 253 "OD_OFF" 252 "TX_NORM" 251 "TX_SPORT" 250 "Sport_Plus" 87 "W" 83 "S" 77 "M" 65 "A" 64 "E_MODE" 32 "BLANK" 24 "UPSHIFT_IND_RQ" 16 "SKIP_SHFT" 5 "VALET" 4 "TRACK" 3 "HDC" 2 "SSC" 1 "LOW" ;
VAL_ 368 PRNDL_DISP 255 "SNA" 254 "NOT_N" 135 "SNOW" 133 "D5" 132 "D4" 131 "D3" 130 "D2" 128 "DS" 83 "S" 82 "R" 80 "P" 78 "N" 77 "M" 76 "L" 70 "F" 68 "D" 65 "A" 57 "NINE" 56 "EIGHT" 55 "SEVEN" 54 "SIX" 53 "FIVE" 52 "FOUR" 51 "THREE" 50 "TWO" 49 "ONE" 32 "BLANK" ;
VAL_ 368 PRNDL_Blink 7 "M_TIP" 6 "S" 5 "L" 4 "D" 3 "N" 2 "R" 1 "P" 0 "NONE" ;
VAL_ 376 FAN_RQ 15 "SNA" ;
VAL_ 376 TX_TEMP 255 "SNA" ;
VAL_ 376 TX_WARN 15 "SNA" 14 "WARN_14" 13 "WARN_13" 12 "WARN_12" 11 "WARN_11" 10 "WARN_10" 9 "WARN_9" 8 "WARN_8" 7 "WARN_7" 6 "WARN_6" 5 "WARN_5" 4 "WARN_4" 3 "WARN_3" 2 "WARN_2" 1 "WARN_1" 0 "None" ;
VAL_ 376 TX_FAULT 3 "SNA" 1 "TPF" 0 "OK" ;
VAL_ 376 TRNS_StpSt_FLT 1 "SNA" ;
VAL_ 384 IntkAirTemp 255 "SNA" ;
VAL_ 384 EngCoolTemp 255 "SNA" ;
VAL_ 384 AirPress_Outsd 255 "SNA" ;
VAL_ 384 TgtVolt 255 "SNA" ;
VAL_ 384 SysVolt 255 "SNA" ;
VAL_ 384 R134a_Press_Stat 511 "SNA" ;
VAL_ 384 CHRG_FAIL 1 "SNA" ;
VAL_ 384 AM_ECM_Prsnt 3 "SNA" 2 "AM_ECM_PRSNT" 0 "DEFAULT" ;
VAL_ 384 AC_OUTPUT_DC_FINAL 255 "SNA" ;
VAL_ 388 CustKeyInIgn 3 "SNA" 2 "CUST_KEY_IN_IGNITION" 1 "CUST_KEY_NOT_IN_IGNITION" 0 "CUST_KEY_DEFAULT" ;
VAL_ 388 IgnPos 7 "SNA" 5 "IGN_START" 4 "IGN_RUN" 3 "IGN_OFF_ACC" 2 "IGN_ACC" 1 "IGN_OFF" 0 "IGN_LK" ;
VAL_ 388 ValImmKey 3 "SNA" 1 "CUST_IMMOB_KEY_VALID" 0 "CUST_IMMOB_KEY_DEFAULT" ;
VAL_ 388 AuthCode 65535 "SNA" ;
VAL_ 416 Trans_Trq_Ratio 2047 "SNA" ;
VAL_ 416 TxIdleRq 255 "SNA" ;
VAL_ 416 EngTrq_Rq_TCM 8191 "SNA" ;
VAL_ 436 BrkTrq_Rq_DAS 4095 "SNA" ;
VAL_ 436 AS_Brk 7 "SNA" 4 "LSCM" 3 "ABA" 2 "CMS" 1 "ACC" 0 "IDLE" ;
VAL_ 436 SpLmpSprsn 0 "SNA" ;
VAL_ 436 GrMax_Rq_DAS 7 "G7" 6 "G6" 5 "G5" 4 "G4" 3 "G3" 2 "G2" 1 "G1" 0 "PASSIVE" ;
VAL_ 436 GrMin_Rq_DAS 7 "G7" 6 "G6" 5 "G5" 4 "G4" 3 "G3" 2 "G2" 1 "G1" 0 "PASSIVE" ;
VAL_ 436 EngTrq_Rq_DAS 8191 "SNA" ;
VAL_ 436 SPCR_Md_Rq_DAS 3 "SNA" 2 "HOLD" 1 "GO" 0 "IDLE" ;
VAL_ 448 RFFuncReq 31 "SNA" 20 "GLBL_WIN_UP_RQ" 19 "AirSuspCancel" 18 "AirSuspReq" 17 "ExtLightReq" 16 "PASSENGER_TOGGLE_REQUEST" 15 "DRIVER_TOGGLE_REQUEST" 14 "PANIC_TOGGLE_REQUEST" 13 "CLOSE_CONVERTIBLE_TOP" 12 "OPEN_CONVERTIBLE_TOP" 11 "GLOBAL_WINDOW_DOWN_REQUEST" 10 "REMOTE_START_OFF" 9 "REMOTE_START_ON" 8 "FLIPPER_GLASS_REQUEST" 7 "RIGHT_SLIDER_TOGGLE_REQUEST" 6 "LEFT_SLIDER_TOGGLE_REQUEST" 5 "TRUNK_PLG_TOGGLE_REQUEST" 4 "ALL_UNLOCK_REQUEST" 3 "DRIVER_UNLOCK_REQUEST" 2 "RELOCK_REQUEST" 1 "LOCK_REQUEST" 0 "NO_BASIC_REQUEST" ;
VAL_ 448 RFReq 7 "SNA" 4 "REQUESTOR_UCONNECT" 3 "REQUESTOR_REMOTESTART" 2 "REQUESTOR_PE" 1 "REQUESTOR_RKE" 0 "REQUESTOR_DEFAULT" ;
VAL_ 448 RFAuthCode 65535 "SNA" ;
VAL_ 448 RFCfgReq 7 "SNA" 3 "DRIVER_UNLOCK_FIRST_TOGGLE" 2 "OPTICAL_CHIRP_TOGGLE" 1 "HORN_CHIRP_TOGGLE" 0 "DEFAULT" ;
VAL_ 448 RFFobNum 15 "SNA" 8 "FOB_8" 7 "FOB_7" 6 "FOB_6" 5 "FOB_5" 4 "FOB_4" 3 "FOB_3" 2 "FOB_2" 1 "FOB_1" 0 "FOB_DEFAULT" ;
VAL_ 448 ImmStat 3 "SNA" 1 "IMMOB_STATUS_ACTIVE" 0 "IMMOB_STATUS_DEFAULT" ;
VAL_ 448 ImmChmReq 3 "SNA" 1 "IMMOB_CHIME_ACTIVE" 0 "IMMOB_CHIME_DEFAULT" ;
VAL_ 448 ImmHMIReq 7 "SNA" 5 "LGT_ON" 4 "LGT_FAST_BLNK" 3 "LGT_MED_BLNK" 2 "LGT_SLOW_BLNK" 1 "LGT_OFF" 0 "LGT_DEFAULT" ;
VAL_ 448 PE_BASIC_RQ 15 "SNA" 4 "PE_RR_UNLCH" 3 "PE_UNLK_ALL" 2 "PE_UNLK_DRV" 1 "PE_LK_RQ" 0 "PE_NO_RQ" ;
VAL_ 448 KeyProgramSts 15 "SNA" 12 "KEY_NOT_PROG" 11 "BTN_DLY_INACT" 10 "BTN_DLY_ACT" 9 "SRV_SKREEM" 8 "RKE_BATT_LO" 7 "EXCD_KEY" 6 "INV_KEY" 5 "DMG_KEY" 4 "KEY_PROG" 3 "EX_KEY_PROG" 2 "PROG_ACT" 1 "EN_KEY_PROG" 0 "RKE_NORM_STAT" ;
VAL_ 456 VTA_STAT 7 "SNA" 6 "VTA_ITM_Alarm" 5 "VTA_TAMP" 4 "VTA_LGT_HORN" 3 "VTA_LGT" 2 "VTA_ARM" 1 "VTA_PREARM" 0 "VTA_DISARM" ;
VAL_ 456 VTA_AUTH 0 "SNA" ;
VAL_ 464 SRS_IndLmp_Rq 3 "SNA" 2 "BLINK" 1 "CONT" 0 "OFF" ;
VAL_ 464 PsngrBagSts 3 "SNA" 2 "LAMP_ON" 1 "LAMP_BLINK" 0 "LAMP_OFF" ;
VAL_ 464 OC_P_ORC 7 "SNA" 5 "CLASS5" 4 "CLASS4" 3 "CLASS3" 2 "CLASS2" 1 "CLASS1" 0 "CLASS0" ;
VAL_ 464 DrvSbltUnFltr 7 "SNA" 3 "HIGH" 2 "LOW" 1 "UNBUCKLED" 0 "BUCKLED" ;
VAL_ 464 DRV_SEATBELT 3 "SNA" 2 "SEATBELT_FAIL" 1 "DRV_SEATBELT_NOK" 0 "DRV_SEATBELT_OK" ;
VAL_ 464 PSG_SEATBELT 3 "SNA" 2 "SEATBELT_FAIL" 1 "PSG_SEATBELT_NOK" 0 "PSG_SEATBELT_OK" ;
VAL_ 464 OC_P_Fast_ORC 3 "SNA" 2 "FAULT" 1 "PSG_ABSENT" 0 "PSG_PRESENT" ;
VAL_ 464 PSG_ODS_STAT 3 "SNA" 2 "ODS_FAULT" 1 "ODS_STAT_OCC" 0 "ODS_STAT_NOCC" ;
VAL_ 464 COD_Stat 7 "SNA" 4 "FLT" 3 "WRONG_POS" 2 "RWD" 1 "FWD" 0 "NO_SEAT" ;
VAL_ 468 As_Disp_Rq 3 "SNA" 2 "CMS" 1 "ACC" 0 "DEFAULT" ;
VAL_ 468 DTR_Dspl_TmGap 3 "SNA" 2 "HW3" 1 "HW2" 0 "HW1" ;
VAL_ 468 Dist_D_Dsr 255 "SNA" ;
VAL_ 468 ObjIntrst_Dist 255 "SNA" ;
VAL_ 468 Sys_Dsbl 7 "ACC_BlwMinSpd" 6 "ACC_Waiting" 5 "ESCENB_ACCREADY" 4 "ACCDSB_BELOWSPD" 3 "ACCDSB_PARKBRK" 2 "ACCDSB_ESCOFF" 1 "ACCDSB_SEATBLT" 0 "DEFAULT" ;
VAL_ 468 FCW_Stat 1 "SNA" ;
VAL_ 468 DTR_Spd_Dsr 255 "SNA" ;
VAL_ 468 DTR_FltDisp_Rq 15 "SNA" 8 "LCM_ALIGN" 7 "LCM_DSBL" 6 "LCM_PLANTMODE" 5 "LCM_INACTIVE" 4 "LCM_PC" 3 "LCM_ExtFail" 2 "LCM_LMTD" 1 "LCM_IntFail" 0 "LCM_OK" ;
VAL_ 480 SBR2RowCentralSeatSts 3 "SNA" 2 "SEATBELT_FAIL" 1 "PSG_SEATBELT_NOK" 0 "PSG_SEATBELT_OK" ;
VAL_ 480 SBR2RowLeftSeatSts 3 "SNA" 2 "SEATBELT_FAIL" 1 "PSG_SEATBELT_NOK" 0 "PSG_SEATBELT_OK" ;
VAL_ 480 SBR2RowRightSeatSts 3 "SNA" 2 "SEATBELT_FAIL" 1 "PSG_SEATBELT_NOK" 0 "PSG_SEATBELT_OK" ;
VAL_ 480 SBR3RowCentralSeatSts 3 "SNA" 2 "SEATBELT_FAIL" 1 "PSG_SEATBELT_NOK" 0 "PSG_SEATBELT_OK" ;
VAL_ 480 SBR3RowLeftSeatSts 3 "SNA" 2 "SEATBELT_FAIL" 1 "PSG_SEATBELT_NOK" 0 "PSG_SEATBELT_OK" ;
VAL_ 480 SBR3RowRightSeatSts 3 "SNA" 2 "SEATBELT_FAIL" 1 "PSG_SEATBELT_NOK" 0 "PSG_SEATBELT_OK" ;
VAL_ 500 EngTrqRq_DAS 8191 "SNA" ;
VAL_ 500 DAS_ACCEL_Rq 4095 "SNA" ;
VAL_ 500 GrMax_RqDAS 12 "G12" 11 "G11" 10 "G10" 9 "G9" 8 "G8" 7 "G7" 6 "G6" 5 "G5" 4 "G4" 3 "G3" 2 "G2" 1 "G1" 0 "PASSIVE" ;
VAL_ 500 DAS_Rq_ID 7 "SNA" 4 "LSCM" 3 "ABA" 2 "CMS" 1 "ACC" 0 "IDLE" ;
VAL_ 500 AS_ChimeTyp 15 "SNA" 14 "TYP_14" 13 "TYP_13" 12 "TYP_12" 11 "TYP_11" 10 "TYP_10" 9 "TYP_9" 8 "TYP_8" 7 "TYP_7" 6 "TYP_6" 5 "TYP_5" 4 "TYP_4" 3 "TYP_3" 2 "TYP_2" 1 "TYP_1" 0 "NONE" ;
VAL_ 500 DAS_Sts 3 "SNA" 2 "EXTERNAL" 1 "INTERNAL" 0 "OK" ;
VAL_ 500 As_DispRq 3 "SNA" 2 "FCW" 1 "ACC" 0 "No_RQ" ;
VAL_ 501 HMI_Screens 255 "SNA" ;
VAL_ 501 SetSpeed_KPH 255 "SNA" ;
VAL_ 501 SetSpeed_MPH 255 "SNA" ;
VAL_ 501 FCW_Off 3 "SNA" 2 "BLINK" 1 "CONT" 0 "OFF" ;
VAL_ 501 FCW_Error 3 "SNA" 2 "Limited_FCW" 1 "FCW_Error" 0 "No_Error" ;
VAL_ 501 ISO_Display 15 "SNA" 7 "N_A_Error" 6 "NCC_EngdISO" 5 "NCC_ReadyISO" 3 "ACC_Error" 2 "ACC_EngdISO" 1 "ACC_ReadyISO" 0 "DASM_ISOOFF" ;
VAL_ 501 ACCOnOff 7 "SNA" 4 "ACC_SET" 3 "ACC_ON" 2 "NCC_SET" 1 "NCC" 0 "OFF" ;
VAL_ 501 Sm_ICON_Dspl 63 "SNA" 40 "NCC_ENGAGED" 34 "NCC_READY" 33 "NCC_OFF" 15 "ACC_E_WT_TG4" 14 "ACC_E_WT_TG3" 13 "ACC_E_WT_TG2" 12 "ACC_E_WT_TG1" 11 "ACC_E_NT_TG4" 10 "ACC_E_NT_TG3" 9 "ACC_E_NT_TG2" 8 "ACC_E_NT_TG1" 5 "READY_TG4" 4 "READY_TG3" 3 "READY_TG2" 2 "READY_TG1" 1 "OFF" 0 "NONE" ;
VAL_ 501 ObjIntrstDist 255 "SNA" ;
VAL_ 512 AirTemp_Outsd 255 "SNA" ;
VAL_ 512 AMB_TEMP_AVG 65535 "SNA" ;
VAL_ 512 AMB_TEMP_VOLT 255 "SNA" ;
VAL_ 512 FUEL_VOLT 255 "SNA" ;
VAL_ 512 FUEL_VOLT2 255 "SNA" ;
VAL_ 512 BATT_VOLT 255 "SNA" ;
VAL_ 512 BATT_TEMP_VOLT 255 "SNA" ;
VAL_ 514 WheelRPM_FL 65535 "SNA" ;
VAL_ 514 WheelRPM_FR 65535 "SNA" ;
VAL_ 516 ControlEncodingRsp 171 "ControlEncoding_PVA" 170 "ControlEncoding_PRA" 153 "ControlEncoding_UC" 16 "ControlEncoding_TEN" ;
VAL_ 517 ControlEncodingRq 135 "ControlEncoding_ACK2p" 134 "ControlEncoding_ACK1p" 133 "ControlEncoding_ENQp" 132 "ControlEncoding_EOTp" 129 "ControlEncoding_NACKp" 21 "ControlEncoding_NACK" 6 "ControlEncoding_ACK" 5 "ControlEncoding_ENQ" ;
VAL_ 520 DriverDoorAjarXtionSts 3 "SNA" 2 "TRNS" 1 "NONE" ;
VAL_ 520 PsngrDoorAjarXtionSts 3 "SNA" 2 "TRNS" 1 "NONE" ;
VAL_ 520 DriverDoor2AjarXtionSts 3 "SNA" 2 "TRNS" 1 "NONE" ;
VAL_ 520 AC_OutptCurrStat 255 "SNA" ;
VAL_ 520 BrkPdlStat_CBC 3 "SNA" 2 "NDEF2" 1 "PSD" 0 "UPSTOP" ;
VAL_ 520 FOB_SrchLoc 15 "SNA" 12 "HOOD" 8 "PSG_LK" 4 "PSG_UNLK" 3 "TRUNK" 2 "DRV_LK" 1 "DRV_UNLK" 0 "NONE" ;
VAL_ 520 DriverDoorAjarRawValSts 15 "SNA" 14 "FH_SSE" 13 "FH_SSD" 12 "FH_SSC" 11 "FH_SSB" 10 "FH_SSA" 9 "CLOSED_SSB" 8 "CLOSED_SSA" 7 "OPEN_SSB" 6 "OPEN_SSA" 5 "FL_SSE" 4 "FL_SSD" 3 "FL_SSC" 2 "FL_SSB" 1 "FL_SSA" 0 "DEFAULT" ;
VAL_ 520 PsngrDoorAjarRawValSts 15 "SNA" 14 "FH_SSE" 13 "FH_SSD" 12 "FH_SSC" 11 "FH_SSB" 10 "FH_SSA" 9 "CLOSED_SSB" 8 "CLOSED_SSA" 7 "OPEN_SSB" 6 "OPEN_SSA" 5 "FL_SSE" 4 "FL_SSD" 3 "FL_SSC" 2 "FL_SSB" 1 "FL_SSA" 0 "DEFAULT" ;
VAL_ 520 DriverDoor2AjarRawValSts 15 "SNA" 14 "FH_SSE" 13 "FH_SSD" 12 "FH_SSC" 11 "FH_SSB" 10 "FH_SSA" 9 "CLOSED_SSB" 8 "CLOSED_SSA" 7 "OPEN_SSB" 6 "OPEN_SSA" 5 "FL_SSE" 4 "FL_SSD" 3 "FL_SSC" 2 "FL_SSB" 1 "FL_SSA" 0 "DEFAULT" ;
VAL_ 520 BonnetAjarRawValSts 15 "SNA" 14 "FH_SSE" 13 "FH_SSD" 12 "FH_SSC" 11 "FH_SSB" 10 "FH_SSA" 9 "CLOSED_SSB" 8 "CLOSED_SSA" 7 "OPEN_SSB" 6 "OPEN_SSA" 5 "FL_SSE" 4 "FL_SSD" 3 "FL_SSC" 2 "FL_SSB" 1 "FL_SSA" 0 "DEFAULT" ;
VAL_ 528 PsgSeatOCSts 15 "SNA" 4 "CLASS4" 3 "CLASS3" 1 "CLASS1" 0 "CLASS0" ;
VAL_ 528 PsgSeatSBRSts 15 "SNA" 1 "CLASS1" 0 "CLASS0" ;
